VERSION ""

NS_ :

BS_:

BU_: PowertrainControlModule AtmosphericSensor SafetyRestraintSystem2 Aftertreatment_2_GasOutlet Aftertreatment_2_GasIntake DieselParticulateFilterControl Turbocharger SafetyRestraintSystem1 CabDisplay2 Aftertreatment_1_GasOutlet Aftertreatment_1_GasIntake OnBoardDataLogger OffBoardDiagnosticTool2 OffBoardDiagnosticTool1 FileServer ParkingBrakeController SeatController2 FanDriveController SteeringColumnUnit CommunicationUnitRadio CommunicationUnitSatellite CommunicationUnitCellular PropulsionBatteryCharger ChassisController2 ChassisController1 EngineValveControl AuxiliaryHeater2 AuxiliaryHeater1 ClutchUnit RampControl InformationSystem1 SuspensionSystemController2 OilSensor VehicleDynamicStability ExhaustEmissionController TransmissionDisplay2 TransmissionDisplay1 ClimateControl2 WaterPumpController RearAxleSteeringController LightingOperatorControl SeatController1 IgnitionController2 IgnitionController1 TirePressureController CabController2 CabController1 PneumaticSystemController SuspensionSystemController1 HydraulicPumpController EnduranceBrakingSystem RetarderExhaustEngine2 OnBoardDiagnosticUnit HeadwayController RetarderExhaustEngine1 CabDisplay1 ManagementComputer VirtualTerminal OffVehicleGateway PowerTakeOffFront HitchControl AuxiliaryValveControl BodyController TractorTrailerBridge1 StarterSystem ElectricalSystem VehicleSecurity VehicleNavigation AerodynamicControl ElectricalChargingSystem ClimateControl1 TripRecorder InstrumentCluster SuspensionDriveAxle2 SuspensionDriveAxle1 SuspensionSteerAxle SteeringController FuelSystem CruiseControl RetarderDriveline RetarderEngine BrakesDriveAxle2 BrakesDriveAxle1 BrakesSystemController BrakesSteerAxle AxleDrive2 AxleDrive1 AxleSteering PowerTakeOff ShiftConsoleSecondary ShiftConsolePrimary Transmission2 Transmission1 Engine2 Engine1

BO_ 2566630654 DCAC_AI4_LD: 8 Vector__XXX
 SG_ TotalDCInputEnergy : 32|32@1+ (100,0) [0|421108121500] "Wh" Vector__XXX
 SG_ TotalDCInputCharge : 0|32@1+ (100,0) [0|421108121500] "Ah" Vector__XXX

BO_ 2566630398 DCAC_AI4_CFG1: 13 Vector__XXX
 SG_ ACSideDefaultFreqCmdSetting : 96|8@1+ (1,0) [0|250] "Hz" Vector__XXX
 SG_ DCSideCurMinLmtSetting : 80|16@1+ (0.05,-3212.75) [-3212.75|0] "A" Vector__XXX
 SG_ DCSideVMaxLmtSetting : 64|16@1+ (0.05,0) [0|3212.75] "V" Vector__XXX
 SG_ ACSideRMSCurMaxLmtSetting : 48|16@1+ (0.03125,0) [0|2007.96875] "A" Vector__XXX
 SG_ ACSideRMSVMaxLmtSetting : 32|16@1+ (0.03125,0) [0|2007.96875] "V" Vector__XXX
 SG_ DCSideCurMaxLmtSetting : 16|16@1+ (0.05,0) [0|3212.75] "A" Vector__XXX
 SG_ DCSideVMinLmtSetting : 0|16@1+ (0.05,0) [0|3212.75] "V" Vector__XXX

BO_ 2365303550 DCAC_AI4_ACL: 8 Vector__XXX
 SG_ DefaultFreqReq : 32|8@1+ (1,0) [0|250] "Hz" Vector__XXX
 SG_ RMSCurMaxLmtReq : 16|16@1+ (0.03125,0) [0|2007.96875] "A" Vector__XXX
 SG_ RMSVMaxLmtReq : 0|16@1+ (0.03125,0) [0|2007.96875] "V" Vector__XXX

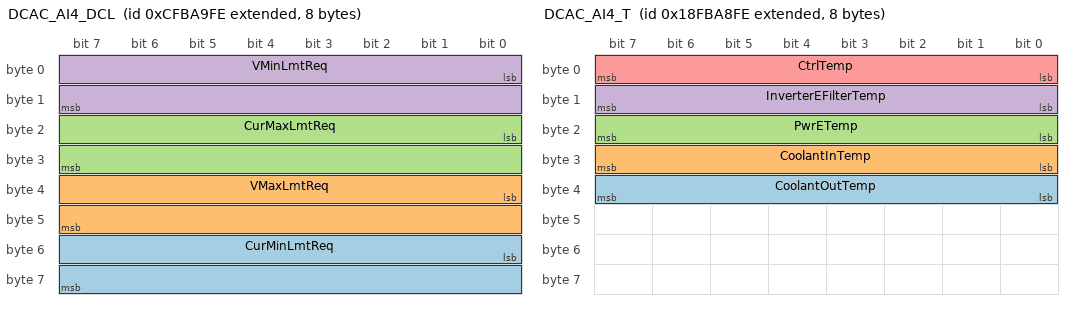
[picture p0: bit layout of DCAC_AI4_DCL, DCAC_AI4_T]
BO_ 2365303294 DCAC_AI4_DCL: 8 Vector__XXX
 SG_ CurMinLmtReq : 48|16@1+ (0.05,-3212.75) [-3212.75|0] "A" Vector__XXX
 SG_ VMaxLmtReq : 32|16@1+ (0.05,0) [0|3212.75] "V" Vector__XXX
 SG_ CurMaxLmtReq : 16|16@1+ (0.05,0) [0|3212.75] "A" Vector__XXX
 SG_ VMinLmtReq : 0|16@1+ (0.05,0) [0|3212.75] "V" Vector__XXX

BO_ 2566629630 DCAC_AI4_T: 8 Vector__XXX
 SG_ CoolantOutTemp : 32|8@1+ (1,-40) [-40|210] "°C" Vector__XXX
 SG_ CoolantInTemp : 24|8@1+ (1,-40) [-40|210] "°C" Vector__XXX
 SG_ PwrETemp : 16|8@1+ (1,-40) [-40|210] "°C" Vector__XXX
 SG_ InverterEFilterTemp : 8|8@1+ (1,-40) [-40|210] "°C" Vector__XXX
 SG_ CtrlTemp : 0|8@1+ (1,-40) [-40|210] "°C" Vector__XXX

BO_ 2566629374 DCAC_AI3_LD: 8 Vector__XXX
 SG_ TotalDCInputEnergy : 32|32@1+ (100,0) [0|421108121500] "Wh" Vector__XXX
 SG_ TotalDCInputCharge : 0|32@1+ (100,0) [0|421108121500] "Ah" Vector__XXX

BO_ 2566629118 DCAC_AI3_CFG1: 13 Vector__XXX
 SG_ ACSideDefaultFreqCmdSetting : 96|8@1+ (1,0) [0|250] "Hz" Vector__XXX
 SG_ DCSideCurMinLmtSetting : 80|16@1+ (0.05,-3212.75) [-3212.75|0] "A" Vector__XXX
 SG_ DCSideVMaxLmtSetting : 64|16@1+ (0.05,0) [0|3212.75] "V" Vector__XXX
 SG_ ACSideRMSCurMaxLmtSetting : 48|16@1+ (0.03125,0) [0|2007.96875] "A" Vector__XXX
 SG_ ACSideRMSVMaxLmtSetting : 32|16@1+ (0.03125,0) [0|2007.96875] "V" Vector__XXX
 SG_ DCSideCurMaxLmtSetting : 16|16@1+ (0.05,0) [0|3212.75] "A" Vector__XXX
 SG_ DCSideVMinLmtSetting : 0|16@1+ (0.05,0) [0|3212.75] "V" Vector__XXX

BO_ 2365302270 DCAC_AI3_ACL: 8 Vector__XXX
 SG_ DefaultFreqReq : 32|8@1+ (1,0) [0|250] "Hz" Vector__XXX
 SG_ RMSCurMaxLmtReq : 16|16@1+ (0.03125,0) [0|2007.96875] "A" Vector__XXX
 SG_ RMSVMaxLmtReq : 0|16@1+ (0.03125,0) [0|2007.96875] "V" Vector__XXX

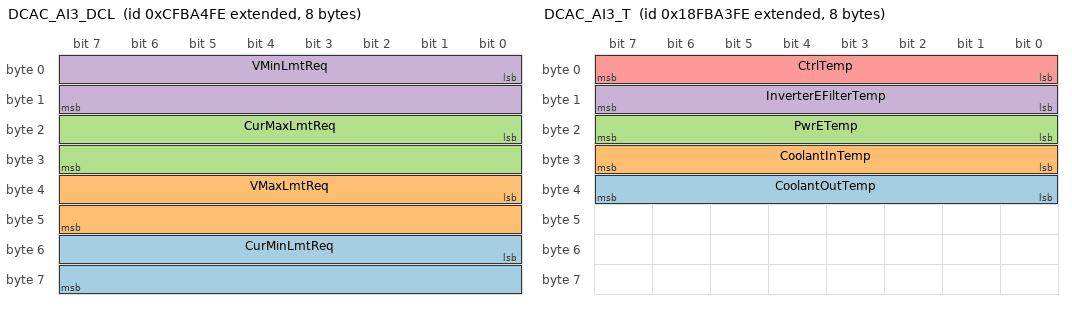
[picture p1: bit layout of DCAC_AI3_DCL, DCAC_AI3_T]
BO_ 2365302014 DCAC_AI3_DCL: 8 Vector__XXX
 SG_ CurMinLmtReq : 48|16@1+ (0.05,-3212.75) [-3212.75|0] "A" Vector__XXX
 SG_ VMaxLmtReq : 32|16@1+ (0.05,0) [0|3212.75] "V" Vector__XXX
 SG_ CurMaxLmtReq : 16|16@1+ (0.05,0) [0|3212.75] "A" Vector__XXX
 SG_ VMinLmtReq : 0|16@1+ (0.05,0) [0|3212.75] "V" Vector__XXX

BO_ 2566628350 DCAC_AI3_T: 8 Vector__XXX
 SG_ CoolantOutTemp : 32|8@1+ (1,-40) [-40|210] "°C" Vector__XXX
 SG_ CoolantInTemp : 24|8@1+ (1,-40) [-40|210] "°C" Vector__XXX
 SG_ PwrETemp : 16|8@1+ (1,-40) [-40|210] "°C" Vector__XXX
 SG_ InverterEFilterTemp : 8|8@1+ (1,-40) [-40|210] "°C" Vector__XXX
 SG_ CtrlTemp : 0|8@1+ (1,-40) [-40|210] "°C" Vector__XXX

BO_ 2566628094 DCAC_AI2_LD: 8 Vector__XXX
 SG_ TotalDCInputEnergy : 32|32@1+ (100,0) [0|421108121500] "Wh" Vector__XXX
 SG_ TotalDCInputCharge : 0|32@1+ (100,0) [0|421108121500] "Ah" Vector__XXX

BO_ 2566627838 DCAC_AI2_CFG1: 13 Vector__XXX
 SG_ ACSideDefaultFreqCmdSetting : 96|8@1+ (1,0) [0|250] "Hz" Vector__XXX
 SG_ DCSideCurMinLmtSetting : 80|16@1+ (0.05,-3212.75) [-3212.75|0] "A" Vector__XXX
 SG_ DCSideVMaxLmtSetting : 64|16@1+ (0.05,0) [0|3212.75] "V" Vector__XXX
 SG_ ACSideRMSCurMaxLmtSetting : 48|16@1+ (0.03125,0) [0|2007.96875] "A" Vector__XXX
 SG_ ACSideRMSVMaxLmtSetting : 32|16@1+ (0.03125,0) [0|2007.96875] "V" Vector__XXX
 SG_ DCSideCurMaxLmtSetting : 16|16@1+ (0.05,0) [0|3212.75] "A" Vector__XXX
 SG_ DCSideVMinLmtSetting : 0|16@1+ (0.05,0) [0|3212.75] "V" Vector__XXX

BO_ 2365300990 DCAC_AI2_ACL: 8 Vector__XXX
 SG_ DefaultFreqReq : 32|8@1+ (1,0) [0|250] "Hz" Vector__XXX
 SG_ RMSCurMaxLmtReq : 16|16@1+ (0.03125,0) [0|2007.96875] "A" Vector__XXX
 SG_ RMSVMaxLmtReq : 0|16@1+ (0.03125,0) [0|2007.96875] "V" Vector__XXX

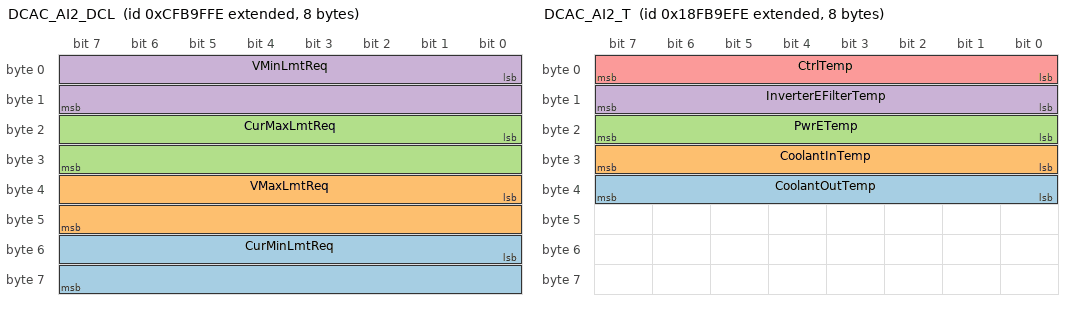
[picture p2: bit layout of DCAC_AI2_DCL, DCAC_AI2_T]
BO_ 2365300734 DCAC_AI2_DCL: 8 Vector__XXX
 SG_ CurMinLmtReq : 48|16@1+ (0.05,-3212.75) [-3212.75|0] "A" Vector__XXX
 SG_ VMaxLmtReq : 32|16@1+ (0.05,0) [0|3212.75] "V" Vector__XXX
 SG_ CurMaxLmtReq : 16|16@1+ (0.05,0) [0|3212.75] "A" Vector__XXX
 SG_ VMinLmtReq : 0|16@1+ (0.05,0) [0|3212.75] "V" Vector__XXX

BO_ 2566627070 DCAC_AI2_T: 8 Vector__XXX
 SG_ CoolantOutTemp : 32|8@1+ (1,-40) [-40|210] "°C" Vector__XXX
 SG_ CoolantInTemp : 24|8@1+ (1,-40) [-40|210] "°C" Vector__XXX
 SG_ PwrETemp : 16|8@1+ (1,-40) [-40|210] "°C" Vector__XXX
 SG_ InverterEFilterTemp : 8|8@1+ (1,-40) [-40|210] "°C" Vector__XXX
 SG_ CtrlTemp : 0|8@1+ (1,-40) [-40|210] "°C" Vector__XXX

BO_ 2566626814 DCAC_AI1_LD: 8 Vector__XXX
 SG_ TotalDCInputEnergy : 32|32@1+ (100,0) [0|421108121500] "Wh" Vector__XXX
 SG_ TotalDCInputCharge : 0|32@1+ (100,0) [0|421108121500] "Ah" Vector__XXX

BO_ 2566626558 DCAC_AI1_CFG1: 13 Vector__XXX
 SG_ ACSideDefaultFreqCmdSetting : 96|8@1+ (1,0) [0|250] "Hz" Vector__XXX
 SG_ DCSideCurMinLmtSetting : 80|16@1+ (0.05,-3212.75) [-3212.75|0] "A" Vector__XXX
 SG_ DCSideVMaxLmtSetting : 64|16@1+ (0.05,0) [0|3212.75] "V" Vector__XXX
 SG_ ACSideRMSCurMaxLmtSetting : 48|16@1+ (0.03125,0) [0|2007.96875] "A" Vector__XXX
 SG_ ACSideRMSVMaxLmtSetting : 32|16@1+ (0.03125,0) [0|2007.96875] "V" Vector__XXX
 SG_ DCSideCurMaxLmtSetting : 16|16@1+ (0.05,0) [0|3212.75] "A" Vector__XXX
 SG_ DCSideVMinLmtSetting : 0|16@1+ (0.05,0) [0|3212.75] "V" Vector__XXX

BO_ 2365299710 DCAC_AI1_ACL: 8 Vector__XXX
 SG_ DefaultFreqReq : 32|8@1+ (1,0) [0|250] "Hz" Vector__XXX
 SG_ RMSCurMaxLmtReq : 16|16@1+ (0.03125,0) [0|2007.96875] "A" Vector__XXX
 SG_ RMSVMaxLmtReq : 0|16@1+ (0.03125,0) [0|2007.96875] "V" Vector__XXX

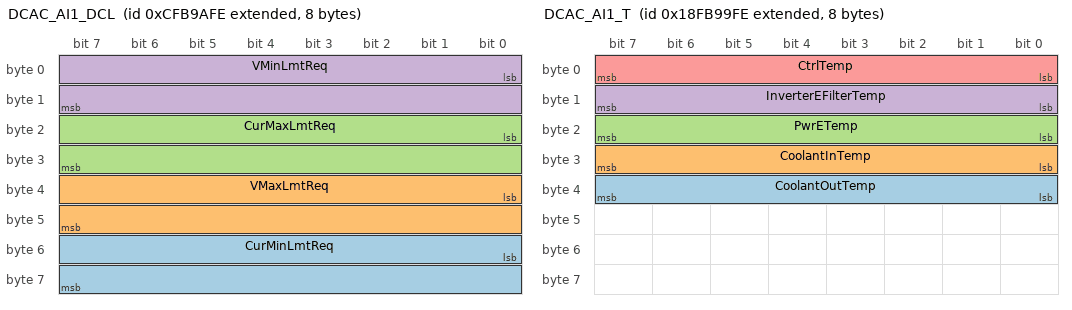
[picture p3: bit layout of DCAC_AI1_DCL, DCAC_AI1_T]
BO_ 2365299454 DCAC_AI1_DCL: 8 Vector__XXX
 SG_ CurMinLmtReq : 48|16@1+ (0.05,-3212.75) [-3212.75|0] "A" Vector__XXX
 SG_ VMaxLmtReq : 32|16@1+ (0.05,0) [0|3212.75] "V" Vector__XXX
 SG_ CurMaxLmtReq : 16|16@1+ (0.05,0) [0|3212.75] "A" Vector__XXX
 SG_ VMinLmtReq : 0|16@1+ (0.05,0) [0|3212.75] "V" Vector__XXX

BO_ 2566625790 DCAC_AI1_T: 8 Vector__XXX
 SG_ CoolantOutTemp : 32|8@1+ (1,-40) [-40|210] "°C" Vector__XXX
 SG_ CoolantInTemp : 24|8@1+ (1,-40) [-40|210] "°C" Vector__XXX
 SG_ PwrETemp : 16|8@1+ (1,-40) [-40|210] "°C" Vector__XXX
 SG_ InverterEFilterTemp : 8|8@1+ (1,-40) [-40|210] "°C" Vector__XXX
 SG_ CtrlTemp : 0|8@1+ (1,-40) [-40|210] "°C" Vector__XXX

BO_ 2633734398 EO2: 8 Vector__XXX
 SG_ EngActualExh2O2 : 0|16@1+ (0.0025,0) [0|160.6375] "%" Vector__XXX

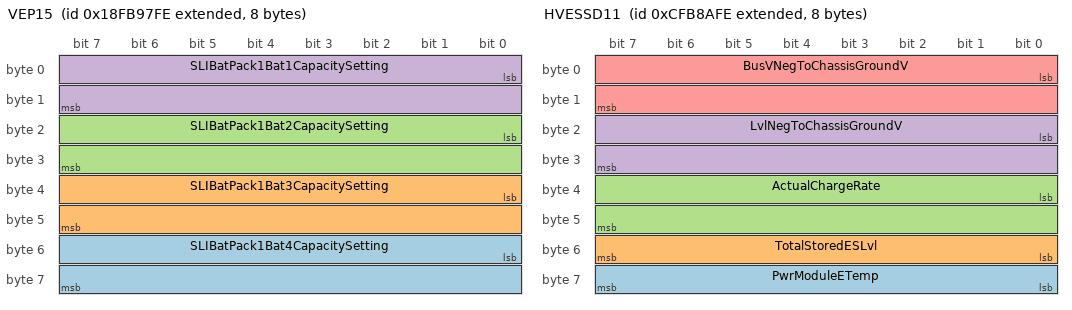
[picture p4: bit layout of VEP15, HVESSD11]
BO_ 2566625278 VEP15: 8 Vector__XXX
 SG_ SLIBatPack1Bat4CapacitySetting : 48|16@1+ (1,0) [0|64255] "Ah" Vector__XXX
 SG_ SLIBatPack1Bat3CapacitySetting : 32|16@1+ (1,0) [0|64255] "Ah" Vector__XXX
 SG_ SLIBatPack1Bat2CapacitySetting : 16|16@1+ (1,0) [0|64255] "Ah" Vector__XXX
 SG_ SLIBatPack1Bat1CapacitySetting : 0|16@1+ (1,0) [0|64255] "Ah" Vector__XXX

BO_ 2566625022 EI3: 8 Vector__XXX
 SG_ ExhManifoldBank1Press2 : 16|16@1+ (0.0078125,-250) [-250|251.9921875] "kPa" Vector__XXX
 SG_ InstantaneousEstEngPwrRateLmt : 0|16@1+ (0.125,0) [0|8031.875] "kW/s" Vector__XXX

BO_ 2566624766 HOURS2: 8 Vector__XXX
 SG_ IdleMnmgtActiveTotalTime : 0|32@1+ (0.05,0) [0|210554060.75] "h" Vector__XXX

BO_ 2566624510 EEC22: 8 Vector__XXX
 SG_ TotalNumOfCrankAttempts : 16|32@1+ (1,0) [0|4211081215] "" Vector__XXX
 SG_ EGR1CoolerInPress : 0|16@1+ (5,0) [0|321275] "kPa" Vector__XXX

BO_ 2365297662 DCDC1V: 8 Vector__XXX
 SG_ OneCtrlInputSLIV : 16|16@1+ (0.05,0) [0|3212.75] "V" Vector__XXX
 SG_ OneCtrlInputIgntV : 0|16@1+ (0.05,0) [0|3212.75] "V" Vector__XXX

BO_ 2365297406 DCDC2V: 8 Vector__XXX
 SG_ TwoCtrlInputSLIV : 16|16@1+ (0.05,0) [0|3212.75] "V" Vector__XXX
 SG_ TwoCtrlInputIgntV : 0|16@1+ (0.05,0) [0|3212.75] "V" Vector__XXX

BO_ 2365297150 DCDC3V: 8 Vector__XXX
 SG_ ThreeCtrlInputSLIV : 16|16@1+ (0.05,0) [0|3212.75] "V" Vector__XXX
 SG_ ThreeCtrlInputIgntV : 0|16@1+ (0.05,0) [0|3212.75] "V" Vector__XXX

BO_ 2365296894 DCDC4V: 8 Vector__XXX
 SG_ FourCtrlInputSLIV : 16|16@1+ (0.05,0) [0|3212.75] "V" Vector__XXX
 SG_ FourCtrlInputIgntV : 0|16@1+ (0.05,0) [0|3212.75] "V" Vector__XXX

BO_ 2566623230 EMEFS: 8 Vector__XXX
 SG_ TripEstFuelSaved : 32|32@1+ (0.5,0) [0|2105540607.5] "l" Vector__XXX
 SG_ TotalEstFuelSaved : 0|32@1+ (0.5,0) [0|2105540607.5] "l" Vector__XXX

BO_ 2566622974 EMFU: 8 Vector__XXX
 SG_ TripFuelUsed : 32|32@1+ (0.5,0) [0|2105540607.5] "l" Vector__XXX
 SG_ TotalFuelUsed : 0|32@1+ (0.5,0) [0|2105540607.5] "l" Vector__XXX

BO_ 2566622718 EMAH: 8 Vector__XXX
 SG_ TripHoursActive : 32|32@1+ (0.05,0) [0|210554060.75] "h" Vector__XXX
 SG_ TotalHoursActive : 0|32@1+ (0.05,0) [0|210554060.75] "h" Vector__XXX

BO_ 2566622462 EMEIFSR: 8 Vector__XXX
 SG_ Percent : 16|16@1+ (0.0025,0) [0|160.6375] "%" Vector__XXX
 SG_ RateAbsolute : 0|16@1+ (0.05,0) [0|3212.75] "l/h" Vector__XXX

BO_ 2566622206 EMIH: 8 Vector__XXX
 SG_ TripHoursInactive : 32|32@1+ (0.05,0) [0|210554060.75] "h" Vector__XXX
 SG_ TotalHoursInactive : 0|32@1+ (0.05,0) [0|210554060.75] "h" Vector__XXX

BO_ 2365295358 HVESSD11: 8 Vector__XXX
 SG_ PwrModuleETemp : 56|8@1+ (1,-40) [-40|210] "°C" Vector__XXX
 SG_ TotalStoredESLvl : 48|8@1+ (0.4,0) [0|100] "%" Vector__XXX
 SG_ ActualChargeRate : 32|16@1+ (0.05,0) [0|3212.75] "kW" Vector__XXX
 SG_ LvlNegToChassisGroundV : 16|16@1+ (0.05,0) [0|3212.75] "V" Vector__XXX
 SG_ BusVNegToChassisGroundV : 0|16@1+ (0.05,0) [0|3212.75] "V" Vector__XXX

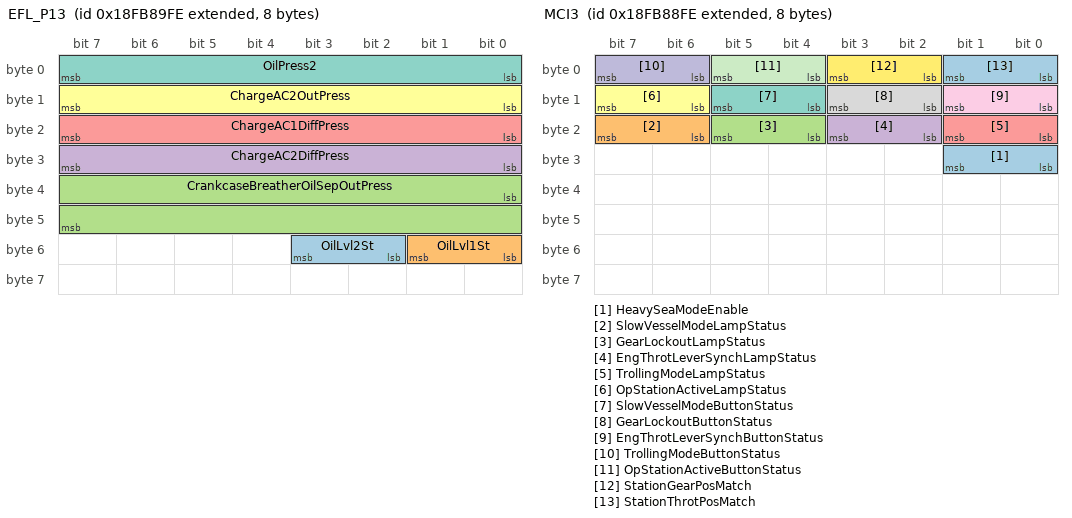
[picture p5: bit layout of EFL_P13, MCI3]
BO_ 2566621694 EFL_P13: 8 Vector__XXX
 SG_ OilLvl2St : 50|2@1+ (1,0) [0|3] "" Vector__XXX
 SG_ OilLvl1St : 48|2@1+ (1,0) [0|3] "" Vector__XXX
 SG_ CrankcaseBreatherOilSepOutPress : 32|16@1+ (0.0078125,-250) [-250|251.9921875] "kPa" Vector__XXX
 SG_ ChargeAC2DiffPress : 24|8@1+ (0.5,0) [0|125] "kPa" Vector__XXX
 SG_ ChargeAC1DiffPress : 16|8@1+ (0.5,0) [0|125] "kPa" Vector__XXX
 SG_ ChargeAC2OutPress : 8|8@1+ (2,0) [0|500] "kPa" Vector__XXX
 SG_ OilPress2 : 0|8@1+ (4,0) [0|1000] "kPa" Vector__XXX

BO_ 2566621438 MCI3: 8 Vector__XXX
 SG_ HeavySeaModeEnable : 24|2@1+ (1,0) [0|3] "" Vector__XXX
 SG_ SlowVesselModeLampStatus : 22|2@1+ (1,0) [0|3] "" Vector__XXX
 SG_ GearLockoutLampStatus : 20|2@1+ (1,0) [0|3] "" Vector__XXX
 SG_ EngThrotLeverSynchLampStatus : 18|2@1+ (1,0) [0|3] "" Vector__XXX
 SG_ TrollingModeLampStatus : 16|2@1+ (1,0) [0|3] "" Vector__XXX
 SG_ OpStationActiveLampStatus : 14|2@1+ (1,0) [0|3] "" Vector__XXX
 SG_ SlowVesselModeButtonStatus : 12|2@1+ (1,0) [0|3] "" Vector__XXX
 SG_ GearLockoutButtonStatus : 10|2@1+ (1,0) [0|3] "" Vector__XXX
 SG_ EngThrotLeverSynchButtonStatus : 8|2@1+ (1,0) [0|3] "" Vector__XXX
 SG_ TrollingModeButtonStatus : 6|2@1+ (1,0) [0|3] "" Vector__XXX
 SG_ OpStationActiveButtonStatus : 4|2@1+ (1,0) [0|3] "" Vector__XXX
 SG_ StationGearPosMatch : 2|2@1+ (1,0) [0|3] "" Vector__XXX
 SG_ StationThrotPosMatch : 0|2@1+ (1,0) [0|3] "" Vector__XXX

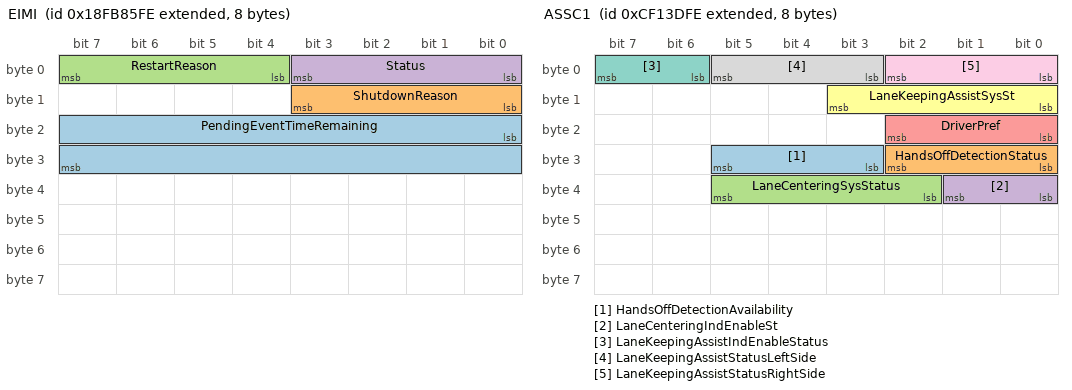
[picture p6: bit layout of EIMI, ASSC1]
BO_ 2566620670 EIMI: 8 Vector__XXX
 SG_ PendingEventTimeRemaining : 16|16@1+ (1,0) [0|64255] "s" Vector__XXX
 SG_ ShutdownReason : 8|4@1+ (1,0) [0|15] "" Vector__XXX
 SG_ RestartReason : 4|4@1+ (1,0) [0|15] "" Vector__XXX
 SG_ Status : 0|4@1+ (1,0) [0|15] "" Vector__XXX

BO_ 2364620286 ASSC1: 8 Vector__XXX
 SG_ HandsOffDetectionAvailability : 27|3@1+ (1,0) [0|7] "" Vector__XXX
 SG_ HandsOffDetectionStatus : 24|3@1+ (1,0) [0|7] "" Vector__XXX
 SG_ LaneCenteringSysStatus : 34|4@1+ (1,0) [0|15] "" Vector__XXX
 SG_ LaneCenteringIndEnableSt : 32|2@1+ (1,0) [0|3] "" Vector__XXX
 SG_ DriverPref : 16|3@1+ (1,0) [0|7] "" Vector__XXX
 SG_ LaneKeepingAssistSysSt : 8|4@1+ (1,0) [0|15] "" Vector__XXX
 SG_ LaneKeepingAssistIndEnableStatus : 6|2@1+ (1,0) [0|3] "" Vector__XXX
 SG_ LaneKeepingAssistStatusLeftSide : 3|3@1+ (1,0) [0|7] "" Vector__XXX
 SG_ LaneKeepingAssistStatusRightSide : 0|3@1+ (1,0) [0|7] "" Vector__XXX

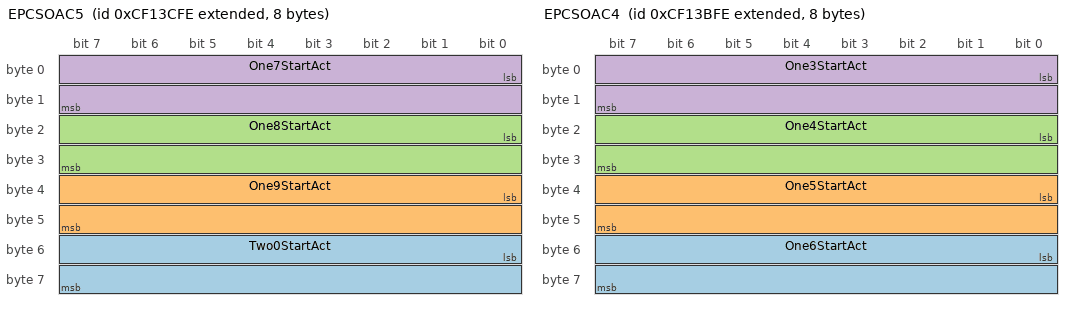
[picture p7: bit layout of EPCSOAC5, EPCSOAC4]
BO_ 2364620030 EPCSOAC5: 8 Vector__XXX
 SG_ Two0StartAct : 48|16@1+ (0.0078125,-400) [-400|101.9921875] "deg" Vector__XXX
 SG_ One9StartAct : 32|16@1+ (0.0078125,-400) [-400|101.9921875] "deg" Vector__XXX
 SG_ One8StartAct : 16|16@1+ (0.0078125,-400) [-400|101.9921875] "deg" Vector__XXX
 SG_ One7StartAct : 0|16@1+ (0.0078125,-400) [-400|101.9921875] "deg" Vector__XXX

BO_ 2364619774 EPCSOAC4: 8 Vector__XXX
 SG_ One6StartAct : 48|16@1+ (0.0078125,-400) [-400|101.9921875] "deg" Vector__XXX
 SG_ One5StartAct : 32|16@1+ (0.0078125,-400) [-400|101.9921875] "deg" Vector__XXX
 SG_ One4StartAct : 16|16@1+ (0.0078125,-400) [-400|101.9921875] "deg" Vector__XXX
 SG_ One3StartAct : 0|16@1+ (0.0078125,-400) [-400|101.9921875] "deg" Vector__XXX

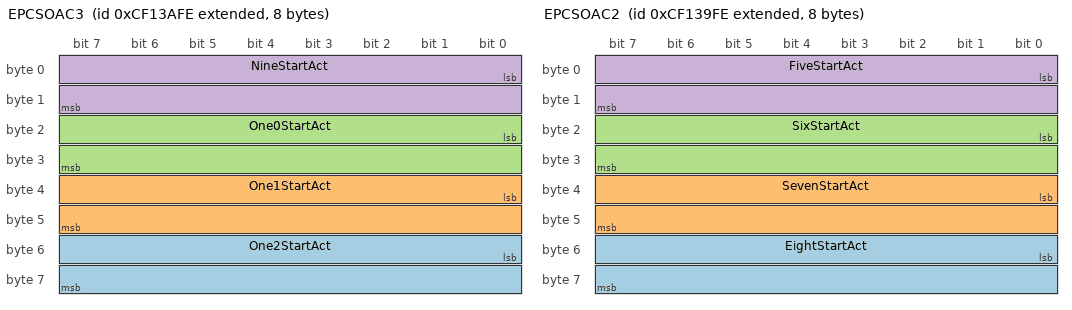
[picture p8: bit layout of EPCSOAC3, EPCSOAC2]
BO_ 2364619518 EPCSOAC3: 8 Vector__XXX
 SG_ One2StartAct : 48|16@1+ (0.0078125,-400) [-400|101.9921875] "deg" Vector__XXX
 SG_ One1StartAct : 32|16@1+ (0.0078125,-400) [-400|101.9921875] "deg" Vector__XXX
 SG_ One0StartAct : 16|16@1+ (0.0078125,-400) [-400|101.9921875] "deg" Vector__XXX
 SG_ NineStartAct : 0|16@1+ (0.0078125,-400) [-400|101.9921875] "deg" Vector__XXX

BO_ 2364619262 EPCSOAC2: 8 Vector__XXX
 SG_ EightStartAct : 48|16@1+ (0.0078125,-400) [-400|101.9921875] "deg" Vector__XXX
 SG_ SevenStartAct : 32|16@1+ (0.0078125,-400) [-400|101.9921875] "deg" Vector__XXX
 SG_ SixStartAct : 16|16@1+ (0.0078125,-400) [-400|101.9921875] "deg" Vector__XXX
 SG_ FiveStartAct : 0|16@1+ (0.0078125,-400) [-400|101.9921875] "deg" Vector__XXX

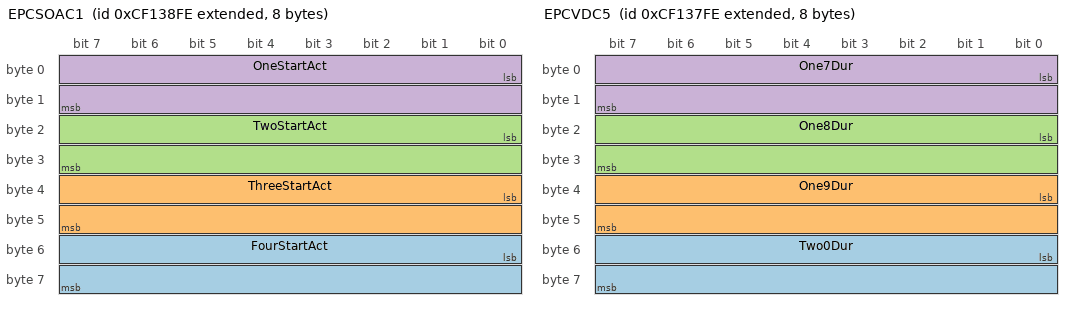
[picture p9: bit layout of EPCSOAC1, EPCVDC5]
BO_ 2364619006 EPCSOAC1: 8 Vector__XXX
 SG_ FourStartAct : 48|16@1+ (0.0078125,-400) [-400|101.9921875] "deg" Vector__XXX
 SG_ ThreeStartAct : 32|16@1+ (0.0078125,-400) [-400|101.9921875] "deg" Vector__XXX
 SG_ TwoStartAct : 16|16@1+ (0.0078125,-400) [-400|101.9921875] "deg" Vector__XXX
 SG_ OneStartAct : 0|16@1+ (0.0078125,-400) [-400|101.9921875] "deg" Vector__XXX

BO_ 2364618750 EPCVDC5: 8 Vector__XXX
 SG_ Two0Dur : 48|16@1+ (2,0) [0|128510] "µs" Vector__XXX
 SG_ One9Dur : 32|16@1+ (2,0) [0|128510] "µs" Vector__XXX
 SG_ One8Dur : 16|16@1+ (2,0) [0|128510] "µs" Vector__XXX
 SG_ One7Dur : 0|16@1+ (2,0) [0|128510] "µs" Vector__XXX

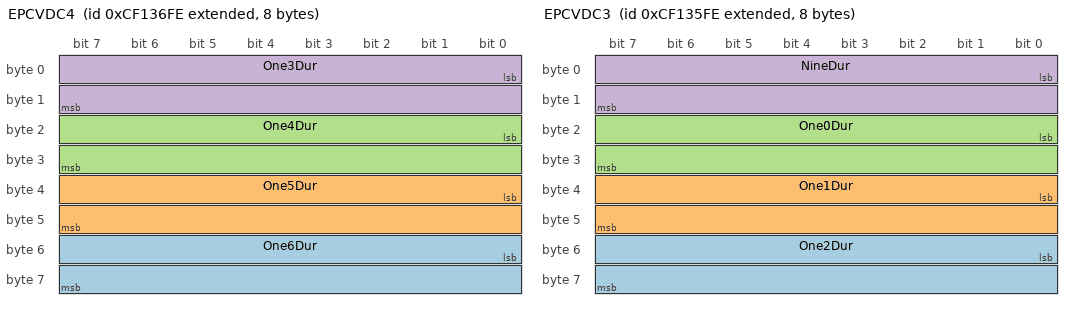
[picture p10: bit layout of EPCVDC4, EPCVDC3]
BO_ 2364618494 EPCVDC4: 8 Vector__XXX
 SG_ One6Dur : 48|16@1+ (2,0) [0|128510] "µs" Vector__XXX
 SG_ One5Dur : 32|16@1+ (2,0) [0|128510] "µs" Vector__XXX
 SG_ One4Dur : 16|16@1+ (2,0) [0|128510] "µs" Vector__XXX
 SG_ One3Dur : 0|16@1+ (2,0) [0|128510] "µs" Vector__XXX

BO_ 2364618238 EPCVDC3: 8 Vector__XXX
 SG_ One2Dur : 48|16@1+ (2,0) [0|128510] "µs" Vector__XXX
 SG_ One1Dur : 32|16@1+ (2,0) [0|128510] "µs" Vector__XXX
 SG_ One0Dur : 16|16@1+ (2,0) [0|128510] "µs" Vector__XXX
 SG_ NineDur : 0|16@1+ (2,0) [0|128510] "µs" Vector__XXX

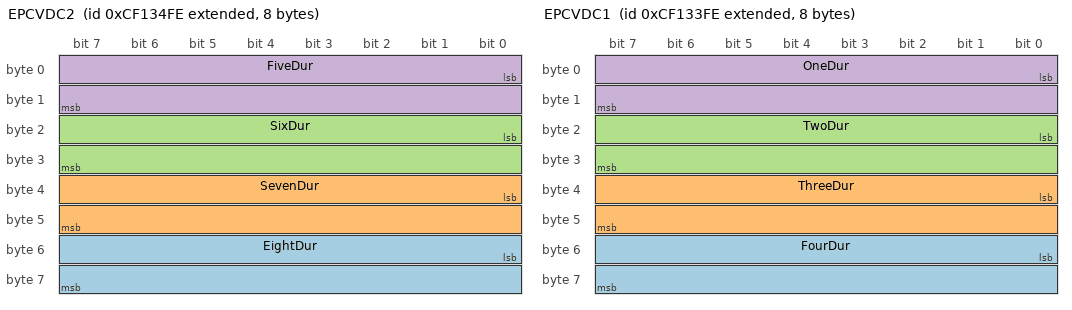
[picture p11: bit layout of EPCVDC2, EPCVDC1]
BO_ 2364617982 EPCVDC2: 8 Vector__XXX
 SG_ EightDur : 48|16@1+ (2,0) [0|128510] "µs" Vector__XXX
 SG_ SevenDur : 32|16@1+ (2,0) [0|128510] "µs" Vector__XXX
 SG_ SixDur : 16|16@1+ (2,0) [0|128510] "µs" Vector__XXX
 SG_ FiveDur : 0|16@1+ (2,0) [0|128510] "µs" Vector__XXX

BO_ 2364617726 EPCVDC1: 8 Vector__XXX
 SG_ FourDur : 48|16@1+ (2,0) [0|128510] "µs" Vector__XXX
 SG_ ThreeDur : 32|16@1+ (2,0) [0|128510] "µs" Vector__XXX
 SG_ TwoDur : 16|16@1+ (2,0) [0|128510] "µs" Vector__XXX
 SG_ OneDur : 0|16@1+ (2,0) [0|128510] "µs" Vector__XXX

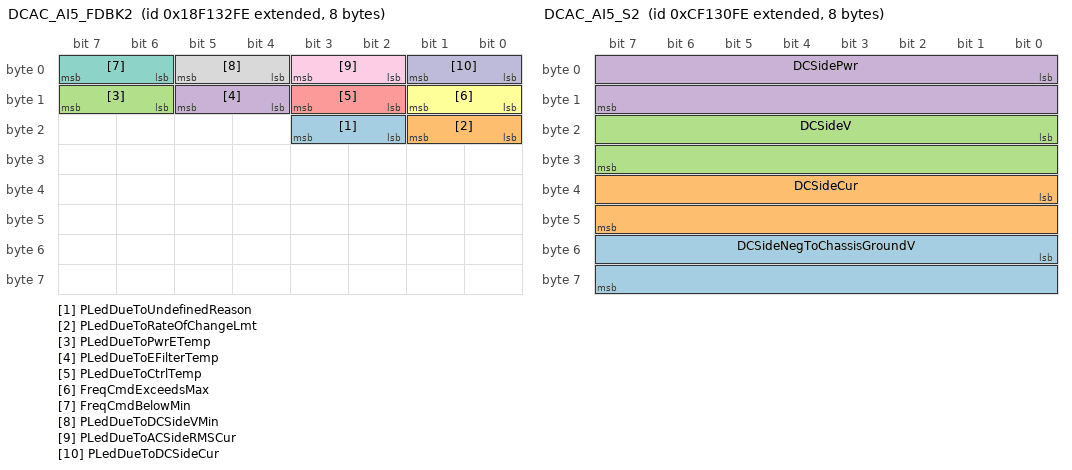
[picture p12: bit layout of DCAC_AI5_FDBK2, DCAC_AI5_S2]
BO_ 2565944062 DCAC_AI5_FDBK2: 8 Vector__XXX
 SG_ PLedDueToUndefinedReason : 18|2@1+ (1,0) [0|3] "" Vector__XXX
 SG_ PLedDueToRateOfChangeLmt : 16|2@1+ (1,0) [0|3] "" Vector__XXX
 SG_ PLedDueToPwrETemp : 14|2@1+ (1,0) [0|3] "" Vector__XXX
 SG_ PLedDueToEFilterTemp : 12|2@1+ (1,0) [0|3] "" Vector__XXX
 SG_ PLedDueToCtrlTemp : 10|2@1+ (1,0) [0|3] "" Vector__XXX
 SG_ FreqCmdExceedsMax : 8|2@1+ (1,0) [0|3] "" Vector__XXX
 SG_ FreqCmdBelowMin : 6|2@1+ (1,0) [0|3] "" Vector__XXX
 SG_ PLedDueToDCSideVMin : 4|2@1+ (1,0) [0|3] "" Vector__XXX
 SG_ PLedDueToACSideRMSCur : 2|2@1+ (1,0) [0|3] "" Vector__XXX
 SG_ PLedDueToDCSideCur : 0|2@1+ (1,0) [0|3] "" Vector__XXX

BO_ 2364617214 DCAC_AI5_V: 8 Vector__XXX
 SG_ SLIV : 16|16@1+ (0.05,0) [0|3212.75] "V" Vector__XXX
 SG_ IgntV : 0|16@1+ (0.05,0) [0|3212.75] "V" Vector__XXX

BO_ 2364616958 DCAC_AI5_S2: 8 Vector__XXX
 SG_ DCSideNegToChassisGroundV : 48|16@1+ (0.05,0) [0|3212.75] "V" Vector__XXX
 SG_ DCSideCur : 32|16@1+ (0.0625,0) [0|4015.9375] "A" Vector__XXX
 SG_ DCSideV : 16|16@1+ (0.05,0) [0|3212.75] "V" Vector__XXX
 SG_ DCSidePwr : 0|16@1+ (0.0625,0) [0|4015.9375] "kW" Vector__XXX

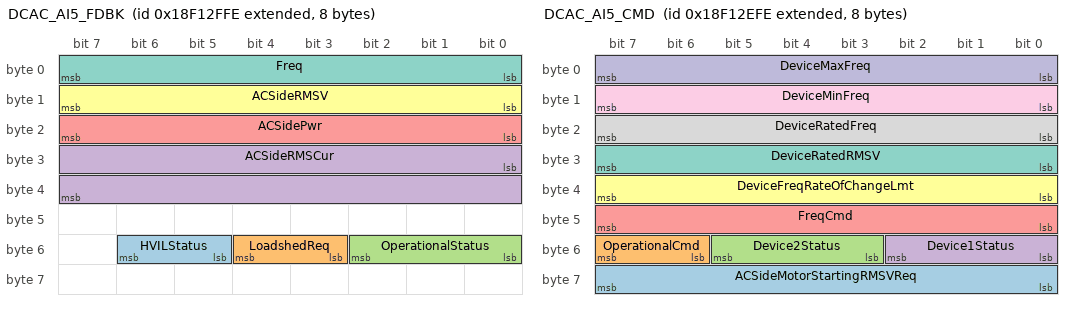
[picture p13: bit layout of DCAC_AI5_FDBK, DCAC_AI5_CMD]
BO_ 2565943294 DCAC_AI5_FDBK: 8 Vector__XXX
 SG_ HVILStatus : 53|2@1+ (1,0) [0|3] "" Vector__XXX
 SG_ LoadshedReq : 51|2@1+ (1,0) [0|3] "" Vector__XXX
 SG_ OperationalStatus : 48|3@1+ (1,0) [0|7] "" Vector__XXX
 SG_ ACSideRMSCur : 24|16@1+ (0.03125,0) [0|2007.96875] "A" Vector__XXX
 SG_ ACSidePwr : 16|8@1+ (0.1,0) [0|25] "kW" Vector__XXX
 SG_ ACSideRMSV : 8|8@1+ (2,0) [0|500] "V" Vector__XXX
 SG_ Freq : 0|8@1+ (1,0) [0|250] "Hz" Vector__XXX

BO_ 2565943038 DCAC_AI5_CMD: 8 Vector__XXX
 SG_ ACSideMotorStartingRMSVReq : 56|8@1+ (2,0) [0|500] "V" Vector__XXX
 SG_ OperationalCmd : 54|2@1+ (1,0) [0|3] "" Vector__XXX
 SG_ Device2Status : 51|3@1+ (1,0) [0|7] "" Vector__XXX
 SG_ Device1Status : 48|3@1+ (1,0) [0|7] "" Vector__XXX
 SG_ FreqCmd : 40|8@1+ (1,0) [0|250] "Hz" Vector__XXX
 SG_ DeviceFreqRateOfChangeLmt : 32|8@1+ (2,0) [0|500] "Hz/s" Vector__XXX
 SG_ DeviceRatedRMSV : 24|8@1+ (2,0) [0|500] "V" Vector__XXX
 SG_ DeviceRatedFreq : 16|8@1+ (1,0) [0|250] "Hz" Vector__XXX
 SG_ DeviceMinFreq : 8|8@1+ (1,0) [0|250] "Hz" Vector__XXX
 SG_ DeviceMaxFreq : 0|8@1+ (1,0) [0|250] "Hz" Vector__XXX

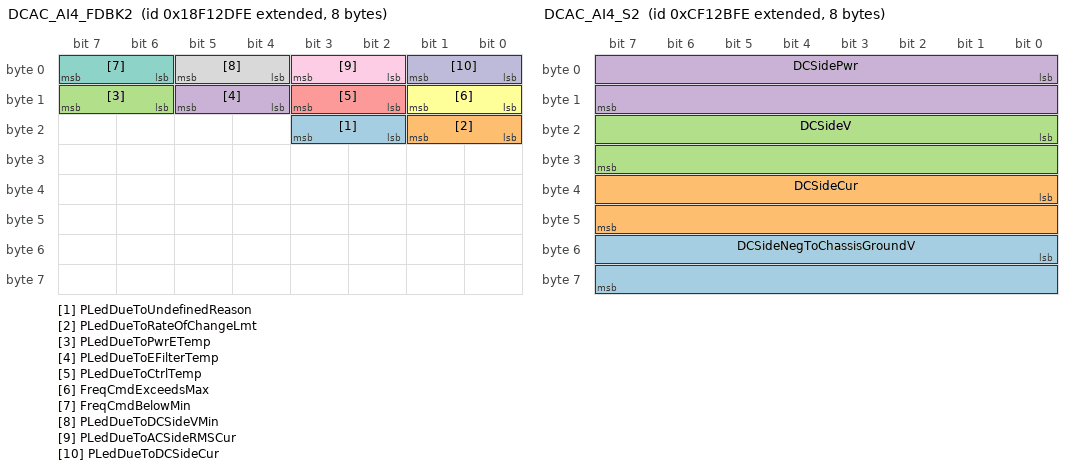
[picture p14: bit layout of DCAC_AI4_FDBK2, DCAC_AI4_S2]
BO_ 2565942782 DCAC_AI4_FDBK2: 8 Vector__XXX
 SG_ PLedDueToUndefinedReason : 18|2@1+ (1,0) [0|3] "" Vector__XXX
 SG_ PLedDueToRateOfChangeLmt : 16|2@1+ (1,0) [0|3] "" Vector__XXX
 SG_ PLedDueToPwrETemp : 14|2@1+ (1,0) [0|3] "" Vector__XXX
 SG_ PLedDueToEFilterTemp : 12|2@1+ (1,0) [0|3] "" Vector__XXX
 SG_ PLedDueToCtrlTemp : 10|2@1+ (1,0) [0|3] "" Vector__XXX
 SG_ FreqCmdExceedsMax : 8|2@1+ (1,0) [0|3] "" Vector__XXX
 SG_ FreqCmdBelowMin : 6|2@1+ (1,0) [0|3] "" Vector__XXX
 SG_ PLedDueToDCSideVMin : 4|2@1+ (1,0) [0|3] "" Vector__XXX
 SG_ PLedDueToACSideRMSCur : 2|2@1+ (1,0) [0|3] "" Vector__XXX
 SG_ PLedDueToDCSideCur : 0|2@1+ (1,0) [0|3] "" Vector__XXX

BO_ 2364615934 DCAC_AI4_V: 8 Vector__XXX
 SG_ SLIV : 16|16@1+ (0.05,0) [0|3212.75] "V" Vector__XXX
 SG_ IgntV : 0|16@1+ (0.05,0) [0|3212.75] "V" Vector__XXX

BO_ 2364615678 DCAC_AI4_S2: 8 Vector__XXX
 SG_ DCSideNegToChassisGroundV : 48|16@1+ (0.05,0) [0|3212.75] "V" Vector__XXX
 SG_ DCSideCur : 32|16@1+ (0.0625,0) [0|4015.9375] "A" Vector__XXX
 SG_ DCSideV : 16|16@1+ (0.05,0) [0|3212.75] "V" Vector__XXX
 SG_ DCSidePwr : 0|16@1+ (0.0625,0) [0|4015.9375] "kW" Vector__XXX

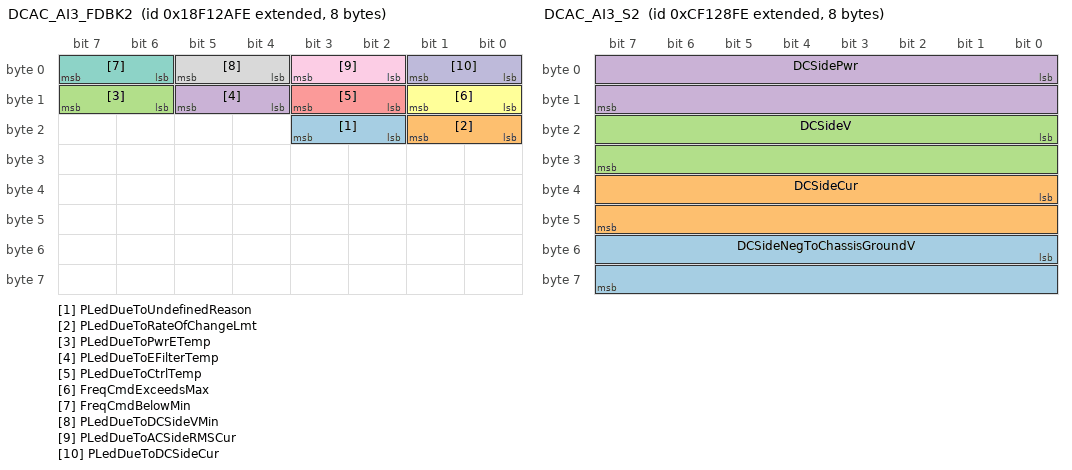
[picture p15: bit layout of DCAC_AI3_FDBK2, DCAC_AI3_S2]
BO_ 2565942014 DCAC_AI3_FDBK2: 8 Vector__XXX
 SG_ PLedDueToUndefinedReason : 18|2@1+ (1,0) [0|3] "" Vector__XXX
 SG_ PLedDueToRateOfChangeLmt : 16|2@1+ (1,0) [0|3] "" Vector__XXX
 SG_ PLedDueToPwrETemp : 14|2@1+ (1,0) [0|3] "" Vector__XXX
 SG_ PLedDueToEFilterTemp : 12|2@1+ (1,0) [0|3] "" Vector__XXX
 SG_ PLedDueToCtrlTemp : 10|2@1+ (1,0) [0|3] "" Vector__XXX
 SG_ FreqCmdExceedsMax : 8|2@1+ (1,0) [0|3] "" Vector__XXX
 SG_ FreqCmdBelowMin : 6|2@1+ (1,0) [0|3] "" Vector__XXX
 SG_ PLedDueToDCSideVMin : 4|2@1+ (1,0) [0|3] "" Vector__XXX
 SG_ PLedDueToACSideRMSCur : 2|2@1+ (1,0) [0|3] "" Vector__XXX
 SG_ PLedDueToDCSideCur : 0|2@1+ (1,0) [0|3] "" Vector__XXX

BO_ 2364615166 DCAC_AI3_V: 8 Vector__XXX
 SG_ SLIV : 16|16@1+ (0.05,0) [0|3212.75] "V" Vector__XXX
 SG_ IgntV : 0|16@1+ (0.05,0) [0|3212.75] "V" Vector__XXX

BO_ 2364614910 DCAC_AI3_S2: 8 Vector__XXX
 SG_ DCSideNegToChassisGroundV : 48|16@1+ (0.05,0) [0|3212.75] "V" Vector__XXX
 SG_ DCSideCur : 32|16@1+ (0.0625,0) [0|4015.9375] "A" Vector__XXX
 SG_ DCSideV : 16|16@1+ (0.05,0) [0|3212.75] "V" Vector__XXX
 SG_ DCSidePwr : 0|16@1+ (0.0625,0) [0|4015.9375] "kW" Vector__XXX

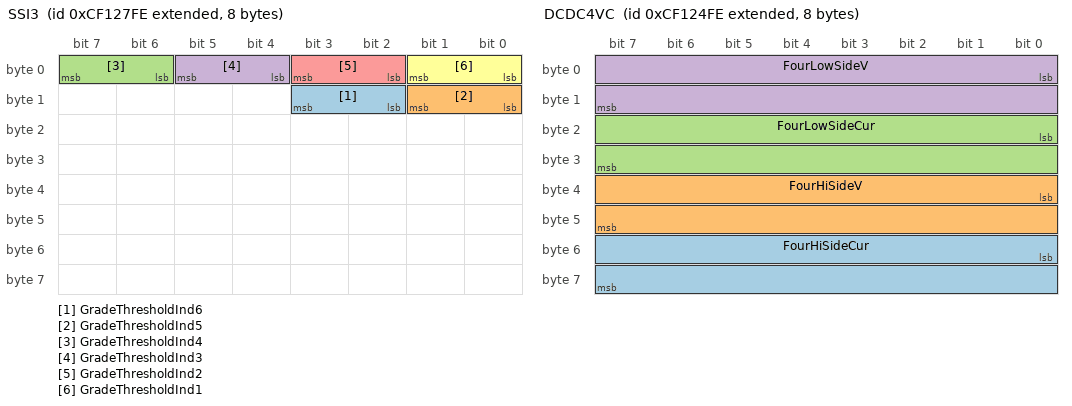
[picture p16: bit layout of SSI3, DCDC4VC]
BO_ 2364614654 SSI3: 8 Vector__XXX
 SG_ GradeThresholdInd6 : 10|2@1+ (1,0) [0|3] "" Vector__XXX
 SG_ GradeThresholdInd5 : 8|2@1+ (1,0) [0|3] "" Vector__XXX
 SG_ GradeThresholdInd4 : 6|2@1+ (1,0) [0|3] "" Vector__XXX
 SG_ GradeThresholdInd3 : 4|2@1+ (1,0) [0|3] "" Vector__XXX
 SG_ GradeThresholdInd2 : 2|2@1+ (1,0) [0|3] "" Vector__XXX
 SG_ GradeThresholdInd1 : 0|2@1+ (1,0) [0|3] "" Vector__XXX

BO_ 2364614398 DCDC4S2: 8 Vector__XXX
 SG_ FourHiSideNegToChassisGroundV : 32|16@1+ (0.05,0) [0|3212.75] "V" Vector__XXX
 SG_ FourHiSidePwr : 16|16@1+ (0.05,-1600) [-1600|1612.75] "kW" Vector__XXX
 SG_ FourLowSidePwr : 0|16@1+ (0.05,-1600) [-1600|1612.75] "kW" Vector__XXX

BO_ 2364614142 DCDC4SBS: 8 Vector__XXX
 SG_ SLIBatTermTemp : 32|8@1+ (1,-40) [-40|210] "°C" Vector__XXX
 SG_ SLIBatTermCur : 16|16@1+ (0.1,-3212.7) [-3212.7|3212.8] "A" Vector__XXX
 SG_ SLIBatTermV : 0|16@1+ (0.01,0) [0|642.55] "V" Vector__XXX

BO_ 2364613886 DCDC4VC: 8 Vector__XXX
 SG_ FourHiSideCur : 48|16@1+ (0.1,-3212.7) [-3212.7|3212.8] "A" Vector__XXX
 SG_ FourHiSideV : 32|16@1+ (0.05,0) [0|3212.75] "V" Vector__XXX
 SG_ FourLowSideCur : 16|16@1+ (0.1,-3212.7) [-3212.7|3212.8] "A" Vector__XXX
 SG_ FourLowSideV : 0|16@1+ (0.01,0) [0|642.55] "V" Vector__XXX

BO_ 2364613630 DCDC4OS: 8 Vector__XXX
 SG_ DCDC4OperatingStatusCRC : 56|8@1+ (1,0) [0|255] "" Vector__XXX
 SG_ DCDC4OperatingStatusCounter : 52|4@1+ (1,0) [0|15] "" Vector__XXX
 SG_ FourPLDueToUndefinedReason : 32|2@1+ (1,0) [0|3] "" Vector__XXX
 SG_ FourPLDueToSLIBatTermTemp : 30|2@1+ (1,0) [0|3] "" Vector__XXX
 SG_ FourPLDueToSLIBatTermCur : 28|2@1+ (1,0) [0|3] "" Vector__XXX
 SG_ FourPLDueToSLIBatTermV : 26|2@1+ (1,0) [0|3] "" Vector__XXX
 SG_ FourPLDueToPwrETemp : 24|2@1+ (1,0) [0|3] "" Vector__XXX
 SG_ FourPLDueToEFilterTemp : 22|2@1+ (1,0) [0|3] "" Vector__XXX
 SG_ FourPLDueToConvTemp : 20|2@1+ (1,0) [0|3] "" Vector__XXX
 SG_ FourPLDueToLowSideVMax : 18|2@1+ (1,0) [0|3] "" Vector__XXX
 SG_ FourPLDueToLowSideVMin : 16|2@1+ (1,0) [0|3] "" Vector__XXX
 SG_ FourPLDueToHiSideVMax : 14|2@1+ (1,0) [0|3] "" Vector__XXX
 SG_ FourPLDueToHiSideVMin : 12|2@1+ (1,0) [0|3] "" Vector__XXX
 SG_ FourPLDueToLowSideCur : 10|2@1+ (1,0) [0|3] "" Vector__XXX
 SG_ FourPLDueToHiSideCur : 8|2@1+ (1,0) [0|3] "" Vector__XXX
 SG_ FourLoadshedReq : 6|2@1+ (1,0) [0|3] "" Vector__XXX
 SG_ FourHVILStatus : 4|2@1+ (1,0) [0|3] "" Vector__XXX
 SG_ FourOperationalStatus : 0|4@1+ (1,0) [0|15] "" Vector__XXX

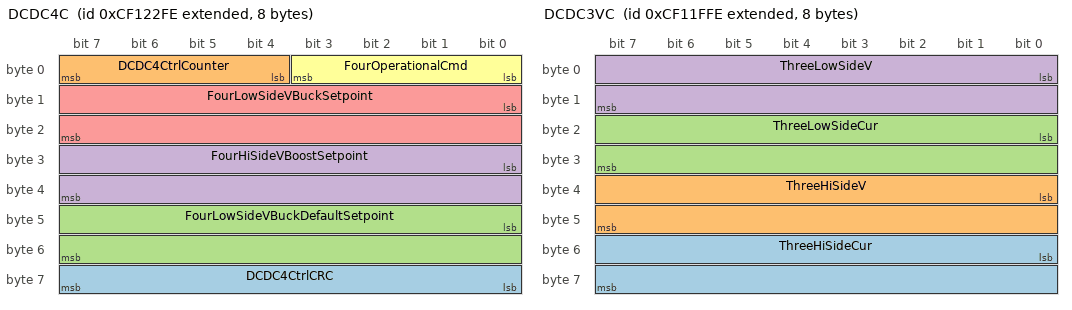
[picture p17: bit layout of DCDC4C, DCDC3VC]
BO_ 2364613374 DCDC4C: 8 Vector__XXX
 SG_ DCDC4CtrlCRC : 56|8@1+ (1,0) [0|255] "" Vector__XXX
 SG_ DCDC4CtrlCounter : 4|4@1+ (1,0) [0|15] "" Vector__XXX
 SG_ FourLowSideVBuckDefaultSetpoint : 40|16@1+ (0.01,0) [0|642.55] "V" Vector__XXX
 SG_ FourHiSideVBoostSetpoint : 24|16@1+ (0.05,0) [0|3212.75] "V" Vector__XXX
 SG_ FourLowSideVBuckSetpoint : 8|16@1+ (0.01,0) [0|642.55] "V" Vector__XXX
 SG_ FourOperationalCmd : 0|4@1+ (1,0) [0|15] "" Vector__XXX

BO_ 2364613118 DCDC3S2: 8 Vector__XXX
 SG_ ThreeHiSideNegToChassisGroundV : 32|16@1+ (0.05,0) [0|3212.75] "V" Vector__XXX
 SG_ ThreeHiSidePwr : 16|16@1+ (0.05,-1600) [-1600|1612.75] "kW" Vector__XXX
 SG_ ThreeLowSidePwr : 0|16@1+ (0.05,-1600) [-1600|1612.75] "kW" Vector__XXX

BO_ 2364612862 DCDC3SBS: 8 Vector__XXX
 SG_ SLIBatTermTemp : 32|8@1+ (1,-40) [-40|210] "°C" Vector__XXX
 SG_ SLIBatTermCur : 16|16@1+ (0.1,-3212.7) [-3212.7|3212.8] "A" Vector__XXX
 SG_ SLIBatTermV : 0|16@1+ (0.01,0) [0|642.55] "V" Vector__XXX

BO_ 2364612606 DCDC3VC: 8 Vector__XXX
 SG_ ThreeHiSideCur : 48|16@1+ (0.1,-3212.7) [-3212.7|3212.8] "A" Vector__XXX
 SG_ ThreeHiSideV : 32|16@1+ (0.05,0) [0|3212.75] "V" Vector__XXX
 SG_ ThreeLowSideCur : 16|16@1+ (0.1,-3212.7) [-3212.7|3212.8] "A" Vector__XXX
 SG_ ThreeLowSideV : 0|16@1+ (0.01,0) [0|642.55] "V" Vector__XXX

BO_ 2364612350 DCDC3OS: 8 Vector__XXX
 SG_ DCDC3OperatingStatusCRC : 56|8@1+ (1,0) [0|255] "" Vector__XXX
 SG_ DCDC3OperatingStatusCounter : 52|4@1+ (1,0) [0|15] "" Vector__XXX
 SG_ ThreePLDueToUndefinedReason : 32|2@1+ (1,0) [0|3] "" Vector__XXX
 SG_ ThreePLDueToSLIBatTermTemp : 30|2@1+ (1,0) [0|3] "" Vector__XXX
 SG_ ThreePLDueToSLIBatTermCur : 28|2@1+ (1,0) [0|3] "" Vector__XXX
 SG_ ThreePLDueToSLIBatTermV : 26|2@1+ (1,0) [0|3] "" Vector__XXX
 SG_ ThreePLDueToPwrETemp : 24|2@1+ (1,0) [0|3] "" Vector__XXX
 SG_ ThreePLDueToEFilterTemp : 22|2@1+ (1,0) [0|3] "" Vector__XXX
 SG_ ThreePLDueToConvTemp : 20|2@1+ (1,0) [0|3] "" Vector__XXX
 SG_ ThreePLDueToLowSideVMax : 18|2@1+ (1,0) [0|3] "" Vector__XXX
 SG_ ThreePLDueToLowSideVMin : 16|2@1+ (1,0) [0|3] "" Vector__XXX
 SG_ ThreePLDueToHiSideVMax : 14|2@1+ (1,0) [0|3] "" Vector__XXX
 SG_ ThreePLDueToHiSideVMin : 12|2@1+ (1,0) [0|3] "" Vector__XXX
 SG_ ThreePLDueToLowSideCur : 10|2@1+ (1,0) [0|3] "" Vector__XXX
 SG_ ThreePLDueToHiSideCur : 8|2@1+ (1,0) [0|3] "" Vector__XXX
 SG_ ThreeLoadshedReq : 6|2@1+ (1,0) [0|3] "" Vector__XXX
 SG_ ThreeHVILStatus : 4|2@1+ (1,0) [0|3] "" Vector__XXX
 SG_ ThreeOperationalStatus : 0|4@1+ (1,0) [0|15] "" Vector__XXX

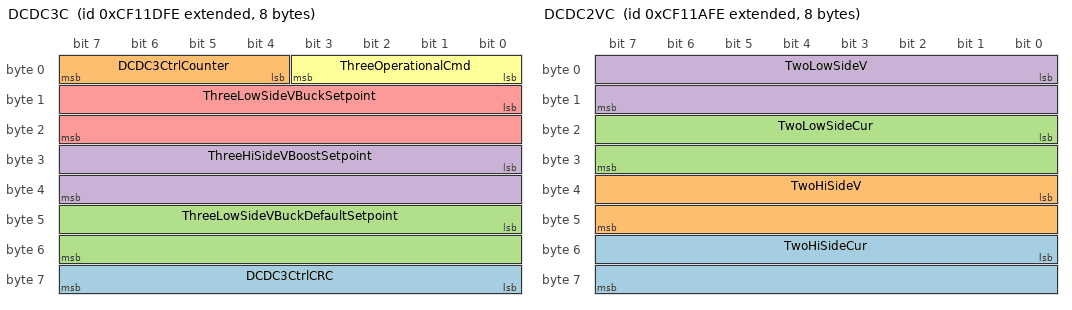
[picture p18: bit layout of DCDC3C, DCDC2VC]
BO_ 2364612094 DCDC3C: 8 Vector__XXX
 SG_ DCDC3CtrlCRC : 56|8@1+ (1,0) [0|255] "" Vector__XXX
 SG_ DCDC3CtrlCounter : 4|4@1+ (1,0) [0|15] "" Vector__XXX
 SG_ ThreeLowSideVBuckDefaultSetpoint : 40|16@1+ (0.01,0) [0|642.55] "V" Vector__XXX
 SG_ ThreeHiSideVBoostSetpoint : 24|16@1+ (0.05,0) [0|3212.75] "V" Vector__XXX
 SG_ ThreeLowSideVBuckSetpoint : 8|16@1+ (0.01,0) [0|642.55] "V" Vector__XXX
 SG_ ThreeOperationalCmd : 0|4@1+ (1,0) [0|15] "" Vector__XXX

BO_ 2364611838 DCDC2S2: 8 Vector__XXX
 SG_ TwoHiSideNegToChassisGroundV : 32|16@1+ (0.05,0) [0|3212.75] "V" Vector__XXX
 SG_ TwoHiSidePwr : 16|16@1+ (0.05,-1600) [-1600|1612.75] "kW" Vector__XXX
 SG_ TwoLowSidePwr : 0|16@1+ (0.05,-1600) [-1600|1612.75] "kW" Vector__XXX

BO_ 2364611582 DCDC2SBS: 8 Vector__XXX
 SG_ SLIBatTermTemp : 32|8@1+ (1,-40) [-40|210] "°C" Vector__XXX
 SG_ SLIBatTermCur : 16|16@1+ (0.1,-3212.7) [-3212.7|3212.8] "A" Vector__XXX
 SG_ SLIBatTermV : 0|16@1+ (0.01,0) [0|642.55] "V" Vector__XXX

BO_ 2364611326 DCDC2VC: 8 Vector__XXX
 SG_ TwoHiSideCur : 48|16@1+ (0.1,-3212.7) [-3212.7|3212.8] "A" Vector__XXX
 SG_ TwoHiSideV : 32|16@1+ (0.05,0) [0|3212.75] "V" Vector__XXX
 SG_ TwoLowSideCur : 16|16@1+ (0.1,-3212.7) [-3212.7|3212.8] "A" Vector__XXX
 SG_ TwoLowSideV : 0|16@1+ (0.01,0) [0|642.55] "V" Vector__XXX

BO_ 2364611070 DCDC2OS: 8 Vector__XXX
 SG_ DCDC2OperatingStatusCRC : 56|8@1+ (1,0) [0|255] "" Vector__XXX
 SG_ DCDC2OperatingStatusCounter : 52|4@1+ (1,0) [0|15] "" Vector__XXX
 SG_ TwoPLDueToUndefinedReason : 32|2@1+ (1,0) [0|3] "" Vector__XXX
 SG_ TwoPLDueToSLIBatTermTemp : 30|2@1+ (1,0) [0|3] "" Vector__XXX
 SG_ TwoPLDueToSLIBatTermCur : 28|2@1+ (1,0) [0|3] "" Vector__XXX
 SG_ TwoPLDueToSLIBatTermV : 26|2@1+ (1,0) [0|3] "" Vector__XXX
 SG_ TwoPLDueToPwrETemp : 24|2@1+ (1,0) [0|3] "" Vector__XXX
 SG_ TwoPLDueToEFilterTemp : 22|2@1+ (1,0) [0|3] "" Vector__XXX
 SG_ TwoPLDueToConvTemp : 20|2@1+ (1,0) [0|3] "" Vector__XXX
 SG_ TwoPLDueToLowSideVMax : 18|2@1+ (1,0) [0|3] "" Vector__XXX
 SG_ TwoPLDueToLowSideVMin : 16|2@1+ (1,0) [0|3] "" Vector__XXX
 SG_ TwoPLDueToHiSideVMax : 14|2@1+ (1,0) [0|3] "" Vector__XXX
 SG_ TwoPLDueToHiSideVMin : 12|2@1+ (1,0) [0|3] "" Vector__XXX
 SG_ TwoPLDueToLowSideCur : 10|2@1+ (1,0) [0|3] "" Vector__XXX
 SG_ TwoPLDueToHiSideCur : 8|2@1+ (1,0) [0|3] "" Vector__XXX
 SG_ TwoLoadshedReq : 6|2@1+ (1,0) [0|3] "" Vector__XXX
 SG_ TwoHVILStatus : 4|2@1+ (1,0) [0|3] "" Vector__XXX
 SG_ TwoOperationalStatus : 0|4@1+ (1,0) [0|15] "" Vector__XXX

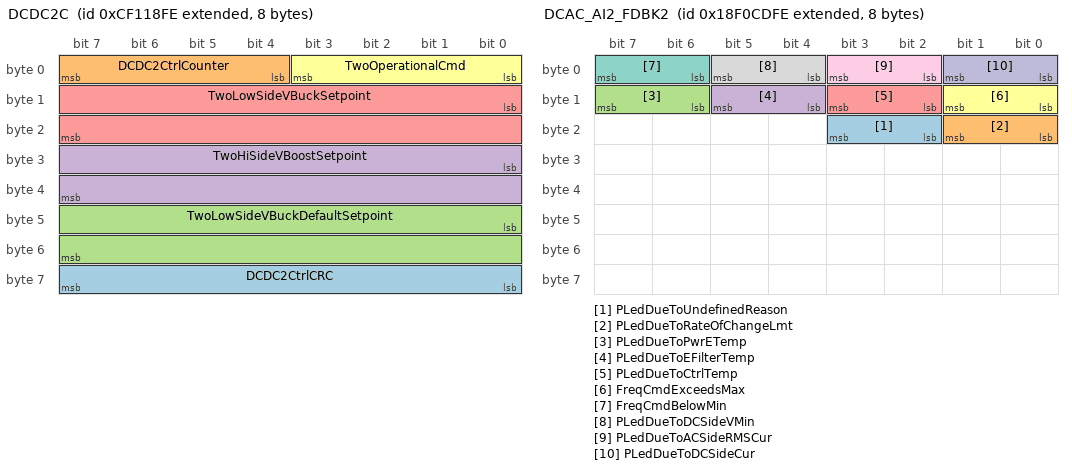
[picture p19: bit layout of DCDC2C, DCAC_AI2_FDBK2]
BO_ 2364610814 DCDC2C: 8 Vector__XXX
 SG_ DCDC2CtrlCRC : 56|8@1+ (1,0) [0|255] "" Vector__XXX
 SG_ DCDC2CtrlCounter : 4|4@1+ (1,0) [0|15] "" Vector__XXX
 SG_ TwoLowSideVBuckDefaultSetpoint : 40|16@1+ (0.01,0) [0|642.55] "V" Vector__XXX
 SG_ TwoHiSideVBoostSetpoint : 24|16@1+ (0.05,0) [0|3212.75] "V" Vector__XXX
 SG_ TwoLowSideVBuckSetpoint : 8|16@1+ (0.01,0) [0|642.55] "V" Vector__XXX
 SG_ TwoOperationalCmd : 0|4@1+ (1,0) [0|15] "" Vector__XXX

BO_ 2364610558 DCDC1S2: 8 Vector__XXX
 SG_ OneHiSideNegToChassisGroundV : 32|16@1+ (0.05,0) [0|3212.75] "V" Vector__XXX
 SG_ OneHiSidePwr : 16|16@1+ (0.05,-1600) [-1600|1612.75] "kW" Vector__XXX
 SG_ OneLowSidePwr : 0|16@1+ (0.05,-1600) [-1600|1612.75] "kW" Vector__XXX

BO_ 2565918206 DCAC_AI2_FDBK2: 8 Vector__XXX
 SG_ PLedDueToUndefinedReason : 18|2@1+ (1,0) [0|3] "" Vector__XXX
 SG_ PLedDueToRateOfChangeLmt : 16|2@1+ (1,0) [0|3] "" Vector__XXX
 SG_ PLedDueToPwrETemp : 14|2@1+ (1,0) [0|3] "" Vector__XXX
 SG_ PLedDueToEFilterTemp : 12|2@1+ (1,0) [0|3] "" Vector__XXX
 SG_ PLedDueToCtrlTemp : 10|2@1+ (1,0) [0|3] "" Vector__XXX
 SG_ FreqCmdExceedsMax : 8|2@1+ (1,0) [0|3] "" Vector__XXX
 SG_ FreqCmdBelowMin : 6|2@1+ (1,0) [0|3] "" Vector__XXX
 SG_ PLedDueToDCSideVMin : 4|2@1+ (1,0) [0|3] "" Vector__XXX
 SG_ PLedDueToACSideRMSCur : 2|2@1+ (1,0) [0|3] "" Vector__XXX
 SG_ PLedDueToDCSideCur : 0|2@1+ (1,0) [0|3] "" Vector__XXX

BO_ 2364591358 DCAC_AI2_V: 8 Vector__XXX
 SG_ SLIV : 16|16@1+ (0.05,0) [0|3212.75] "V" Vector__XXX
 SG_ IgntV : 0|16@1+ (0.05,0) [0|3212.75] "V" Vector__XXX

BO_ 2364591102 DCAC_AI2_S2: 8 Vector__XXX
 SG_ DCSideNegToChassisGroundV : 48|16@1+ (0.05,0) [0|3212.75] "V" Vector__XXX
 SG_ DCSideCur : 32|16@1+ (0.0625,0) [0|4015.9375] "A" Vector__XXX
 SG_ DCSideV : 16|16@1+ (0.05,0) [0|3212.75] "V" Vector__XXX
 SG_ DCSidePwr : 0|16@1+ (0.0625,0) [0|4015.9375] "kW" Vector__XXX

CM_ BO_ 2566630654 "DC/AC Accessory Inverter 4 Lifetime Data
Contains data accumulated over the lifetime of this DC/AC Accessory Inverter.";
CM_ SG_ 2566630654 TotalDCInputEnergy "Total lifetime energy converted by the DC/AC from the DC Side.";
CM_ SG_ 2566630654 TotalDCInputCharge "Total lifetime charge converted by the DC/AC from the DC Side.";
CM_ BO_ 2566630398 "DC/AC Accessory Inverter 4 Configuration 1
Reports the active configuration settings for this DC/AC Accessory Inverter.  Settings may be defined by the manufacturer, or set through use of limit PGs (DCAC_AI4_DCL and DCAC_AI4_ACL).";
CM_ SG_ 2566630398 ACSideDefaultFreqCmdSetting "Reports the active AC Side Default Frequency Command Setting of the DC/AC Accessory Inverter.  The setting may be requested by a separate device (via SPN 9526).

Note: Report Not Available (FFh) when no default has been set.";
CM_ SG_ 2566630398 DCSideCurMinLmtSetting "Reports the active minimum limit on the DC Side input current of the DC/AC Accessory Inverter.  The setting may be requested by a separate device (via SPN 9548) or determined by the DC/AC Controller based on operating conditions.";
CM_ SG_ 2566630398 DCSideVMaxLmtSetting "Reports the active maximum limit on the DC Side input voltage of the DC/AC Accessory Inverter.  The setting may be requested by a separate device (via SPN 9547) or determined by the DC/AC Controller based on operating conditions.";
CM_ SG_ 2566630398 ACSideRMSCurMaxLmtSetting "Reports the active maximum limit on the AC side output RMS line current of the DC/AC Accessory Inverter.  The setting may be requested by a separate device (via SPN 9314) or determined by the DC/AC Controller based on operating conditions.";
CM_ SG_ 2566630398 ACSideRMSVMaxLmtSetting "Reports the active maximum limit on the AC Side output line to line RMS voltage of the DC/AC Accessory Inverter.  The setting may be requested by a separate device (via SPN 9313) or determined by the DC/AC Controller based on operating conditions.";
CM_ SG_ 2566630398 DCSideCurMaxLmtSetting "Reports the active maximum limit on the DC Side input current of the DC/AC Accessory Inverter.  The setting may be requested by a separate device (via SPN 9312) or determined by the DC/AC Controller based on operating conditions.";
CM_ SG_ 2566630398 DCSideVMinLmtSetting "Reports the active minimum limit on the DC Side input voltage of the DC/AC Accessory Inverter.  The setting may be requested by a separate device (via SPN 9311) or determined by the DC/AC Controller based on operating conditions.";
CM_ BO_ 2365303550 "DC/AC Accessory Inverter 4 AC Side Limits 
Sets the AC Side system limits for the transfer of energy between the HVES or high voltage system (i.e. DC Side) and the accessory loads (i.e. AC Side) in a hybrid or electric vehicle.";
CM_ SG_ 2365303550 DefaultFreqReq "This setting may be used to set a default frequency command for when communication has been lost with the controlling device.  When set to Not Available (FFh), no default setting is provided and the system should disable its output.";
CM_ SG_ 2365303550 RMSCurMaxLmtReq "The maximum allowed AC Side output RMS line current requested by a separate device.   Under normal conditions this requested limit would be reflected in SPN 9318.";
CM_ SG_ 2365303550 RMSVMaxLmtReq "The maximum allowed AC Side line to line RMS voltage requested by a separate device.   Under normal conditions this requested limit would be reflected in SPN 9317.";
CM_ BO_ 2365303294 "DC/AC Accessory Inverter 4 DC Side Limits 
Sets the HVES or High Voltage system limits for the transfer of energy between the high voltage system (i.e. DC side) and the accessory loads (i.e. AC side) in a hybrid or electric vehicle.";
CM_ SG_ 2365303294 CurMinLmtReq "The minimum allowed DC Side input current requested by a separate device.   Under normal conditions this requested limit would be reflected in SPN 9550.";
CM_ SG_ 2365303294 VMaxLmtReq "The maximum allowed DC Side input voltage requested by a separate device.   Under normal conditions this requested limit would be reflected in SPN 9549.";
CM_ SG_ 2365303294 CurMaxLmtReq "The maximum allowed DC Side input current requested by a separate device.   Under normal conditions this requested limit would be reflected in SPN 9316.";
CM_ SG_ 2365303294 VMinLmtReq "The minimum allowed DC Side input voltage requested by a separate device.   Under normal conditions this requested limit would be reflected in SPN 9315.";
CM_ BO_ 2566629630 "DC/AC Accessory Inverter 4 Temperatures
DC/AC Accessory Inverter measured temperature data.";
CM_ SG_ 2566629630 CoolantOutTemp "Temperature of the DC/AC Accessory Inverter Coolant measured at the output of the accessory inverter.";
CM_ SG_ 2566629630 CoolantInTemp "Temperature of the DC/AC Accessory Inverter Coolant measured at the input of the accessory inverter.";
CM_ SG_ 2566629630 PwrETemp "Temperature of the DC/AC Accessory Inverter power electronics components (e.g, switch or heatsink).";
CM_ SG_ 2566629630 InverterEFilterTemp "Temperature of the electronic components that make up the DC/AC Accessory Inverter filter.";
CM_ SG_ 2566629630 CtrlTemp "Temperature of the DC/AC Accessory Inverter (e.g, controller, circuit board, enclosure).";
CM_ BO_ 2566629374 "DC/AC Accessory Inverter 3 Lifetime Data
Contains data accumulated over the lifetime of this DC/AC Accessory Inverter.";
CM_ SG_ 2566629374 TotalDCInputEnergy "Total lifetime energy converted by the DC/AC from the DC Side.";
CM_ SG_ 2566629374 TotalDCInputCharge "Total lifetime charge converted by the DC/AC from the DC Side.";
CM_ BO_ 2566629118 "DC/AC Accessory Inverter 3 Configuration 1
Reports the active configuration settings for this DC/AC Accessory Inverter.  Settings may be defined by the manufacturer, or set through use of limit PGs (DCAC_AI3_DCL and DCAC_AI3_ACL).";
CM_ SG_ 2566629118 ACSideDefaultFreqCmdSetting "Reports the active AC Side Default Frequency Command Setting of the DC/AC Accessory Inverter.  The setting may be requested by a separate device (via SPN 9525).

Note: Report Not Available (FFh) when no default has been set.";
CM_ SG_ 2566629118 DCSideCurMinLmtSetting "Reports the active minimum limit on the DC Side input current of the DC/AC Accessory Inverter.  The setting may be requested by a separate device (via SPN 9542) or determined by the DC/AC Controller based on operating conditions.";
CM_ SG_ 2566629118 DCSideVMaxLmtSetting "Reports the active maximum limit on the DC Side input voltage of the DC/AC Accessory Inverter.  The setting may be requested by a separate device (via SPN 9541 or determined by the DC/AC Controller based on operating conditions.";
CM_ SG_ 2566629118 ACSideRMSCurMaxLmtSetting "Reports the active maximum limit on the AC side output RMS line current of the DC/AC Accessory Inverter.  The setting may be requested by a separate device (via SPN 9284) or determined by the DC/AC Controller based on operating conditions.";
CM_ SG_ 2566629118 ACSideRMSVMaxLmtSetting "Reports the active maximum limit on the AC Side output line to line RMS voltage of the DC/AC Accessory Inverter.  The setting may be requested by a separate device (via SPN 9283) or determined by the DC/AC Controller based on operating conditions.";
CM_ SG_ 2566629118 DCSideCurMaxLmtSetting "Reports the active maximum limit on the DC Side input current of the DC/AC Accessory Inverter.  The setting may be requested by a separate device (via SPN 9282) or determined by the DC/AC Controller based on operating conditions.";
CM_ SG_ 2566629118 DCSideVMinLmtSetting "Reports the active minimum limit on the DC Side input voltage of the DC/AC Accessory Inverter.  The setting may be requested by a separate device (via SPN 9281) or determined by the DC/AC Controller based on operating conditions.";
CM_ BO_ 2365302270 "DC/AC Accessory Inverter 3 AC Side Limits 
Sets the AC Side system limits for the transfer of energy between the HVES or high voltage system (i.e. DC Side) and the accessory loads (i.e. AC Side) in a hybrid or electric vehicle.";
CM_ SG_ 2365302270 DefaultFreqReq "This setting may be used to set a default frequency command for when communication has been lost with the controlling device.  When set to Not Available (FFh), no default setting is provided and the system should disable its output.";
CM_ SG_ 2365302270 RMSCurMaxLmtReq "The maximum allowed AC Side output RMS line current requested by a separate device.   Under normal conditions this requested limit would be reflected in SPN 9288.";
CM_ SG_ 2365302270 RMSVMaxLmtReq "The maximum allowed AC Side line to line RMS voltage requested by a separate device.   Under normal conditions this requested limit would be reflected in SPN 9287.";
CM_ BO_ 2365302014 "DC/AC Accessory Inverter 3 DC Side Limits 
Sets the HVES or High Voltage system limits for the transfer of energy between the high voltage system (i.e. DC side) and the accessory loads (i.e. AC side) in a hybrid or electric vehicle.";
CM_ SG_ 2365302014 CurMinLmtReq "The minimum allowed DC Side input current requested by a separate device.   Under normal conditions this requested limit would be reflected in SPN 9544.";
CM_ SG_ 2365302014 VMaxLmtReq "The maximum allowed DC Side input voltage requested by a separate device.   Under normal conditions this requested limit would be reflected in SPN 9543.";
CM_ SG_ 2365302014 CurMaxLmtReq "The maximum allowed DC Side input current requested by a separate device.   Under normal conditions this requested limit would be reflected in SPN 9286.";
CM_ SG_ 2365302014 VMinLmtReq "The minimum allowed DC Side input voltage requested by a separate device.   Under normal conditions this requested limit would be reflected in SPN 9285.";
CM_ BO_ 2566628350 "DC/AC Accessory Inverter 3 Temperatures
DC/AC Accessory Inverter measured temperature data.";
CM_ SG_ 2566628350 CoolantOutTemp "Temperature of the DC/AC Accessory Inverter Coolant measured at the output of the accessory inverter.";
CM_ SG_ 2566628350 CoolantInTemp "Temperature of the DC/AC Accessory Inverter Coolant measured at the input of the accessory inverter.";
CM_ SG_ 2566628350 PwrETemp "Temperature of the DC/AC Accessory Inverter power electronics components (e.g, switch or heatsink).";
CM_ SG_ 2566628350 InverterEFilterTemp "Temperature of the electronic components that make up the DC/AC Accessory Inverter filter.";
CM_ SG_ 2566628350 CtrlTemp "Temperature of the DC/AC Accessory Inverter (e.g, controller, circuit board, enclosure).";
CM_ BO_ 2566628094 "DC/AC Accessory Inverter 2 Lifetime Data
Contains data accumulated over the lifetime of this DC/AC Accessory Inverter.";
CM_ SG_ 2566628094 TotalDCInputEnergy "Total lifetime energy converted by the DC/AC from the DC Side.";
CM_ SG_ 2566628094 TotalDCInputCharge "Total lifetime charge converted by the DC/AC from the DC Side.";
CM_ BO_ 2566627838 "DC/AC Accessory Inverter 2 Configuration 1
Reports the active configuration settings for this DC/AC Accessory Inverter.  Settings may be defined by the manufacturer, or set through use of limit PGs (DCAC_AI2_DCL and DCAC_AI2_ACL).";
CM_ SG_ 2566627838 ACSideDefaultFreqCmdSetting "Reports the active AC Side Default Frequency Command Setting of the DC/AC Accessory Inverter.  The setting may be requested by a separate device (via SPN 9524).

Note: Report Not Available (FFh) when no default has been set.";
CM_ SG_ 2566627838 DCSideCurMinLmtSetting "Reports the active minimum limit on the DC Side input current of the DC/AC Accessory Inverter.  The setting may be requested by a separate device (via SPN 9536) or determined by the DC/AC Controller based on operating conditions.";
CM_ SG_ 2566627838 DCSideVMaxLmtSetting "Reports the active maximum limit on the DC Side input voltage of the DC/AC Accessory Inverter.  The setting may be requested by a separate device (via SPN 9535) or determined by the DC/AC Controller based on operating conditions.";
CM_ SG_ 2566627838 ACSideRMSCurMaxLmtSetting "Reports the active maximum limit on the AC side output RMS line current of the DC/AC Accessory Inverter.  The setting may be requested by a separate device (via SPN 9254) or determined by the DC/AC Controller based on operating conditions.";
CM_ SG_ 2566627838 ACSideRMSVMaxLmtSetting "Reports the active maximum limit on the AC Side output line to line RMS voltage of the DC/AC Accessory Inverter.  The setting may be requested by a separate device (via SPN 9253) or determined by the DC/AC Controller based on operating conditions.";
CM_ SG_ 2566627838 DCSideCurMaxLmtSetting "Reports the active maximum limit on the DC Side input current of the DC/AC Accessory Inverter.  The setting may be requested by a separate device (via SPN 9252) or determined by the DC/AC Controller based on operating conditions.";
CM_ SG_ 2566627838 DCSideVMinLmtSetting "Reports the active minimum limit on the DC Side input voltage of the DC/AC Accessory Inverter.  The setting may be requested by a separate device (via SPN 9251) or determined by the DC/AC Controller based on operating conditions.";
CM_ BO_ 2365300990 "DC/AC Accessory Inverter 2 AC Side Limits 
Sets the AC Side system limits for the transfer of energy between the HVES or high voltage system (i.e. DC Side) and the accessory loads (i.e. AC Side) in a hybrid or electric vehicle.";
CM_ SG_ 2365300990 DefaultFreqReq "This setting may be used to set a default frequency command for when communication has been lost with the controlling device.  When set to Not Available (FFh), no default setting is provided and the system should disable its output.";
CM_ SG_ 2365300990 RMSCurMaxLmtReq "The maximum allowed AC Side output RMS line current requested by a separate device.   Under normal conditions this requested limit would be reflected in SPN 9258.";
CM_ SG_ 2365300990 RMSVMaxLmtReq "The maximum allowed AC Side line to line RMS voltage requested by a separate device.   Under normal conditions this requested limit would be reflected in SPN 9257.";
CM_ BO_ 2365300734 "DC/AC Accessory Inverter 2 DC Side Limits 
Sets the HVES or High Voltage system limits for the transfer of energy between the high voltage system (i.e. DC side) and the accessory loads (i.e. AC side) in a hybrid or electric vehicle.";
CM_ SG_ 2365300734 CurMinLmtReq "The minimum allowed DC Side input current requested by a separate device.   Under normal conditions this requested limit would be reflected in SPN 9538.";
CM_ SG_ 2365300734 VMaxLmtReq "The maximum allowed DC Side input voltage requested by a separate device.   Under normal conditions this requested limit would be reflected in SPN 9537.";
CM_ SG_ 2365300734 CurMaxLmtReq "The maximum allowed DC Side input current requested by a separate device.   Under normal conditions this requested limit would be reflected in SPN 9256.";
CM_ SG_ 2365300734 VMinLmtReq "The minimum allowed DC Side input voltage requested by a separate device.   Under normal conditions this requested limit would be reflected in SPN 9255.";
CM_ BO_ 2566627070 "DC/AC Accessory Inverter 2 Temperatures
DC/AC Accessory Inverter measured temperature data.";
CM_ SG_ 2566627070 CoolantOutTemp "Temperature of the DC/AC Accessory Inverter Coolant measured at the output of the accessory inverter.";
CM_ SG_ 2566627070 CoolantInTemp "Temperature of the DC/AC Accessory Inverter Coolant measured at the input of the accessory inverter.";
CM_ SG_ 2566627070 PwrETemp "Temperature of the DC/AC Accessory Inverter power electronics components (e.g, switch or heatsink).";
CM_ SG_ 2566627070 InverterEFilterTemp "Temperature of the electronic components that make up the DC/AC Accessory Inverter filter.";
CM_ SG_ 2566627070 CtrlTemp "Temperature of the DC/AC Accessory Inverter (e.g, controller, circuit board, enclosure).";
CM_ BO_ 2566626814 "DC/AC Accessory Inverter 1 Lifetime Data
Contains data accumulated over the lifetime of this DC/AC Accessory Inverter.";
CM_ SG_ 2566626814 TotalDCInputEnergy "Total lifetime energy converted by the DC/AC from the DC Side.";
CM_ SG_ 2566626814 TotalDCInputCharge "Total lifetime charge converted by the DC/AC from the DC Side.";
CM_ BO_ 2566626558 "DC/AC Accessory Inverter 1 Configuration 1
Reports the active configuration settings for this DC/AC Accessory Inverter.  Settings may be defined by the manufacturer, or set through use of limit PGs (DCAC_AI1_DCL and DCAC_AI1_ACL).";
CM_ SG_ 2566626558 ACSideDefaultFreqCmdSetting "Reports the active AC Side Default Frequency Command Setting of the DC/AC Accessory Inverter.  The setting may be requested by a separate device (via SPN 9523).

Note: Report Not Available (FFh) when no default has been set.";
CM_ SG_ 2566626558 DCSideCurMinLmtSetting "Reports the active minimum limit on the DC Side input current of the DC/AC Accessory Inverter.  The setting may be requested by a separate device (via SPN 9530) or determined by the DC/AC Controller based on operating conditions.";
CM_ SG_ 2566626558 DCSideVMaxLmtSetting "Reports the active maximum limit on the DC Side input voltage of the DC/AC Accessory Inverter.  The setting may be requested by a separate device (via SPN 9529) or determined by the DC/AC Controller based on operating conditions.";
CM_ SG_ 2566626558 ACSideRMSCurMaxLmtSetting "Reports the active maximum limit on the AC side output RMS line current of the DC/AC Accessory Inverter.  The setting may be requested by a separate device (via SPN 9224) or determined by the DC/AC Controller based on operating conditions.";
CM_ SG_ 2566626558 ACSideRMSVMaxLmtSetting "Reports the active maximum limit on the AC Side output line to line RMS voltage of the DC/AC Accessory Inverter.  The setting may be requested by a separate device (via SPN 9223) or determined by the DC/AC Controller based on operating conditions.";
CM_ SG_ 2566626558 DCSideCurMaxLmtSetting "Reports the active maximum limit on the DC Side input current of the DC/AC Accessory Inverter.  The setting may be requested by a separate device (via SPN 9222) or determined by the DC/AC Controller based on operating conditions.";
CM_ SG_ 2566626558 DCSideVMinLmtSetting "Reports the active minimum limit on the DC Side input voltage of the DC/AC Accessory Inverter.  The setting may be requested by a separate device (via SPN 9221) or determined by the DC/AC Controller based on operating conditions.";
CM_ BO_ 2365299710 "DC/AC Accessory Inverter 1 AC Side Limits 
Sets the AC Side system limits for the transfer of energy between the HVES or high voltage system (i.e. DC Side) and the accessory loads (i.e. AC Side) in a hybrid or electric vehicle.";
CM_ SG_ 2365299710 DefaultFreqReq "This setting may be used to set a default frequency command for when communication has been lost with the controlling device.  When set to Not Available (FFh), no default setting is provided and the system should disable its output.";
CM_ SG_ 2365299710 RMSCurMaxLmtReq "The maximum allowed AC Side output RMS line current requested by a separate device.   Under normal conditions this requested limit would be reflected in SPN 9228.";
CM_ SG_ 2365299710 RMSVMaxLmtReq "The maximum allowed AC Side line to line RMS voltage requested by a separate device.   Under normal conditions this requested limit would be reflected in SPN 9227.";
CM_ BO_ 2365299454 "DC/AC Accessory Inverter 1 DC Side Limits 
Sets the HVES or High Voltage system limits for the transfer of energy between the high voltage system (i.e. DC side) and the accessory loads (i.e. AC side) in a hybrid or electric vehicle.";
CM_ SG_ 2365299454 CurMinLmtReq "The minimum allowed DC Side input current requested by a separate device.   Under normal conditions this requested limit would be reflected in SPN 9532.";
CM_ SG_ 2365299454 VMaxLmtReq "The maximum allowed DC Side input voltage requested by a separate device.   Under normal conditions this requested limit would be reflected in SPN 9531.";
CM_ SG_ 2365299454 CurMaxLmtReq "The maximum allowed DC Side input current requested by a separate device.   Under normal conditions this requested limit would be reflected in SPN 9226.";
CM_ SG_ 2365299454 VMinLmtReq "The minimum allowed DC Side input voltage requested by a separate device.   Under normal conditions this requested limit would be reflected in SPN 9225.";
CM_ BO_ 2566625790 "DC/AC Accessory Inverter 1 Temperatures
DC/AC Accessory Inverter measured temperature data.";
CM_ SG_ 2566625790 CoolantOutTemp "Temperature of the DC/AC Accessory Inverter Coolant measured at the output of the accessory inverter.";
CM_ SG_ 2566625790 CoolantInTemp "Temperature of the DC/AC Accessory Inverter Coolant measured at the input of the accessory inverter.";
CM_ SG_ 2566625790 PwrETemp "Temperature of the DC/AC Accessory Inverter power electronics components (e.g, switch or heatsink).";
CM_ SG_ 2566625790 InverterEFilterTemp "Temperature of the electronic components that make up the DC/AC Accessory Inverter filter.";
CM_ SG_ 2566625790 CtrlTemp "Temperature of the DC/AC Accessory Inverter (e.g, controller, circuit board, enclosure).";
CM_ BO_ 2633734398 "Exhaust Oxygen 2
Contains information which relates to the exhaust particulate control system on the engine.";
CM_ SG_ 2633734398 EngActualExh2O2 "The actual amount of oxygen in the second exhaust represented as a percentage by volume with respect to the total volume of exhaust gases leaving the engine.
Note:  A value of FB00h shall be provided when ambient or engine operating conditions do ...";
CM_ BO_ 2566625278 "Vehicle Electrical Power 15
Battery capacity setting parameters for SLI Battery Pack 1.";
CM_ SG_ 2566625278 SLIBatPack1Bat4CapacitySetting "Informs the battery controller of the capacity of its associated battery.  This parameter applies to the fourth battery in the first set of batteries (battery pack) used for starting the engine, for lighting, and for ignition (SLI).";
CM_ SG_ 2566625278 SLIBatPack1Bat3CapacitySetting "Informs the battery controller of the capacity of its associated battery.  This parameter applies to the third battery in the first set of batteries (battery pack) used for starting the engine, for lighting, and for ignition (SLI) .";
CM_ SG_ 2566625278 SLIBatPack1Bat2CapacitySetting "Informs the battery controller of the capacity of its associated battery.  This parameter applies to the second battery in the first set of batteries (battery pack) used for starting the engine, for lighting, and for ignition (SLI) .";
CM_ SG_ 2566625278 SLIBatPack1Bat1CapacitySetting "Informs the battery controller of the capacity of its associated battery.  This parameter applies to the first battery in the first set of batteries (battery pack) used for starting the engine, for lighting, and for ignition (SLI) .";
CM_ BO_ 2566625022 "Engine Information 3
Third PG conveying engine information";
CM_ SG_ 2566625022 ExhManifoldBank1Press2 "Second gage pressure of the exhaust gases as measured at the turbine intake of the turbocharger. This SP is to be used for inline engines or exhaust bank 1 of multiple bank engines.  See SPN 11799 for exhaust bank 2.";
CM_ SG_ 2566625022 InstantaneousEstEngPwrRateLmt "Estimate of the maximum power load rate the engine can sustain at that moment in time.";
CM_ BO_ 2566624766 "Engine Hours 2
Second PG for engine hours information";
CM_ SG_ 2566624766 IdleMnmgtActiveTotalTime "Total accumulated time the engine is off due to the engine idle management system.";
CM_ BO_ 2566624510 "Electronic Engine Controller 22
Engine related parameters";
CM_ SG_ 2566624510 TotalNumOfCrankAttempts "Reports the number of cranking cycles undergone during the life of the engine.

Note: This is intended to count the number of crank attempts as described in SPN 3671.";
CM_ SG_ 2566624510 EGR1CoolerInPress "Exhaust gas recirculation gage pressure is measured at the EGR cooler intake.";
CM_ BO_ 2365297662 "DC/DC Converter 1 Voltage
Low Voltage data from DC/DC Converter.";
CM_ SG_ 2365297662 OneCtrlInputSLIV "Continuously supplied SLI power to this instance of the DC/DC Converter controller.";
CM_ SG_ 2365297662 OneCtrlInputIgntV "Ignition voltage (i.e. switched) supplied to the  DC/DC Converter controller.";
CM_ BO_ 2365297406 "DC/DC Converter 2 Voltage
Low Voltage data from DC/DC Converter.";
CM_ SG_ 2365297406 TwoCtrlInputSLIV "Continuously supplied SLI power to this instance of the DC/DC Converter controller.";
CM_ SG_ 2365297406 TwoCtrlInputIgntV "Ignition voltage (i.e. switched) supplied to the  DC/DC Converter controller.";
CM_ BO_ 2365297150 "DC/DC Converter 3 Voltage
Low Voltage data from DC/DC Converter.";
CM_ SG_ 2365297150 ThreeCtrlInputSLIV "Continuously supplied SLI power to this instance of the DC/DC Converter controller.";
CM_ SG_ 2365297150 ThreeCtrlInputIgntV "Ignition voltage (i.e. switched) supplied to the  DC/DC Converter controller.";
CM_ BO_ 2365296894 "DC/DC Converter 4 Voltage
Low Voltage data from DC/DC Converter.";
CM_ SG_ 2365296894 FourCtrlInputSLIV "Continuously supplied SLI power to this instance of the DC/DC Converter controller.";
CM_ SG_ 2365296894 FourCtrlInputIgntV "Ignition voltage (i.e. switched) supplied to the  DC/DC Converter controller.";
CM_ BO_ 2566623230 "Economy Mode Estimated Fuel Savings
Economy mode estimated fuel related parameters";
CM_ SG_ 2566623230 TripEstFuelSaved "Total volume of estimated fuel saved during all or part of a journey while operating in economy mode, since the last trip reset. This is in comparison to operating in a non-economy mode.";
CM_ SG_ 2566623230 TotalEstFuelSaved "Total volume of estimated fuel saved during economy mode of operation over the lifetime of the application. This is in comparison to operating in a non-economy mode.";
CM_ BO_ 2566622974 "Economy Mode Fuel Used
Amount of fuel consumed while economy mode is active.";
CM_ SG_ 2566622974 TripFuelUsed "Total volume of fuel used during all or part of a journey while operating in economy mode, since the last trip reset.";
CM_ SG_ 2566622974 TotalFuelUsed "Total volume of fuel used during economy mode operation over the lifetime of the application.";
CM_ BO_ 2566622718 "Economy Mode Active Hours
Accumulated time of operation while economy mode is active.";
CM_ SG_ 2566622718 TripHoursActive "Total accumulated operating time in economy mode since the last trip reset.";
CM_ SG_ 2566622718 TotalHoursActive "Total accumulated operating time in economy mode over the lifetime of the application.";
CM_ BO_ 2566622462 "Economy Mode Estimated Instantaneous Fuel Savings Rate
Fuel savings rate estimations while economy mode is active.";
CM_ SG_ 2566622462 Percent "Estimated instantaneous fuel savings rate percentage while operating in economy mode. This value is calculated by dividing Economy Mode Estimated Instantaneous Fuel Savings Percent (SPN 9576) by the current non-economy mode estimated instantaneous ...";
CM_ SG_ 2566622462 RateAbsolute "Estimated instantaneous fuel savings rate while operating in economy mode.  This is in comparison to operating in a non-economy mode.";
CM_ BO_ 2566622206 "Economy Mode Inactive Hours
Accumulated time of operation while economy mode is installed but not in use.";
CM_ SG_ 2566622206 TripHoursInactive "Trip operating time accumulated while economy mode is installed but not in use, since last trip reset.";
CM_ SG_ 2566622206 TotalHoursInactive "Total accumulated operating time while economy mode is installed but not in use.";
CM_ BO_ 2365295358 "High Voltage Energy Storage System Data 11
Data set 11 (electrical data) for High Voltage Energy Storage System (or Pack 1 in systems with only one pack).";
CM_ SG_ 2365295358 PwrModuleETemp "Parameter indicating the temperature of the power module electronics (e.g., DC/DC converter, switch, heatsink) in the HVESS.";
CM_ SG_ 2365295358 TotalStoredESLvl "This is the total percentage of the HVES useable capacity, including both online and offline packs. For the capacity of connected packs only, see SPN 7895.";
CM_ SG_ 2365295358 ActualChargeRate "This signal represents the actual present charge rate of the High Voltage Energy Storage System (or Pack 1 in systems with only one pack).
This parameter provides HVES system level information. If there are multiple packs in the system, then both ...";
CM_ SG_ 2365295358 LvlNegToChassisGroundV "Voltage difference between the most negative terminal of the HVES battery and chassis measured at the battery side of any HVES contained output contactor.  This voltage may be used for system level monitoring of battery shorts to chassis within the ...";
CM_ SG_ 2365295358 BusVNegToChassisGroundV "Voltage difference between the most negative terminal of the HVES battery and chassis measured on the hybrid system bus side (not the battery side) of any HVES contained output contactor.  This voltage may be used for system level monitoring of ...";
CM_ BO_ 2566621694 "Engine Fluid Level/Pressure 13
13th PG which identifies parameters that are either measuring various pressures within the engine or identifying engine fluid levels";
CM_ SG_ 2566621694 OilLvl2St "Second instance of engine oil level switch which indicates if engine oil level is low or normal.

See SPN 22722 for the first instance of engine oil level state.

00b = Low
01b = Normal
10b = Error
11b = Not available";
CM_ SG_ 2566621694 OilLvl1St "First instance of engine oil level switch which indicates if engine oil level is low or normal.

See SPN 22723 for the second instance of engine oil level state.

00b = Low
01b = Normal
10b = Error
11b = Not available";
CM_ SG_ 2566621694 CrankcaseBreatherOilSepOutPress "Indicates the gage pressure of the crankcase breather gases measured at the outlet of crankcase breather oil separator.";
CM_ SG_ 2566621694 ChargeAC2DiffPress "Differential Pressure across the second engine charge air cooler.";
CM_ SG_ 2566621694 ChargeAC1DiffPress "Differential Pressure across the first or only engine charge air cooler.";
CM_ SG_ 2566621694 ChargeAC2OutPress "Measures pressure of air at outlet of second charge air cooler.";
CM_ SG_ 2566621694 OilPress2 "Gage pressure of oil in engine lubrication system as provided by oil pump - second instance.";
CM_ BO_ 2566621438 "Marine Control Information 3
Marine vessel control information for the vessel control system.";
CM_ SG_ 2566621438 HeavySeaModeEnable "Command signal used to indicate that the Marine heavy sea mode is disabled or enabled. Heavy sea mode puts the engine in a control mode to manage heavy sea/ rough water load fluctuations.
00b = Marine heavy sea mode is disabled
01b = Marine heavy ...";
CM_ SG_ 2566621438 SlowVesselModeLampStatus "Reports when the slow vessel mode lamp is illuminated.

00b = Off
01b = On
10b = Error
11b = Not Available";
CM_ SG_ 2566621438 GearLockoutLampStatus "Reports when the gear lockout lamp is illuminated.

00b = Off
01b = On
10b = Error
11b = Not Available";
CM_ SG_ 2566621438 EngThrotLeverSynchLampStatus "Reports when the throttle lever synchronization lamp is illuminated. When synchronization mode is activated, an operator uses one throttle lever to control the speed of multiple engines.

00b = Off
01b = On
10b = Error
11b = Not Available";
CM_ SG_ 2566621438 TrollingModeLampStatus "Reports when the trolling mode lamp is illuminated.

00b = Off
01b = On
10b = Error
11b = Not Available";
CM_ SG_ 2566621438 OpStationActiveLampStatus "Reports when the operator station active lamp is illuminated.

00b = Off
01b = On
10b = Error
11b = Not Available";
CM_ SG_ 2566621438 SlowVesselModeButtonStatus "Reports when the slow vessel mode button has been pressed.

00b = Button not pressed
01b = Button pressed
10b = Error
11b = Not Available";
CM_ SG_ 2566621438 GearLockoutButtonStatus "This button is used to prevent the transmissions from being shifted into gear. When the button is pressed, the transmissions will be locked in neutral.

00b = Button not pressed
01b = Button pressed
10b = Error
11b = Not Available";
CM_ SG_ 2566621438 EngThrotLeverSynchButtonStatus "The button that is used to enable or disable syncronization of the engine throttles. When synchronization mode is activated, an operator uses one throttle lever to control the speed of multiple engines.
00b = Button not pressed
01b = Button ...";
CM_ SG_ 2566621438 TrollingModeButtonStatus "The button used to change the current type of trolling mode that is selected.

00b = Button not pressed
01b = Button pressed
10b = Error
11b = Not Available";
CM_ SG_ 2566621438 OpStationActiveButtonStatus "The button used to request a station to become the active station when another station is currently in control.

00b = Button not pressed
01b = Button pressed
10b = Error
11b = Not Available";
CM_ SG_ 2566621438 StationGearPosMatch "Indicates whether the gear position at the currently selected station is in neutral and the gear lever position at the station where the transfer is occuring is in neutral in order to allow the transfer to occur.
00b = Neutral
01b = Not in neutral
 ...";
CM_ SG_ 2566621438 StationThrotPosMatch "Indicates whether the throttle position at the currently selected station and the throttle lever position at the station where the transfer is occuring is within the correct range to allow the transfer to occur.
00b = Throttle positions do not ...";
CM_ BO_ 2566620670 "Engine Idle Management Information
Engine Idle Management Information";
CM_ SG_ 2566620670 PendingEventTimeRemaining "Used to indicate the time remaining before the engine will start-up or shutdown as determined by the idle management controller. The time remaining can be used to trigger additional alarms, lamps & display messages.";
CM_ SG_ 2566620670 ShutdownReason "Used to indicate the condition requesting the engine to shutdown when the idle management system is active.
When multiple reasons are applicable, it is suggested that precedence be given to states which are less easily resolved, i.e. such as those ...";
CM_ SG_ 2566620670 RestartReason "Used to indicate the condition requesting the engine to restart when the idle management system is active.
0000b = Operator input request
0001b = Low engine coolant temperature
0010b = Low SLI battery voltage
0011b = Low transmission oil ...";
CM_ SG_ 2566620670 Status "Indicates the current state or mode of operation by the engine idle manangement system.
0000b = Off
0001b = Locked
0010b = Disabled
0011b = Activation conditions not met (Not able to begin or continue due to current engine operating conditions)
 ...";
CM_ BO_ 2364620286 "Active Steering System Controls 1
Active Steering System Controls 1";
CM_ SG_ 2364620286 HandsOffDetectionAvailability "Defines whether the Hands Off Detection feature has passed the set preconditions or not.  Allows the feature to be disabled if preconditions are not and be enabled when the preconditions are met.
000b = Hands Off Detection Not Ready
001b = Hands ...";
CM_ SG_ 2364620286 HandsOffDetectionStatus "Defines whether the Hands Off Detection feature has detected the operator is driving with their hands off the steering wheel for an extended amount of time
000b = Hands Off Not Detected
001b = Hands Off Detected
010b = Hands Off Detection ...";
CM_ SG_ 2364620286 LaneCenteringSysStatus "Indicates the current state of the Lane Centering feature.
0000b = System is not ready (initialization not finished)
0001b = System is temporarily not available (not all activation conditions fulfulled)
0010b = System is deactivated by driver
 ...";
CM_ SG_ 2364620286 LaneCenteringIndEnableSt "Indicates whether lane centering indication is enabled.

00b = Lane Centering Indication disabled
01b = Lane Centering Indication enabled
10b = Error
11b = Not available";
CM_ SG_ 2364620286 DriverPref "Indicates the current preference for active steering mode selected by the driver.
000b = Active Steering Mode #1
001b = Active Steering Mode #2
010b = Active Steering Mode #3
011b = Active Steering Mode #4
100b = Active Steering Mode #5
101b = ...";
CM_ SG_ 2364620286 LaneKeepingAssistSysSt "Indicates the current state of the Lane Keep Assist feature.
0000b = System is not ready (initialization not finished)
0001b = System is temporarily not available (not all activation conditions fulfulled)
0010b = System is deactivated by driver
 ...";
CM_ SG_ 2364620286 LaneKeepingAssistIndEnableStatus "Indicates whether lane keeping assist is enabled.

00b = Lane Keeping Assist disabled
01b = Lane Keeping Assist enabled
10b = Error
11b = Not available";
CM_ SG_ 2364620286 LaneKeepingAssistStatusLeftSide "Indicates the current status of lane keeping assist feature for left side lane marker.
000b = Lane Keeping Assist Not Available for Left Side
001b = Lane Keeping Assist Available for Left Side
010b = Lane Keeping Assist Suppressed for Left Side
 ...";
CM_ SG_ 2364620286 LaneKeepingAssistStatusRightSide "Indicates the current status of lane keeping assist feature for right side lane marker.
000b = Lane Keeping Assist Not Available for Right Side
001b = Lane Keeping Assist Available for Right Side
010b = Lane Keeping Assist Suppressed for Right ...";
CM_ BO_ 2364620030 "Engine Pre-Chamber Fuel Valve Start of Actuation Command 5
Used to transmit the pre-chamber fuel valve start of activation command information for valve 17 to valve 20 associated with cylinders 17 through 20.";
CM_ SG_ 2364620030 Two0StartAct "The angle, relative to the TDC of cylinder 20 with 0 being the TDC before the power stroke commences, at the which pre-chamber fuel valve 20 is activated to open.";
CM_ SG_ 2364620030 One9StartAct "The angle, relative to the TDC of cylinder 19 with 0 being the TDC before the power stroke commences, at the which pre-chamber fuel valve 19 is activated to open.";
CM_ SG_ 2364620030 One8StartAct "The angle, relative to the TDC of cylinder 18 with 0 being the TDC before the power stroke commences, at the which pre-chamber fuel valve 18 is activated to open.";
CM_ SG_ 2364620030 One7StartAct "The angle, relative to the TDC of cylinder 17 with 0 being the TDC before the power stroke commences, at the which pre-chamber fuel valve 17 is activated to open.";
CM_ BO_ 2364619774 "Engine Pre-Chamber Fuel Valve Start of Actuation Command 4
Used to transmit the pre-chamber fuel valve start of activation command information for valve 13 to valve 16 associated with cylinders 13 through 16.";
CM_ SG_ 2364619774 One6StartAct "The angle, relative to the TDC of cylinder 16 with 0 being the TDC before the power stroke commences, at the which pre-chamber fuel valve 16 is activated to open.";
CM_ SG_ 2364619774 One5StartAct "The angle, relative to the TDC of cylinder 15 with 0 being the TDC before the power stroke commences, at the which pre-chamber fuel valve 15 is activated to open.";
CM_ SG_ 2364619774 One4StartAct "The angle, relative to the TDC of cylinder 14 with 0 being the TDC before the power stroke commences, at the which pre-chamber fuel valve 14 is activated to open.";
CM_ SG_ 2364619774 One3StartAct "The angle, relative to the TDC of cylinder 13 with 0 being the TDC before the power stroke commences, at the which pre-chamber fuel valve 13 is activated to open.";
CM_ BO_ 2364619518 "Engine Pre-Chamber Fuel Valve Start of Actuation Command 3
Used to transmit the pre-chamber fuel valve start of activation command information for valve 9 to valve 12 associated with cylinders 9 through 12.";
CM_ SG_ 2364619518 One2StartAct "The angle, relative to the TDC of cylinder 12 with 0 being the TDC before the power stroke commences, at the which pre-chamber fuel valve 12 is activated to open.";
CM_ SG_ 2364619518 One1StartAct "The angle, relative to the TDC of cylinder 11 with 0 being the TDC before the power stroke commences, at the which pre-chamber fuel valve 11 is activated to open.";
CM_ SG_ 2364619518 One0StartAct "The angle, relative to the TDC of cylinder 10 with 0 being the TDC before the power stroke commences, at the which pre-chamber fuel valve 10 is activated to open.";
CM_ SG_ 2364619518 NineStartAct "The angle, relative to the TDC of cylinder 9 with 0 being the TDC before the power stroke commences, at the which pre-chamber fuel valve 9 is activated to open.";
CM_ BO_ 2364619262 "Engine Pre-Chamber Fuel Valve Start of Actuation Command 2
Used to transmit the pre-chamber fuel valve start of activation command information for valve 5 to valve 8 associated with cylinders 5 through 8.";
CM_ SG_ 2364619262 EightStartAct "The angle, relative to the TDC of cylinder 8 with 0 being the TDC before the power stroke commences, at the which pre-chamber fuel valve 8 is activated to open.";
CM_ SG_ 2364619262 SevenStartAct "The angle, relative to the TDC of cylinder 7 with 0 being the TDC before the power stroke commences, at the which pre-chamber fuel valve 7 is activated to open.";
CM_ SG_ 2364619262 SixStartAct "The angle, relative to the TDC of cylinder 6 with 0 being the TDC before the power stroke commences, at the which pre-chamber fuel valve 6 is activated to open.";
CM_ SG_ 2364619262 FiveStartAct "The angle, relative to the TDC of cylinder 5 with 0 being the TDC before the power stroke commences, at the which pre-chamber fuel valve 5 is activated to open.";
CM_ BO_ 2364619006 "Engine Pre-Chamber Fuel Valve Start of Actuation Command 1
Used to transmit the pre-chamber fuel valve start of activation command information for valve 1 to valve 4 associated with cylinders 1 through 4.";
CM_ SG_ 2364619006 FourStartAct "The angle, relative to the TDC of cylinder 4 with 0 being the TDC before the power stroke commences, at the which pre-chamber fuel valve 4 is activated to open.";
CM_ SG_ 2364619006 ThreeStartAct "The angle, relative to the TDC of cylinder 3 with 0 being the TDC before the power stroke commences, at the which pre-chamber fuel valve 3 is activated to open.";
CM_ SG_ 2364619006 TwoStartAct "The angle, relative to the TDC of cylinder 2 with 0 being the TDC before the power stroke commences, at the which pre-chamber fuel valve 2 is activated to open.";
CM_ SG_ 2364619006 OneStartAct "The angle, relative to the TDC of cylinder 1 with 0 being the TDC before the power stroke commences, at the which pre-chamber fuel valve 1 is activated to open.";
CM_ BO_ 2364618750 "Engine Pre-Chamber Fuel Valve Duration Command 5
Used to transmit the pre-chamber fuel valve duration command information for valve 17 to valve 20";
CM_ SG_ 2364618750 Two0Dur "Amount of time the pre-chamber fuel valve 20 is activated.";
CM_ SG_ 2364618750 One9Dur "Amount of time the pre-chamber fuel valve 19 is activated.";
CM_ SG_ 2364618750 One8Dur "Amount of time the pre-chamber fuel valve 18 is activated.";
CM_ SG_ 2364618750 One7Dur "Amount of time the pre-chamber fuel valve 17 is activated.";
CM_ BO_ 2364618494 "Engine Pre-Chamber Fuel Valve Duration Command 4
Used to transmit the pre-chamber fuel valve duration command information for valve 13 to valve 16";
CM_ SG_ 2364618494 One6Dur "Amount of time the pre-chamber fuel valve 16 is activated.";
CM_ SG_ 2364618494 One5Dur "Amount of time the pre-chamber fuel valve 15 is activated.";
CM_ SG_ 2364618494 One4Dur "Amount of time the pre-chamber fuel valve 14 is activated.";
CM_ SG_ 2364618494 One3Dur "Amount of time the pre-chamber fuel valve 13 is activated.";
CM_ BO_ 2364618238 "Engine Pre-Chamber Fuel Valve Duration Command 3
Used to transmit the pre-chamber fuel valve duration command information for valve 9 to valve 12";
CM_ SG_ 2364618238 One2Dur "Amount of time the pre-chamber fuel valve 12 is activated.";
CM_ SG_ 2364618238 One1Dur "Amount of time the pre-chamber fuel valve 11 is activated.";
CM_ SG_ 2364618238 One0Dur "Amount of time the pre-chamber fuel valve 10 is activated.";
CM_ SG_ 2364618238 NineDur "Amount of time the pre-chamber fuel valve 9 is activated.";
CM_ BO_ 2364617982 "Engine Pre-Chamber Fuel Valve Duration Command 2
Used to transmit the pre-chamber fuel valve duration command information for valve 5 to valve 8";
CM_ SG_ 2364617982 EightDur "Amount of time the pre-chamber fuel valve 8 is activated.";
CM_ SG_ 2364617982 SevenDur "Amount of time the pre-chamber fuel valve 7 is activated.";
CM_ SG_ 2364617982 SixDur "Amount of time the pre-chamber fuel valve 6 is activated.";
CM_ SG_ 2364617982 FiveDur "Amount of time the pre-chamber fuel valve 5 is activated.";
CM_ BO_ 2364617726 "Engine Pre-Chamber Fuel Valve Duration Command 1
Used to transmit the pre-chamber fuel valve duration command information for valve 1 to valve 4";
CM_ SG_ 2364617726 FourDur "Amount of time the pre-chamber fuel valve 4 is activated.";
CM_ SG_ 2364617726 ThreeDur "Amount of time the pre-chamber fuel valve 3 is activated.";
CM_ SG_ 2364617726 TwoDur "Amount of time the pre-chamber fuel valve 2 is activated.";
CM_ SG_ 2364617726 OneDur "Amount of time the pre-chamber fuel valve 1 is activated.";
CM_ BO_ 2565944062 "DC/AC Accessory Inverter 5 Feedback 2
Sent by this Accessory Inverter instance and contains the current operating conditions of this output of the inverter.  This message would be received by a controller application (e.g. Power System Manager) ...";
CM_ SG_ 2565944062 PLedDueToUndefinedReason "Output power is being limited due to an undefined reason.

00b = No power limit for this reason
01b = Power limited for this reason
10b = Error
11b = Not Available";
CM_ SG_ 2565944062 PLedDueToRateOfChangeLmt "Output power is being limited due to the frequency approaching or exceeding the rate of change limit (see SPN 9325).

00b = No power limit for this reason
01b = Power limited for this reason
10b = Error
11b = Not Available";
CM_ SG_ 2565944062 PLedDueToPwrETemp "Output power is being limited due to power electronics temperature (see SPN 9339) approaching or exceeding the maximum limit.

00b = No power limit for this reason
01b = Power limited for this reason
10b = Error
11b = Not Available";
CM_ SG_ 2565944062 PLedDueToEFilterTemp "Output power is being limited due to electronic filter temperature (see SPN 9338) approaching or exceeding the maximum limit.

00b = No power limit for this reason
01b = Power limited for this reason
10b = Error
11b = Not Available";
CM_ SG_ 2565944062 PLedDueToCtrlTemp "Output power is being limited due to the controller temperature (see SPN 9337) approaching or exceeding the maximum limit.

00b = No power limit for this reason
01b = Power limited for this reason
10b = Error
11b = Not Available";
CM_ SG_ 2565944062 FreqCmdExceedsMax "Output frequency is being limited due to frequency command (see SPN 9326) approaching or exceeding the maximum limit (SPN 9321).

00b = No frequency limit for this reason
01b = Frequency limited for this reason
10b = Error
11b = Not Available";
CM_ SG_ 2565944062 FreqCmdBelowMin "Output frequency is being limited due to frequency command (see SPN 9326) approaching or falling below the minimum limit (SPN 9322).
00b = No frequency limit for this reason
01b = Frequency limited for this reason
10b = Error
11b = Not Available
 ...";
CM_ SG_ 2565944062 PLedDueToDCSideVMin "Output power is being limited due to DC Side input voltage (see SPN 9343) approaching or falling below the minimum limit (SPN 9361).

00b = No power limit for this reason
01b = Power limited for this reason
10b = Error
11b = Not Available";
CM_ SG_ 2565944062 PLedDueToACSideRMSCur "AC Side Output power is being limited due to AC Side output RMS current (see SPN 9333) approaching or exceeding the maximum limit (See SPN 9364).
00b = No power limit for this reason
01b = Power limited for this reason
10b = Error
11b = Not ...";
CM_ SG_ 2565944062 PLedDueToDCSideCur "Output power is being limited due to DC Side input current (see SPN 9344) approaching or exceeding the maximum limit (See SPN 9362).

00b = No power limit for this reason
01b = Power limited for this reason
10b = Error
11b = Not Available";
CM_ BO_ 2364617214 "DC/AC Accessory Inverter 5 Voltage
Low Voltage data from DC/AC Accessory Inverter.";
CM_ SG_ 2364617214 SLIV "Continuously supplied SLI power to this instance of the DC/AC Accessory Inverter controller.";
CM_ SG_ 2364617214 IgntV "Ignition voltage supplied to the  DC/AC Accessory Inverter controller.";
CM_ BO_ 2364616958 "DC/AC Accessory Inverter 5 Status 2
Additional data reported from DC/AC Accessory Inverter";
CM_ SG_ 2364616958 DCSideNegToChassisGroundV "The voltage level of the high voltage DC side, as measured by the DC/AC between the negative side of the High Voltage DC Side input and the chassis of the DC/AC enclosure.  This voltage can be used for system level monitoring of DC Side High Voltage ...";
CM_ SG_ 2364616958 DCSideCur "DC Side input current measured at the point of control inside the DC/AC Accessory Inverter.";
CM_ SG_ 2364616958 DCSideV "DC Side input voltage measured at the point of control inside the DC/AC Accessory Inverter.";
CM_ SG_ 2364616958 DCSidePwr "Power measured at the DC Side input to the DC/AC Accessory Inverter.";
CM_ BO_ 2565943294 "DC/AC Accessory Inverter 5 Feedback
Sent by this DC/AC Accessory Inverter instance and contains the current operating conditions of this output of the inverter.  This message would be received by a controller application (e.g. Power System Manager) ...";
CM_ SG_ 2565943294 HVILStatus "High Voltage Interlock Loop (HVIL) state of the DC/AC Accessory Inverter 5.

00b = HVIL Closed
01b = HVIL Open
10b = Error
11b = Not Available";
CM_ SG_ 2565943294 LoadshedReq "Loadshed Request from this DC/AC Accessory Inverter output.  The Loadshed Requested state is an indication that the inverter output powering this device has a malfunction and is in a limit condition and if the load of the output is not reduced, the ...";
CM_ SG_ 2565943294 OperationalStatus "Operating Status of this DC/AC Accessory Inverter output. The Inverter Output Faulted state will be communicated when the inverter output has shutdown due to an overload condition or other fault.
000b = Output Disabled
001b = Output Enabled
010b ...";
CM_ SG_ 2565943294 ACSideRMSCur "Present operating AC Side output RMS line Current of this DC/AC Accessory Inverter.  When connected to a balanced three phase motor, this would be the current in each individual phase of the motor.";
CM_ SG_ 2565943294 ACSidePwr "Present operating AC Side power of this DC/AC Accessory Inverter output.";
CM_ SG_ 2565943294 ACSideRMSV "Present operating AC Side line to line RMS voltage of this DC/AC Accessory Inverter output.  In a three phase balanced motor, this is the RMS voltage across one phase of the motor.";
CM_ SG_ 2565943294 Freq "Present operating frequency of this DC/AC Accessory Inverter output.";
CM_ BO_ 2565943038 "DC/AC Accessory Inverter 5 Command
Used to command this instance of an DC/AC Accessory Inverter that uses a V/Hz algorithm.  The Inverter may have multiple outputs to power accessories on a vehicle (e.g. HVAC compressor, air compressor, power ...";
CM_ SG_ 2565943038 ACSideMotorStartingRMSVReq "Signal to the DC/AC Accessory Inverter indicating the requested AC side RMS voltage for starting the attached accessory motor.   In a V/Hz variable speed motor control application, this voltage typically may be set to a non-zero value when an ...";
CM_ SG_ 2565943038 OperationalCmd "Command to the DC/AC Accessory Inverter to enable this output.  Each output may control multiple devices (e.g. electric motors) if they all operate at the same frequency.
00b = Disable DC/AC Accessory Inverter Output
01b = Enable DC/AC Accessory ...";
CM_ SG_ 2565943038 Device2Status "Signal to the DC/AC Accessory Inverter indicating the state of the device attached to the inverter output.  Each output may control multiple devices (e.g. electric motors) if they all operate at the same frequency.
The Faulted Off state will be ...";
CM_ SG_ 2565943038 Device1Status "Signal to the DC/AC Accessory Inverter indicating the state of the device attached to the inverter output.  Each output may control multiple devices (e.g. electric motors) if they all operate at the same frequency.
The Faulted Off state will be ...";
CM_ SG_ 2565943038 FreqCmd "Command to the DC/AC Accessory Inverter indicating the Inverter frequency desired for the device(s) attached to the inverter output.  Each output may control multiple devices (e.g. electric motors) if they all operate at the same frequency.";
CM_ SG_ 2565943038 DeviceFreqRateOfChangeLmt "Signal to the DC/AC Accessory Inverter indicating the frequency rate of change limit of the device(s) attached to the inverter output (Note: Increasing and decreasing rates can be controlled by the same signal).  Each output may control multiple ...";
CM_ SG_ 2565943038 DeviceRatedRMSV "Signal to the DC/AC Accessory Inverter indicating the rated RMS voltage of the device(s) attached to the inverter output.   Each output may control multiple devices (e.g. electric motors) if they all operate at the same frequency.";
CM_ SG_ 2565943038 DeviceRatedFreq "Signal to the DC/AC Accessory Inverter indicating the rated frequency of the device(s) attached to the inverter output.  Each output may control multiple devices (e.g. electric motors) if they all operate at the same frequency.";
CM_ SG_ 2565943038 DeviceMinFreq "Signal to the DC/AC Accessory Inverter indicating the minimum frequency of the device(s) attached to the inverter output.  Each output may control multiple devices (e.g. electric motors) if they all operate at the same frequency.";
CM_ SG_ 2565943038 DeviceMaxFreq "Signal to the DC/AC Accessory Inverter indicating the maximum frequency of the devices(s) attached to the inverter output.  Each output may control multiple devices (e.g. electric motors) if they all operate at the same frequency.";
CM_ BO_ 2565942782 "DC/AC Accessory Inverter 4 Feedback 2
Sent by this Accessory Inverter instance and contains the current operating conditions of this output of the inverter.  This message would be received by a controller application (e.g. Power System Manager) ...";
CM_ SG_ 2565942782 PLedDueToUndefinedReason "Output power is being limited due to an undefined reason.

00b = No power limit for this reason
01b = Power limited for this reason
10b = Error
11b = Not Available";
CM_ SG_ 2565942782 PLedDueToRateOfChangeLmt "Output power is being limited due to the frequency approaching or exceeding the rate of change limit (see SPN 8374).

00b = No power limit for this reason
01b = Power limited for this reason
10b = Error
11b = Not Available";
CM_ SG_ 2565942782 PLedDueToPwrETemp "Output power is being limited due to power electronics temperature (see SPN 9293) approaching or exceeding the maximum limit.

00b = No power limit for this reason
01b = Power limited for this reason
10b = Error
11b = Not Available";
CM_ SG_ 2565942782 PLedDueToEFilterTemp "Output power is being limited due to electronic filter temperature (see SPN 9292) approaching or exceeding the maximum limit.

00b = No power limit for this reason
01b = Power limited for this reason
10b = Error
11b = Not Available";
CM_ SG_ 2565942782 PLedDueToCtrlTemp "Output power is being limited due to the controller temperature (see SPN 9291) approaching or exceeding the maximum limit.

00b = No power limit for this reason
01b = Power limited for this reason
10b = Error
11b = Not Available";
CM_ SG_ 2565942782 FreqCmdExceedsMax "Output frequency is being limited due to frequency command (see SPN 8375) approaching or exceeding the maximum limit (SPN 8370).

00b = No frequency limit for this reason
01b = Frequency limited for this reason
10b = Error
11b = Not Available";
CM_ SG_ 2565942782 FreqCmdBelowMin "Output frequency is being limited due to frequency command (see SPN 8375) approaching or falling below the minimum limit (SPN 8371).
00b = No frequency limit for this reason
01b = Frequency limited for this reason
10b = Error
11b = Not Available
 ...";
CM_ SG_ 2565942782 PLedDueToDCSideVMin "Output power is being limited due to DC Side input voltage (see SPN 9297) approaching or falling below the minimum limit (SPN 9315).

00b = No power limit for this reason
01b = Power limited for this reason
10b = Error
11b = Not Available";
CM_ SG_ 2565942782 PLedDueToACSideRMSCur "AC Side Output power is being limited due to AC Side output RMS current (see SPN 9203) approaching or exceeding the maximum limit (See SPN 9318).
00b = No power limit for this reason
01b = Power limited for this reason
10b = Error
11b = Not ...";
CM_ SG_ 2565942782 PLedDueToDCSideCur "Output power is being limited due to DC Side input current (see SPN 9298) approaching or exceeding the maximum limit (See SPN 9316).

00b = No power limit for this reason
01b = Power limited for this reason
10b = Error
11b = Not Available";
CM_ BO_ 2364615934 "DC/AC Accessory Inverter 4 Voltage
Low Voltage data from DC/AC Accessory Inverter.";
CM_ SG_ 2364615934 SLIV "Continuously supplied SLI power to this instance of the DC/AC Accessory Inverter controller.";
CM_ SG_ 2364615934 IgntV "Ignition voltage supplied to the  DC/AC Accessory Inverter controller.";
CM_ BO_ 2364615678 "DC/AC Accessory Inverter 4 Status 2
Additional data reported from DC/AC Accessory Inverter";
CM_ SG_ 2364615678 DCSideNegToChassisGroundV "The voltage level of the high voltage DC side, as measured by the DC/AC between the negative side of the High Voltage DC Side input and the chassis of the DC/AC enclosure.  This voltage can be used for system level monitoring of DC Side High Voltage ...";
CM_ SG_ 2364615678 DCSideCur "DC Side input current measured at the point of control inside the DC/AC Accessory Inverter.";
CM_ SG_ 2364615678 DCSideV "DC Side input voltage measured at the point of control inside the DC/AC Accessory Inverter.";
CM_ SG_ 2364615678 DCSidePwr "Power measured at the DC Side input to the DC/AC Accessory Inverter.";
CM_ BO_ 2565942014 "DC/AC Accessory Inverter 3 Feedback 2
Sent by this Accessory Inverter instance and contains the current operating conditions of this output of the inverter.  This message would be received by a controller application (e.g. Power System Manager) ...";
CM_ SG_ 2565942014 PLedDueToUndefinedReason "Output power is being limited due to an undefined reason.

00b = No power limit for this reason
01b = Power limited for this reason
10b = Error
11b = Not Available";
CM_ SG_ 2565942014 PLedDueToRateOfChangeLmt "Output power is being limited due to the frequency approaching or exceeding the rate of change limit (see SPN 8360).

00b = No power limit for this reason
01b = Power limited for this reason
10b = Error
11b = Not Available";
CM_ SG_ 2565942014 PLedDueToPwrETemp "Output power is being limited due to power electronics temperature (see SPN 9263) approaching or exceeding the maximum limit.

00b = No power limit for this reason
01b = Power limited for this reason
10b = Error
11b = Not Available";
CM_ SG_ 2565942014 PLedDueToEFilterTemp "Output power is being limited due to electronic filter temperature (see SPN 9262) approaching or exceeding the maximum limit.

00b = No power limit for this reason
01b = Power limited for this reason
10b = Error
11b = Not Available";
CM_ SG_ 2565942014 PLedDueToCtrlTemp "Output power is being limited due to the controller temperature (see SPN 9261) approaching or exceeding the maximum limit.

00b = No power limit for this reason
01b = Power limited for this reason
10b = Error
11b = Not Available";
CM_ SG_ 2565942014 FreqCmdExceedsMax "Output frequency is being limited due to frequency command (see SPN 8361) approaching or exceeding the maximum limit (SPN 8356).

00b = No frequency limit for this reason
01b = Frequency limited for this reason
10b = Error
11b = Not Available";
CM_ SG_ 2565942014 FreqCmdBelowMin "Output frequency is being limited due to frequency command (see SPN 8361) approaching or falling below the minimum limit (SPN 8357).
00b = No frequency limit for this reason
01b = Frequency limited for this reason
10b = Error
11b = Not Available
 ...";
CM_ SG_ 2565942014 PLedDueToDCSideVMin "Output power is being limited due to DC Side input voltage (see SPN 9267) approaching or falling below the minimum limit  (SPN 9285).

00b = No power limit for this reason
01b = Power limited for this reason
10b = Error
11b = Not Available";
CM_ SG_ 2565942014 PLedDueToACSideRMSCur "AC Side Output power is being limited due to AC Side output RMS current (see SPN 9202) approaching or exceeding the maximum limit (See SPN 9288).
00b = No power limit for this reason
01b = Power limited for this reason
10b = Error
11b = Not ...";
CM_ SG_ 2565942014 PLedDueToDCSideCur "Output power is being limited due to DC Side input current (see SPN 9268) approaching or exceeding the maximum limit (See SPN 9286).

00b = No power limit for this reason
01b = Power limited for this reason
10b = Error
11b = Not Available";
CM_ BO_ 2364615166 "DC/AC Accessory Inverter 3 Voltage
Low Voltage data from DC/AC Accessory Inverter.";
CM_ SG_ 2364615166 SLIV "Continuously supplied SLI power to this instance of the DC/AC Accessory Inverter controller.";
CM_ SG_ 2364615166 IgntV "Ignition voltage supplied to the  DC/AC Accessory Inverter controller.";
CM_ BO_ 2364614910 "DC/AC Accessory Inverter 3 Status 2
Additional data reported from DC/AC Accessory Inverter";
CM_ SG_ 2364614910 DCSideNegToChassisGroundV "The voltage level of the high voltage DC side, as measured by the DC/AC between the negative side of the High Voltage DC Side input and the chassis of the DC/AC enclosure.  This voltage can be used for system level monitoring of DC Side High Voltage ...";
CM_ SG_ 2364614910 DCSideCur "DC Side input current measured at the point of control inside the DC/AC Accessory Inverter.";
CM_ SG_ 2364614910 DCSideV "DC Side input voltage measured at the point of control inside the DC/AC Accessory Inverter.";
CM_ SG_ 2364614910 DCSidePwr "Power measured at the DC Side input to the DC/AC Accessory Inverter.";
CM_ BO_ 2364614654 "Slope Sensor Information 3
Provides additional grade or slope data.";
CM_ SG_ 2364614654 GradeThresholdInd6 "This parameter indicates whether or not the transmitting device has sensed a vehicle grade equal to or exceeding a manufacturer-defined threshold. The manufacturer-defined threshold could be a simple fixed value or a dynamic value that changes based ...";
CM_ SG_ 2364614654 GradeThresholdInd5 "This parameter indicates whether or not the transmitting device has sensed a vehicle grade equal to or exceeding a manufacturer-defined threshold. The manufacturer-defined threshold could be a simple fixed value or a dynamic value that changes based ...";
CM_ SG_ 2364614654 GradeThresholdInd4 "This parameter indicates whether or not the transmitting device has sensed a vehicle grade equal to or exceeding a manufacturer-defined threshold. The manufacturer-defined threshold could be a simple fixed value or a dynamic value that changes based ...";
CM_ SG_ 2364614654 GradeThresholdInd3 "This parameter indicates whether or not the transmitting device has sensed a vehicle grade equal to or exceeding a manufacturer-defined threshold. The manufacturer-defined threshold could be a simple fixed value or a dynamic value that changes based ...";
CM_ SG_ 2364614654 GradeThresholdInd2 "This parameter indicates whether or not the transmitting device has sensed a vehicle grade equal to or exceeding a manufacturer-defined threshold. The manufacturer-defined threshold could be a simple fixed value or a dynamic value that changes based ...";
CM_ SG_ 2364614654 GradeThresholdInd1 "This parameter indicates whether or not the transmitting device has sensed a vehicle grade equal to or exceeding a manufacturer-defined threshold. The manufacturer-defined threshold could be a simple fixed value or a dynamic value that changes based ...";
CM_ BO_ 2364614398 "DC/DC Converter 4 Status 2
Additional data reported from a DC/DC Converter";
CM_ SG_ 2364614398 FourHiSideNegToChassisGroundV "The voltage level of the high voltage DC side, as measured by the DC/DC between the negative side of the High Voltage DC Side input and the chassis of the DC/DC enclosure.  This voltage can be used for system level monitoring of DC Side High Voltage ...";
CM_ SG_ 2364614398 FourHiSidePwr "Indicates the measured HVES or high side power measured at the DC/DC Converter.  The high side power is positive if the converter is charging the hybrid battery from the SLI battery (i.e. Boost Mode).  The high side power is negative if the ...";
CM_ SG_ 2364614398 FourLowSidePwr "Indicates the measured SLI battery or low side power measured at the DC/DC Converter.  The low side power is positive if the converter is charging the SLI battery from the hybrid battery (i.e. Buck Mode).  The low side power is negative if the ...";
CM_ BO_ 2364614142 "DC/DC Converter 4 SLI Battery Status
Status of the SLI battery measured at the SLI battery terminals.

One intended use of this message is for a conventional engine mounted alternator replacement.";
CM_ SG_ 2364614142 SLIBatTermTemp "Parameter indicating the SLI battery terminal temperature for control use by the DC/DC converter.";
CM_ SG_ 2364614142 SLIBatTermCur "Parameter indicating the SLI battery terminal current for control use by the DC/DC converter.  The current is positive if the SLI battery or low side voltage source is being charged from the HVES.";
CM_ SG_ 2364614142 SLIBatTermV "Parameter indicating the SLI battery terminal voltage for control use by the DC/DC converter.";
CM_ BO_ 2364613886 "DC/DC Converter 4 Voltage and Current
Voltage and current data from a DC/DC Converter.

One intended use of this message is for a conventional engine mounted alternator replacement.";
CM_ SG_ 2364613886 FourHiSideCur "Indicates the measured HVES or high side current measured at the point of control inside the DC/DC Converter.  The current is negative if the converter is charging the SLI battery from the hybrid battery.";
CM_ SG_ 2364613886 FourHiSideV "Indicates the measured HVES or high side voltage measured at the point of control inside the DC/DC Converter.";
CM_ SG_ 2364613886 FourLowSideCur "Indicates the measured SLI battery or low side current measured at the point of control inside the DC/DC Converter.  The current is positive if the converter is charging the SLI battery from the hybrid battery.";
CM_ SG_ 2364613886 FourLowSideV "Indicates the measured SLI battery or low side voltage measured at the point of control inside the DC/DC Converter.";
CM_ BO_ 2364613630 "DC/DC Converter 4 Operating Status
Contains information on the operating status of a DC/DC Converter.

One intended use of this message is for a conventional engine mounted alternator replacement.";
CM_ SG_ 2364613630 DCDC4OperatingStatusCRC "The CRC is defined as follows:
• Length: 8 bits
• Polynomial: x^8+x^5+x^3+x^2+x+1
• Initial Value: FFh
• Input Data Reflection: Not reflected
• Result Data Reflection: Not reflected
• XOR value: FFh
SAE makes no claim of the functional safety ...";
CM_ SG_ 2364613630 DCDC4OperatingStatusCounter "The message counter is used to detect situations where the transmitting ECU malfunction repeats the same frame all the time. The receiver of the information may use the counter parameter to detect this situation. The transmitting device will ...";
CM_ SG_ 2364613630 FourPLDueToUndefinedReason "Indicates whether or not output power is being limited due to an undefined reason.

00b = No power limit for this reason
01b = Power limited for this reason
10b = Error
11b = Not Available";
CM_ SG_ 2364613630 FourPLDueToSLIBatTermTemp "Indicates whether or not output power is being limited due to the SLI battery terminal temperature (see SPN 9027) approaching or exceeding limits (see SPN 9045).
00b = No power limit for this reason
01b = Power limited for this reason
10b = Error
 ...";
CM_ SG_ 2364613630 FourPLDueToSLIBatTermCur "Indicates whether or not output power is being limited due to the SLI battery terminal current (see SPN 9026) approaching or exceeding limits (see SPN 9044).
00b = No power limit for this reason
01b = Power limited for this reason
10b = Error
 ...";
CM_ SG_ 2364613630 FourPLDueToSLIBatTermV "Indicates whether or not output power is being limited due to the SLI battery terminal voltage (see SPN 9025) approaching or exceeding limits (see SPN 9043).
00b = No power limit for this reason
01b = Power limited for this reason
10b = Error
 ...";
CM_ SG_ 2364613630 FourPLDueToPwrETemp "Indicates whether or not output power is being limited due to Power Electronics Temperature (see SPN 9048) approaching or exceeding the maximum limit.
00b = No power limit for this reason
01b = Power limited for this reason
10b = Error
11b = Not ...";
CM_ SG_ 2364613630 FourPLDueToEFilterTemp "Indicates whether or not output power is being limited due to Output Electronic Filter Temperature (see SPN 9047) approaching or exceeding the maximum limit.
00b = No power limit for this reason
01b = Power limited for this reason
10b = Error
 ...";
CM_ SG_ 2364613630 FourPLDueToConvTemp "Indicates whether or not output power is being limited due to Converter Temperature (see SPN 9046) approaching or exceeding the maximum limit.
00b = No power limit for this reason
01b = Power limited for this reason
10b = Error
11b = Not ...";
CM_ SG_ 2364613630 FourPLDueToLowSideVMax "Indicates whether or not output power is being limited due to low side voltage (see SPN 9021) approaching or exceeding the maximum limit (see SPN 9052).
00b = No power limit for this reason
01b = Power limited for this reason
10b = Error
11b = ...";
CM_ SG_ 2364613630 FourPLDueToLowSideVMin "Indicates whether or not output power is being limited due to low side voltage (see SPN 9021) approaching or falling below the minimum limit (see SPN 9051).
00b = No power limit for this reason
01b = Power limited for this reason
10b = Error
11b ...";
CM_ SG_ 2364613630 FourPLDueToHiSideVMax "Indicates whether or not output power is being limited due to high side voltage (see SPN 9023) approaching or exceeding the maximum limit (see SPN 9055).
00b = No power limit for this reason
01b = Power limited for this reason
10b = Error
11b = ...";
CM_ SG_ 2364613630 FourPLDueToHiSideVMin "Indicates whether or not output power is being limited due to high side voltage (see SPN 9023) approaching or falling below the minimum limit (see SPN 9054).
00b = No power limit for this reason
01b = Power limited for this reason
10b = Error
 ...";
CM_ SG_ 2364613630 FourPLDueToLowSideCur "Indicates whether or not output power is being limited due to low side current (see SPN 9022) approaching or exceeding the maximum limit (see SPN 9053).
00b = No power limit for this reason
01b = Power limited for this reason
10b = Error
11b = ...";
CM_ SG_ 2364613630 FourPLDueToHiSideCur "Indicates whether or not output power is being limited due to high side current (see SPN 9024) approaching or exceeding the maximum limit (see SPN 9056).
00b = No power limit for this reason
01b = Power limited for this reason
10b = Error
11b = ...";
CM_ SG_ 2364613630 FourLoadshedReq "The loadshed request is a request to the controlling device to reduce the DC/DC Converter loads.  The Loadshed Requested state is an indication that this DC/DC Converter has a malfunction or is in a limit condition and if the load of the output is ...";
CM_ SG_ 2364613630 FourHVILStatus "High Voltage Interlock Loop (HVIL) state of the DC/DC Converter.

00b = HVIL Closed
01b = HVIL Open
10b = Error
11b = Not Available";
CM_ SG_ 2364613630 FourOperationalStatus "Operating state of the DC/DC Converter
0000b = Disabled
0001b = Initialization in process.  The device is powering up.  This process may include both internal checks, as well as system checks being run by the DC/DC Converter.
0010b = Operational ...";
CM_ BO_ 2364613374 "DC/DC Converter 4 Control
Controls the transfer of energy between the HVES or high voltage system (i.e. high side) and the SLI battery or low voltage system (i.e. low side).  Provides a function to either charge the SLI Battery from the HVES (Buck) ...";
CM_ SG_ 2364613374 DCDC4CtrlCRC "The CRC is defined as follows:
• Length: 8 bits
• Polynomial: x^8+x^5+x^3+x^2+x+1
• Initial Value: FFh
• Input Data Reflection: Not reflected
• Result Data Reflection: Not reflected
• XOR value: FFh
SAE makes no claim of the functional safety ...";
CM_ SG_ 2364613374 DCDC4CtrlCounter "The message counter is used to detect situations where the transmitting ECU malfunction repeats the same frame all the time. The receiver of the information may use the counter parameter to detect this situation. The transmitting device will ...";
CM_ SG_ 2364613374 FourLowSideVBuckDefaultSetpoint "The set point for the converter default low side voltage during buck mode.   This setting may be used for when communication has been lost with the controlling device.  When set to Not Available (FFFFh), no default setting is provided and the system ...";
CM_ SG_ 2364613374 FourHiSideVBoostSetpoint "The set point for regulating the high side voltage during boost mode.";
CM_ SG_ 2364613374 FourLowSideVBuckSetpoint "The set point for regulating the low side voltage during buck mode.";
CM_ SG_ 2364613374 FourOperationalCmd "Command to enable or disable operation.
0000b = Disable - in this mode all high voltage switching is disabled
0001b = Operate in standby mode; system is waiting for command to enter buck or boost mode
0010b = Operate in buck mode; energy flows ...";
CM_ BO_ 2364613118 "DC/DC Converter 3 Status 2
Additional data reported from a DC/DC Converter";
CM_ SG_ 2364613118 ThreeHiSideNegToChassisGroundV "The voltage level of the high voltage DC side, as measured by the DC/DC between the negative side of the High Voltage DC Side input and the chassis of the DC/DC enclosure.  This voltage can be used for system level monitoring of DC Side High Voltage ...";
CM_ SG_ 2364613118 ThreeHiSidePwr "Indicates the measured HVES or high side power measured at the DC/DC Converter.  The high side power is positive if the converter is charging the hybrid battery from the SLI battery (i.e. Boost Mode).  The high side power is negative if the ...";
CM_ SG_ 2364613118 ThreeLowSidePwr "Indicates the measured SLI battery or low side power measured at the DC/DC Converter.  The low side power is positive if the converter is charging the SLI battery from the hybrid battery (i.e. Buck Mode).  The low side power is negative if the ...";
CM_ BO_ 2364612862 "DC/DC Converter 3 SLI Battery Status
Status of the SLI battery measured at the SLI battery terminals.

One intended use of this message is for a conventional engine mounted alternator replacement.";
CM_ SG_ 2364612862 SLIBatTermTemp "Parameter indicating the SLI battery terminal temperature for control use by the DC/DC converter.";
CM_ SG_ 2364612862 SLIBatTermCur "Parameter indicating the SLI battery terminal current for control use by the DC/DC converter.  The current is positive if the SLI battery or low side voltage source is being charged from the HVES.";
CM_ SG_ 2364612862 SLIBatTermV "Parameter indicating the SLI battery terminal voltage for control use by the DC/DC converter.";
CM_ BO_ 2364612606 "DC/DC Converter 3 Voltage and Current
Voltage and current data from a DC/DC Converter.

One intended use of this message is for a conventional engine mounted alternator replacement.";
CM_ SG_ 2364612606 ThreeHiSideCur "Indicates the measured HVES or high side current measured at the point of control inside the DC/DC Converter.  The current is negative if the converter is charging the SLI battery from the hybrid battery.";
CM_ SG_ 2364612606 ThreeHiSideV "Indicates the measured HVES or high side voltage measured at the point of control inside the DC/DC Converter.";
CM_ SG_ 2364612606 ThreeLowSideCur "Indicates the measured SLI battery or low side current measured at the point of control inside the DC/DC Converter.  The current is positive if the converter is charging the SLI battery from the hybrid battery.";
CM_ SG_ 2364612606 ThreeLowSideV "Indicates the measured SLI battery or low side voltage measured at the point of control inside the DC/DC Converter.";
CM_ BO_ 2364612350 "DC/DC Converter 3 Operating Status
Contains information on the operating status of a DC/DC Converter.

One intended use of this message is for a conventional engine mounted alternator replacement.";
CM_ SG_ 2364612350 DCDC3OperatingStatusCRC "The CRC is defined as follows:
• Length: 8 bits
• Polynomial: x^8+x^5+x^3+x^2+x+1
• Initial Value: FFh
• Input Data Reflection: Not reflected
• Result Data Reflection: Not reflected
• XOR value: FFh
SAE makes no claim of the functional safety ...";
CM_ SG_ 2364612350 DCDC3OperatingStatusCounter "The message counter is used to detect situations where the transmitting ECU malfunction repeats the same frame all the time. The receiver of the information may use the counter parameter to detect this situation. The transmitting device will ...";
CM_ SG_ 2364612350 ThreePLDueToUndefinedReason "Indicates whether or not output power is being limited due to an undefined reason.

00b = No power limit for this reason
01b = Power limited for this reason
10b = Error
11b = Not Available";
CM_ SG_ 2364612350 ThreePLDueToSLIBatTermTemp "Indicates whether or not output power is being limited due to the SLI battery terminal temperature (see SPN 8972) approaching or exceeding limits (see SPN 8990).
00b = No power limit for this reason
01b = Power limited for this reason
10b = Error
 ...";
CM_ SG_ 2364612350 ThreePLDueToSLIBatTermCur "Indicates whether or not output power is being limited due to the SLI battery terminal current (see SPN 8971) approaching or exceeding limits (see SPN 8989).
00b = No power limit for this reason
01b = Power limited for this reason
10b = Error
 ...";
CM_ SG_ 2364612350 ThreePLDueToSLIBatTermV "Indicates whether or not output power is being limited due to the SLI battery terminal voltage (see SPN 8970) approaching or exceeding limits (see SPN 8988).
00b = No power limit for this reason
01b = Power limited for this reason
10b = Error
 ...";
CM_ SG_ 2364612350 ThreePLDueToPwrETemp "Indicates whether or not output power is being limited due to Power Electronics Temperature (see SPN 8993) approaching or exceeding the maximum limit.
00b = No power limit for this reason
01b = Power limited for this reason
10b = Error
11b = Not ...";
CM_ SG_ 2364612350 ThreePLDueToEFilterTemp "Indicates whether or not output power is being limited due to Output Electronic Filter Temperature (see SPN 8992) approaching or exceeding the maximum limit.
00b = No power limit for this reason
01b = Power limited for this reason
10b = Error
 ...";
CM_ SG_ 2364612350 ThreePLDueToConvTemp "Indicates whether or not output power is being limited due to Converter Temperature (see SPN 8991) approaching or exceeding the maximum limit.
00b = No power limit for this reason
01b = Power limited for this reason
10b = Error
11b = Not ...";
CM_ SG_ 2364612350 ThreePLDueToLowSideVMax "Indicates whether or not output power is being limited due to low side voltage (see SPN 8966) approaching or exceeding the maximum limit (see SPN 8997).
00b = No power limit for this reason
01b = Power limited for this reason
10b = Error
11b = ...";
CM_ SG_ 2364612350 ThreePLDueToLowSideVMin "Indicates whether or not output power is being limited due to low side voltage (see SPN 8966) approaching or falling below the minimum limit (see SPN 8996).
00b = No power limit for this reason
01b = Power limited for this reason
10b = Error
11b ...";
CM_ SG_ 2364612350 ThreePLDueToHiSideVMax "Indicates whether or not output power is being limited due to high side voltage (see SPN 8968) approaching or exceeding the maximum limit (see SPN 9000).
00b = No power limit for this reason
01b = Power limited for this reason
10b = Error
11b = ...";
CM_ SG_ 2364612350 ThreePLDueToHiSideVMin "Indicates whether or not output power is being limited due to high side voltage (see SPN 8968) approaching or falling below the minimum limit (see SPN 8999).
00b = No power limit for this reason
01b = Power limited for this reason
10b = Error
 ...";
CM_ SG_ 2364612350 ThreePLDueToLowSideCur "Indicates whether or not output power is being limited due to low side current (see SPN 8967) approaching or exceeding the maximum limit (see SPN 8998).
00b = No power limit for this reason
01b = Power limited for this reason
10b = Error
11b = ...";
CM_ SG_ 2364612350 ThreePLDueToHiSideCur "Indicates whether or not output power is being limited due to high side current (see SPN 8969) approaching or exceeding the maximum limit (see SPN 9001).
00b = No power limit for this reason
01b = Power limited for this reason
10b = Error
11b = ...";
CM_ SG_ 2364612350 ThreeLoadshedReq "The loadshed request is a request to the controlling device to reduce the DC/DC Converter loads.  The Loadshed Requested state is an indication that this DC/DC Converter has a malfunction or is in a limit condition and if the load of the output is ...";
CM_ SG_ 2364612350 ThreeHVILStatus "High Voltage Interlock Loop (HVIL) state of the DC/DC Converter.

00b = HVIL Closed
01b = HVIL Open
10b = Error
11b = Not Available";
CM_ SG_ 2364612350 ThreeOperationalStatus "Operating state of the DC/DC Converter
0000b = Disabled
0001b = Initialization in process.  The device is powering up.  This process may include both internal checks, as well as system checks being run by the DC/DC Converter.
0010b = Operational ...";
CM_ BO_ 2364612094 "DC/DC Converter 3 Control
Controls the transfer of energy between the HVES or high voltage system (i.e. high side) and the SLI battery or low voltage system (i.e. low side).  Provides a function to either charge the SLI Battery from the HVES (Buck) ...";
CM_ SG_ 2364612094 DCDC3CtrlCRC "The CRC is defined as follows:
• Length: 8 bits
• Polynomial: x^8+x^5+x^3+x^2+x+1
• Initial Value: FFh
• Input Data Reflection: Not reflected
• Result Data Reflection: Not reflected
• XOR value: FFh
SAE makes no claim of the functional safety ...";
CM_ SG_ 2364612094 DCDC3CtrlCounter "The message counter is used to detect situations where the transmitting ECU malfunction repeats the same frame all the time. The receiver of the information may use the counter parameter to detect this situation. The transmitting device will ...";
CM_ SG_ 2364612094 ThreeLowSideVBuckDefaultSetpoint "The set point for the converter default low side voltage during buck mode.   This setting may be used for when communication has been lost with the controlling device.  When set to Not Available (FFFFh), no default setting is provided and the system ...";
CM_ SG_ 2364612094 ThreeHiSideVBoostSetpoint "The set point for regulating the high side voltage during boost mode.";
CM_ SG_ 2364612094 ThreeLowSideVBuckSetpoint "The set point for regulating the low side voltage during buck mode.";
CM_ SG_ 2364612094 ThreeOperationalCmd "Command to enable or disable operation.
0000b = Disable - in this mode all high voltage switching is disabled
0001b = Operate in standby mode; system is waiting for command to enter buck or boost mode
0010b = Operate in buck mode; energy flows ...";
CM_ BO_ 2364611838 "DC/DC Converter 2 Status 2
Additional data reported from a DC/DC Converter";
CM_ SG_ 2364611838 TwoHiSideNegToChassisGroundV "The voltage level of the high voltage DC side, as measured by the DC/DC between the negative side of the High Voltage DC Side input and the chassis of the DC/DC enclosure.  This voltage can be used for system level monitoring of DC Side High Voltage ...";
CM_ SG_ 2364611838 TwoHiSidePwr "Indicates the measured HVES or high side power measured at the DC/DC Converter.  The high side power is positive if the converter is charging the hybrid battery from the SLI battery (i.e. Boost Mode).  The high side power is negative if the ...";
CM_ SG_ 2364611838 TwoLowSidePwr "Indicates the measured SLI battery or low side power measured at the DC/DC Converter.  The low side power is positive if the converter is charging the SLI battery from the hybrid battery (i.e. Buck Mode).  The low side power is negative if the ...";
CM_ BO_ 2364611582 "DC/DC Converter 2 SLI Battery Status
Status of the SLI battery measured at the SLI battery terminals.

One intended use of this message is for a conventional engine mounted alternator replacement.";
CM_ SG_ 2364611582 SLIBatTermTemp "Parameter indicating the SLI battery terminal temperature for control use by the DC/DC converter.";
CM_ SG_ 2364611582 SLIBatTermCur "Parameter indicating the SLI battery terminal current for control use by the DC/DC converter.  The current is positive if the SLI battery or low side voltage source is being charged from the HVES.";
CM_ SG_ 2364611582 SLIBatTermV "Parameter indicating the SLI battery terminal voltage for control use by the DC/DC converter.";
CM_ BO_ 2364611326 "DC/DC Converter 2 Voltage and Current
Voltage and current data from a DC/DC Converter.

One intended use of this message is for a conventional engine mounted alternator replacement.";
CM_ SG_ 2364611326 TwoHiSideCur "Indicates the measured HVES or high side current measured at the point of control inside the DC/DC Converter.  The current is negative if the converter is charging the SLI battery from the hybrid battery.";
CM_ SG_ 2364611326 TwoHiSideV "Indicates the measured HVES or high side voltage measured at the point of control inside the DC/DC Converter.";
CM_ SG_ 2364611326 TwoLowSideCur "Indicates the measured SLI battery or low side current measured at the point of control inside the DC/DC Converter.  The current is positive if the converter is charging the SLI battery from the hybrid battery.";
CM_ SG_ 2364611326 TwoLowSideV "Indicates the measured SLI battery or low side voltage measured at the point of control inside the DC/DC Converter.";
CM_ BO_ 2364611070 "DC/DC Converter 2 Operating Status
Contains information on the operating status of a DC/DC Converter.

One intended use of this message is for a conventional engine mounted alternator replacement.";
CM_ SG_ 2364611070 DCDC2OperatingStatusCRC "The CRC is defined as follows:
• Length: 8 bits
• Polynomial: x^8+x^5+x^3+x^2+x+1
• Initial Value: FFh
• Input Data Reflection: Not reflected
• Result Data Reflection: Not reflected
• XOR value: FFh
SAE makes no claim of the functional safety ...";
CM_ SG_ 2364611070 DCDC2OperatingStatusCounter "The message counter is used to detect situations where the transmitting ECU malfunction repeats the same frame all the time. The receiver of the information may use the counter parameter to detect this situation. The transmitting device will ...";
CM_ SG_ 2364611070 TwoPLDueToUndefinedReason "Indicates whether or not output power is being limited due to an undefined reason.

00b = No power limit for this reason
01b = Power limited for this reason
10b = Error
11b = Not Available";
CM_ SG_ 2364611070 TwoPLDueToSLIBatTermTemp "Indicates whether or not output power is being limited due to the SLI battery terminal temperature (see SPN 8917) approaching or exceeding limits (see SPN 8935).
00b = No power limit for this reason
01b = Power limited for this reason
10b = Error
 ...";
CM_ SG_ 2364611070 TwoPLDueToSLIBatTermCur "Indicates whether or not output power is being limited due to the SLI battery terminal current (see SPN 8916) approaching or exceeding limits (see SPN 8934).
00b = No power limit for this reason
01b = Power limited for this reason
10b = Error
 ...";
CM_ SG_ 2364611070 TwoPLDueToSLIBatTermV "Indicates whether or not output power is being limited due to the SLI battery terminal voltage (see SPN 8915) approaching or exceeding limits (see SPN 8933).
00b = No power limit for this reason
01b = Power limited for this reason
10b = Error
 ...";
CM_ SG_ 2364611070 TwoPLDueToPwrETemp "Indicates whether or not output power is being limited due to Power Electronics Temperature (see SPN 8938) approaching or exceeding the maximum limit.
00b = No power limit for this reason
01b = Power limited for this reason
10b = Error
11b = Not ...";
CM_ SG_ 2364611070 TwoPLDueToEFilterTemp "Indicates whether or not output power is being limited due to Output Electronic Filter Temperature (see SPN 8937) approaching or exceeding the maximum limit.
00b = No power limit for this reason
01b = Power limited for this reason
10b = Error
 ...";
CM_ SG_ 2364611070 TwoPLDueToConvTemp "Indicates whether or not output power is being limited due to Converter Temperature (see SPN 8936) approaching or exceeding the maximum limit.
00b = No power limit for this reason
01b = Power limited for this reason
10b = Error
11b = Not ...";
CM_ SG_ 2364611070 TwoPLDueToLowSideVMax "Indicates whether or not output power is being limited due to low side voltage (see SPN 8911) approaching or exceeding the maximum limit (see SPN 8942).
00b = No power limit for this reason
01b = Power limited for this reason
10b = Error
11b = ...";
CM_ SG_ 2364611070 TwoPLDueToLowSideVMin "Indicates whether or not output power is being limited due to low side voltage (see SPN 8911) approaching or falling below the minimum limit (see SPN 8941).
00b = No power limit for this reason
01b = Power limited for this reason
10b = Error
11b ...";
CM_ SG_ 2364611070 TwoPLDueToHiSideVMax "Indicates whether or not output power is being limited due to high side voltage (see SPN 8913) approaching or exceeding the maximum limit (see SPN 8945).
00b = No power limit for this reason
01b = Power limited for this reason
10b = Error
11b = ...";
CM_ SG_ 2364611070 TwoPLDueToHiSideVMin "Indicates whether or not output power is being limited due to high side voltage (see SPN 8913) approaching or falling below the minimum limit (see SPN 8944).
00b = No power limit for this reason
01b = Power limited for this reason
10b = Error
 ...";
CM_ SG_ 2364611070 TwoPLDueToLowSideCur "Indicates whether or not output power is being limited due to low side current (see SPN 8912) approaching or exceeding the maximum limit (see SPN 8943).
00b = No power limit for this reason
01b = Power limited for this reason
10b = Error
11b = ...";
CM_ SG_ 2364611070 TwoPLDueToHiSideCur "Indicates whether or not output power is being limited due to high side current (see SPN 8914) approaching or exceeding the maximum limit (see SPN 8946).
00b = No power limit for this reason
01b = Power limited for this reason
10b = Error
11b = ...";
CM_ SG_ 2364611070 TwoLoadshedReq "The loadshed request is a request to the controlling device to reduce the DC/DC Converter loads.  The Loadshed Requested state is an indication that this DC/DC Converter has a malfunction or is in a limit condition and if the load of the output is ...";
CM_ SG_ 2364611070 TwoHVILStatus "High Voltage Interlock Loop (HVIL) state of the DC/DC Converter.

00b = HVIL Closed
01b = HVIL Open
10b = Error
11b = Not Available";
CM_ SG_ 2364611070 TwoOperationalStatus "Operating state of the DC/DC Converter
0000b = Disabled
0001b = Initialization in process.  The device is powering up.  This process may include both internal checks, as well as system checks being run by the DC/DC Converter.
0010b = Operational ...";
CM_ BO_ 2364610814 "DC/DC Converter 2 Control
Controls the transfer of energy between the HVES or high voltage system (i.e. high side) and the SLI battery or low voltage system (i.e. low side).  Provides a function to either charge the SLI Battery from the HVES (Buck) ...";
CM_ SG_ 2364610814 DCDC2CtrlCRC "The CRC is defined as follows:
• Length: 8 bits
• Polynomial: x^8+x^5+x^3+x^2+x+1
• Initial Value: FFh
• Input Data Reflection: Not reflected
• Result Data Reflection: Not reflected
• XOR value: FFh
SAE makes no claim of the functional safety ...";
CM_ SG_ 2364610814 DCDC2CtrlCounter "The message counter is used to detect situations where the transmitting ECU malfunction repeats the same frame all the time. The receiver of the information may use the counter parameter to detect this situation. The transmitting device will ...";
CM_ SG_ 2364610814 TwoLowSideVBuckDefaultSetpoint "The set point for the converter default low side voltage during buck mode.   This setting may be used for when communication has been lost with the controlling device.  When set to Not Available (FFFFh), no default setting is provided and the system ...";
CM_ SG_ 2364610814 TwoHiSideVBoostSetpoint "The set point for regulating the high side voltage during boost mode.";
CM_ SG_ 2364610814 TwoLowSideVBuckSetpoint "The set point for regulating the low side voltage during buck mode.";
CM_ SG_ 2364610814 TwoOperationalCmd "Command to enable or disable operation.
0000b = Disable - in this mode all high voltage switching is disabled
0001b = Operate in standby mode; system is waiting for command to enter buck or boost mode
0010b = Operate in buck mode; energy flows ...";
CM_ BO_ 2364610558 "DC/DC Converter 1 Status 2
Additional data reported from a DC/DC Converter";
CM_ SG_ 2364610558 OneHiSideNegToChassisGroundV "The voltage level of the high voltage DC side, as measured by the DC/DC between the negative side of the High Voltage DC Side input and the chassis of the DC/DC enclosure.  This voltage can be used for system level monitoring of DC Side High Voltage ...";
CM_ SG_ 2364610558 OneHiSidePwr "Indicates the measured HVES or high side power measured at the DC/DC Converter.  The high side power is positive if the converter is charging the hybrid battery from the SLI battery (i.e. Boost Mode).  The high side power is negative if the ...";
CM_ SG_ 2364610558 OneLowSidePwr "Indicates the measured SLI battery or low side power measured at the DC/DC Converter.  The low side power is positive if the converter is charging the SLI battery from the hybrid battery (i.e. Buck Mode).  The low side power is negative if the ...";
CM_ BO_ 2565918206 "DC/AC Accessory Inverter 2 Feedback 2
Sent by this Accessory Inverter instance and contains the current operating conditions of this output of the inverter.  This message would be received by a controller application (e.g. Power System Manager) ...";
CM_ SG_ 2565918206 PLedDueToUndefinedReason "Output power is being limited due to an undefined reason.

00b = No power limit for this reason
01b = Power limited for this reason
10b = Error
11b = Not Available";
CM_ SG_ 2565918206 PLedDueToRateOfChangeLmt "Output power is being limited due to the frequency approaching or exceeding the rate of change limit (see SPN 8346).

00b = No power limit for this reason
01b = Power limited for this reason
10b = Error
11b = Not Available";
CM_ SG_ 2565918206 PLedDueToPwrETemp "Output power is being limited due to power electronics temperature (see SPN 9233) approaching or exceeding the maximum limit.

00b = No power limit for this reason
01b = Power limited for this reason
10b = Error
11b = Not Available";
CM_ SG_ 2565918206 PLedDueToEFilterTemp "Output power is being limited due to electronic filter temperature (see SPN 9232) approaching or exceeding the maximum limit.

00b = No power limit for this reason
01b = Power limited for this reason
10b = Error
11b = Not Available";
CM_ SG_ 2565918206 PLedDueToCtrlTemp "Output power is being limited due to the controller temperature (see SPN 9231) approaching or exceeding the maximum limit.

00b = No power limit for this reason
01b = Power limited for this reason
10b = Error
11b = Not Available";
CM_ SG_ 2565918206 FreqCmdExceedsMax "Output frequency is being limited due to frequency command (see SPN 8347) approaching or exceeding the maximum limit (SPN 8342).

00b = No frequency limit for this reason
01b = Frequency limited for this reason
10b = Error
11b = Not Available";
CM_ SG_ 2565918206 FreqCmdBelowMin "Output frequency is being limited due to frequency command (see SPN 8347) approaching or falling below the minimum limit (SPN 8343).
00b = No frequency limit for this reason
01b = Frequency limited for this reason
10b = Error
11b = Not Available
 ...";
CM_ SG_ 2565918206 PLedDueToDCSideVMin "Output power is being limited due to DC Side input voltage (see SPN 9237) approaching or falling below the minimum limit (SPN 9255).

00b = No power limit for this reason
01b = Power limited for this reason
10b = Error
11b = Not Available";
CM_ SG_ 2565918206 PLedDueToACSideRMSCur "AC Side Output power is being limited due to AC Side output RMS current (see SPN 9201) approaching or exceeding the maximum limit (See SPN 9258).
00b = No power limit for this reason
01b = Power limited for this reason
10b = Error
11b = Not ...";
CM_ SG_ 2565918206 PLedDueToDCSideCur "Output power is being limited due to DC Side input current (see SPN 9238) approaching or exceeding the maximum limit (See SPN 9256).

00b = No power limit for this reason
01b = Power limited for this reason
10b = Error
11b = Not Available";
CM_ BO_ 2364591358 "DC/AC Accessory Inverter 2 Voltage
Low Voltage data from DC/AC Accessory Inverter.";
CM_ SG_ 2364591358 SLIV "Continuously supplied SLI power to this instance of the DC/AC Accessory Inverter controller.";
CM_ SG_ 2364591358 IgntV "Ignition voltage supplied to the  DC/AC Accessory Inverter controller.";
CM_ BO_ 2364591102 "DC/AC Accessory Inverter 2 Status 2
Additional data reported from DC/AC Accessory Inverter";
CM_ SG_ 2364591102 DCSideNegToChassisGroundV "The voltage level of the high voltage DC side, as measured by the DC/AC between the negative side of the High Voltage DC Side input and the chassis of the DC/AC enclosure.  This voltage can be used for system level monitoring of DC Side High Voltage ...";
CM_ SG_ 2364591102 DCSideCur "DC Side input current measured at the point of control inside the DC/AC Accessory Inverter.";
CM_ SG_ 2364591102 DCSideV "DC Side input voltage measured at the point of control inside the DC/AC Accessory Inverter.";
CM_ SG_ 2364591102 DCSidePwr "Power measured at the DC Side input to the DC/AC Accessory Inverter.";
BA_DEF_ SG_  "GenSigInactiveValue" INT 0 0;
BA_DEF_ SG_  "SigType" ENUM  "Default","Range","RangeSigned","ASCII","Discrete","Control","ReferencePGN","DTC","StringDelimiter","StringLength","StringLengthControl","MessageCounter","MessageChecksum";
BA_DEF_ SG_  "GenSigStartValue" INT 0 2147483647;
BA_DEF_ SG_  "GenSigSendType" ENUM  "Cyclic","OnWrite","OnWriteWithRepetition","OnChange","OnChangeWithRepetition","IfActive","IfActiveWithRepetition","NoSigSendType";
BA_DEF_ SG_  "GenSigILSupport" ENUM  "No","Yes";
BA_DEF_ SG_  "SPN" INT 0 524287;
BA_DEF_ BO_  "J1939CPgSendTimeout" INT -1 3600000;
BA_DEF_ BO_  "J1939CPgTOS" INT 0 7;
BA_DEF_ BO_  "J1939PgAppearanceOnBus" ENUM  "Default","CAN_Extended","CANFD_Extended";
BA_DEF_ BO_  "FsJ1939UseCrcAndCounter" STRING ;
BA_DEF_ BO_  "TpJ1939VarDlc" ENUM  "No","Yes";
BA_DEF_ BO_  "GenMsgNrOfRepetition" INT 0 1000000;
BA_DEF_ BO_  "GenMsgCycleTimeFast" INT 0 3600000;
BA_DEF_ BO_  "GenMsgFastOnStart" INT 0 100000;
BA_DEF_ BO_  "GenMsgStartDelayTime" INT 0 100000;
BA_DEF_ BO_  "GenMsgILSupport" ENUM  "No","Yes";
BA_DEF_ BO_  "GenMsgDelayTime" INT 0 1000;
BA_DEF_ BO_  "GenMsgRequestable" INT 0 1;
BA_DEF_ BO_  "GenMsgSendType" ENUM  "cyclic","NotUsed","NotUsed","NotUsed","NotUsed","NotUsed","NotUsed","IfActive","noMsgSendType";
BA_DEF_ BO_  "VFrameFormat" ENUM  "StandardCAN","ExtendedCAN","reserved","J1939PG","reserved","reserved","reserved","reserved","reserved","reserved","reserved","reserved","reserved","reserved","StandardCAN_FD","ExtendedCAN_FD";
BA_DEF_ BO_  "SingleFrame" INT 0 1;
BA_DEF_ BO_  "GenMsgCycleTime" INT 0 3600000;
BA_DEF_ SG_  "SystemSignalLongSymbol" STRING ;
BA_DEF_DEF_  "GenSigInactiveValue" 0;
BA_DEF_DEF_  "SigType" "Default";
BA_DEF_DEF_  "GenSigStartValue" 0;
BA_DEF_DEF_  "GenSigSendType" "NoSigSendType";
BA_DEF_DEF_  "GenSigILSupport" "Yes";
BA_DEF_DEF_  "SPN" 0;
BA_DEF_DEF_  "J1939CPgSendTimeout" -1;
BA_DEF_DEF_  "J1939CPgTOS" 2;
BA_DEF_DEF_  "J1939PgAppearanceOnBus" "Default";
BA_DEF_DEF_  "FsJ1939UseCrcAndCounter" "";
BA_DEF_DEF_  "TpJ1939VarDlc" "No";
BA_DEF_DEF_  "GenMsgNrOfRepetition" 0;
BA_DEF_DEF_  "GenMsgCycleTimeFast" 0;
BA_DEF_DEF_  "GenMsgFastOnStart" 0;
BA_DEF_DEF_  "GenMsgStartDelayTime" 0;
BA_DEF_DEF_  "GenMsgILSupport" "Yes";
BA_DEF_DEF_  "GenMsgDelayTime" 0;
BA_DEF_DEF_  "GenMsgRequestable" 1;
BA_DEF_DEF_  "GenMsgSendType" "noMsgSendType";
BA_DEF_DEF_  "VFrameFormat" "J1939PG";
BA_DEF_DEF_  "SingleFrame" 1;
BA_DEF_DEF_  "GenMsgCycleTime" 0;
BA_DEF_DEF_  "SystemSignalLongSymbol" "";
BA_ "GenMsgSendType" BO_ 2566630398 0;
BA_ "GenMsgCycleTime" BO_ 2566630398 5000;
BA_ "GenMsgSendType" BO_ 2365303550 0;
BA_ "GenMsgCycleTime" BO_ 2365303550 1000;
BA_ "GenMsgSendType" BO_ 2365303294 0;
BA_ "GenMsgCycleTime" BO_ 2365303294 1000;
BA_ "GenMsgSendType" BO_ 2566629630 0;
BA_ "GenMsgCycleTime" BO_ 2566629630 1000;
BA_ "GenMsgSendType" BO_ 2566629118 0;
BA_ "GenMsgCycleTime" BO_ 2566629118 5000;
BA_ "GenMsgSendType" BO_ 2365302270 0;
BA_ "GenMsgCycleTime" BO_ 2365302270 1000;
BA_ "GenMsgSendType" BO_ 2365302014 0;
BA_ "GenMsgCycleTime" BO_ 2365302014 1000;
BA_ "GenMsgSendType" BO_ 2566628350 0;
BA_ "GenMsgCycleTime" BO_ 2566628350 1000;
BA_ "GenMsgSendType" BO_ 2566627838 0;
BA_ "GenMsgCycleTime" BO_ 2566627838 5000;
BA_ "GenMsgSendType" BO_ 2365300990 0;
BA_ "GenMsgCycleTime" BO_ 2365300990 1000;
BA_ "GenMsgSendType" BO_ 2365300734 0;
BA_ "GenMsgCycleTime" BO_ 2365300734 1000;
BA_ "GenMsgSendType" BO_ 2566627070 0;
BA_ "GenMsgCycleTime" BO_ 2566627070 1000;
BA_ "GenMsgSendType" BO_ 2566626558 0;
BA_ "GenMsgCycleTime" BO_ 2566626558 5000;
BA_ "GenMsgSendType" BO_ 2365299710 0;
BA_ "GenMsgCycleTime" BO_ 2365299710 1000;
BA_ "GenMsgSendType" BO_ 2365299454 0;
BA_ "GenMsgCycleTime" BO_ 2365299454 1000;
BA_ "GenMsgSendType" BO_ 2566625790 0;
BA_ "GenMsgCycleTime" BO_ 2566625790 1000;
BA_ "GenMsgSendType" BO_ 2566625022 0;
BA_ "GenMsgCycleTime" BO_ 2566625022 100;
BA_ "GenMsgSendType" BO_ 2365297662 0;
BA_ "GenMsgCycleTime" BO_ 2365297662 100;
BA_ "GenMsgSendType" BO_ 2365297406 0;
BA_ "GenMsgCycleTime" BO_ 2365297406 100;
BA_ "GenMsgSendType" BO_ 2365297150 0;
BA_ "GenMsgCycleTime" BO_ 2365297150 100;
BA_ "GenMsgSendType" BO_ 2365296894 0;
BA_ "GenMsgCycleTime" BO_ 2365296894 100;
BA_ "GenMsgSendType" BO_ 2566622462 0;
BA_ "GenMsgCycleTime" BO_ 2566622462 1000;
BA_ "GenMsgSendType" BO_ 2365295358 0;
BA_ "GenMsgCycleTime" BO_ 2365295358 100;
BA_ "GenMsgSendType" BO_ 2566621694 0;
BA_ "GenMsgCycleTime" BO_ 2566621694 500;
BA_ "GenMsgSendType" BO_ 2566621438 0;
BA_ "GenMsgCycleTime" BO_ 2566621438 1000;
BA_ "GenMsgDelayTime" BO_ 2566620670 100;
BA_ "GenMsgSendType" BO_ 2566620670 0;
BA_ "GenMsgCycleTime" BO_ 2566620670 1000;
BA_ "GenMsgDelayTime" BO_ 2364620286 10;
BA_ "GenMsgSendType" BO_ 2364620286 0;
BA_ "GenMsgCycleTime" BO_ 2364620286 50;
BA_ "GenMsgSendType" BO_ 2364620030 0;
BA_ "GenMsgCycleTime" BO_ 2364620030 100;
BA_ "GenMsgSendType" BO_ 2364619774 0;
BA_ "GenMsgCycleTime" BO_ 2364619774 100;
BA_ "GenMsgSendType" BO_ 2364619518 0;
BA_ "GenMsgCycleTime" BO_ 2364619518 100;
BA_ "GenMsgSendType" BO_ 2364619262 0;
BA_ "GenMsgCycleTime" BO_ 2364619262 100;
BA_ "GenMsgSendType" BO_ 2364619006 0;
BA_ "GenMsgCycleTime" BO_ 2364619006 100;
BA_ "GenMsgSendType" BO_ 2364618750 0;
BA_ "GenMsgCycleTime" BO_ 2364618750 100;
BA_ "GenMsgSendType" BO_ 2364618494 0;
BA_ "GenMsgCycleTime" BO_ 2364618494 100;
BA_ "GenMsgSendType" BO_ 2364618238 0;
BA_ "GenMsgCycleTime" BO_ 2364618238 100;
BA_ "GenMsgSendType" BO_ 2364617982 0;
BA_ "GenMsgCycleTime" BO_ 2364617982 100;
BA_ "GenMsgSendType" BO_ 2364617726 0;
BA_ "GenMsgCycleTime" BO_ 2364617726 100;
BA_ "GenMsgSendType" BO_ 2565944062 0;
BA_ "GenMsgCycleTime" BO_ 2565944062 100;
BA_ "GenMsgSendType" BO_ 2364617214 0;
BA_ "GenMsgCycleTime" BO_ 2364617214 100;
BA_ "GenMsgSendType" BO_ 2364616958 0;
BA_ "GenMsgCycleTime" BO_ 2364616958 100;
BA_ "GenMsgSendType" BO_ 2565943294 0;
BA_ "GenMsgCycleTime" BO_ 2565943294 100;
BA_ "GenMsgSendType" BO_ 2565943038 0;
BA_ "GenMsgCycleTime" BO_ 2565943038 100;
BA_ "GenMsgSendType" BO_ 2565942782 0;
BA_ "GenMsgCycleTime" BO_ 2565942782 100;
BA_ "GenMsgSendType" BO_ 2364615934 0;
BA_ "GenMsgCycleTime" BO_ 2364615934 100;
BA_ "GenMsgSendType" BO_ 2364615678 0;
BA_ "GenMsgCycleTime" BO_ 2364615678 100;
BA_ "GenMsgSendType" BO_ 2565942014 0;
BA_ "GenMsgCycleTime" BO_ 2565942014 100;
BA_ "GenMsgSendType" BO_ 2364615166 0;
BA_ "GenMsgCycleTime" BO_ 2364615166 100;
BA_ "GenMsgSendType" BO_ 2364614910 0;
BA_ "GenMsgCycleTime" BO_ 2364614910 100;
BA_ "GenMsgDelayTime" BO_ 2364614654 10;
BA_ "GenMsgSendType" BO_ 2364614654 0;
BA_ "GenMsgCycleTime" BO_ 2364614654 1000;
BA_ "GenMsgSendType" BO_ 2364614398 0;
BA_ "GenMsgCycleTime" BO_ 2364614398 100;
BA_ "GenMsgSendType" BO_ 2364614142 0;
BA_ "GenMsgCycleTime" BO_ 2364614142 100;
BA_ "GenMsgSendType" BO_ 2364613886 0;
BA_ "GenMsgCycleTime" BO_ 2364613886 100;
BA_ "FsJ1939UseCrcAndCounter" BO_ 2364613630 "Aa";
BA_ "GenMsgSendType" BO_ 2364613630 0;
BA_ "GenMsgCycleTime" BO_ 2364613630 100;
BA_ "FsJ1939UseCrcAndCounter" BO_ 2364613374 "Ae";
BA_ "GenMsgSendType" BO_ 2364613374 0;
BA_ "GenMsgCycleTime" BO_ 2364613374 100;
BA_ "GenMsgSendType" BO_ 2364613118 0;
BA_ "GenMsgCycleTime" BO_ 2364613118 100;
BA_ "GenMsgSendType" BO_ 2364612862 0;
BA_ "GenMsgCycleTime" BO_ 2364612862 100;
BA_ "GenMsgSendType" BO_ 2364612606 0;
BA_ "GenMsgCycleTime" BO_ 2364612606 100;
BA_ "FsJ1939UseCrcAndCounter" BO_ 2364612350 "Aa";
BA_ "GenMsgSendType" BO_ 2364612350 0;
BA_ "GenMsgCycleTime" BO_ 2364612350 100;
BA_ "FsJ1939UseCrcAndCounter" BO_ 2364612094 "Ae";
BA_ "GenMsgSendType" BO_ 2364612094 0;
BA_ "GenMsgCycleTime" BO_ 2364612094 100;
BA_ "GenMsgSendType" BO_ 2364611838 0;
BA_ "GenMsgCycleTime" BO_ 2364611838 100;
BA_ "GenMsgSendType" BO_ 2364611582 0;
BA_ "GenMsgCycleTime" BO_ 2364611582 100;
BA_ "GenMsgSendType" BO_ 2364611326 0;
BA_ "GenMsgCycleTime" BO_ 2364611326 100;
BA_ "FsJ1939UseCrcAndCounter" BO_ 2364611070 "Aa";
BA_ "GenMsgSendType" BO_ 2364611070 0;
BA_ "GenMsgCycleTime" BO_ 2364611070 100;
BA_ "FsJ1939UseCrcAndCounter" BO_ 2364610814 "Ae";
BA_ "GenMsgSendType" BO_ 2364610814 0;
BA_ "GenMsgCycleTime" BO_ 2364610814 100;
BA_ "GenMsgSendType" BO_ 2364610558 0;
BA_ "GenMsgCycleTime" BO_ 2364610558 100;
BA_ "GenMsgSendType" BO_ 2565918206 0;
BA_ "GenMsgCycleTime" BO_ 2565918206 100;
BA_ "GenMsgSendType" BO_ 2364591358 0;
BA_ "GenMsgCycleTime" BO_ 2364591358 100;
BA_ "GenMsgSendType" BO_ 2364591102 0;
BA_ "GenMsgCycleTime" BO_ 2364591102 100;
BA_ "SigType" SG_ 2566630654 TotalDCInputEnergy 1;
BA_ "SPN" SG_ 2566630654 TotalDCInputEnergy 9320;
BA_ "SigType" SG_ 2566630654 TotalDCInputCharge 1;
BA_ "SPN" SG_ 2566630654 TotalDCInputCharge 9319;
BA_ "SigType" SG_ 2566630398 ACSideDefaultFreqCmdSetting 1;
BA_ "SPN" SG_ 2566630398 ACSideDefaultFreqCmdSetting 9551;
BA_ "SigType" SG_ 2566630398 DCSideCurMinLmtSetting 1;
BA_ "SPN" SG_ 2566630398 DCSideCurMinLmtSetting 9550;
BA_ "SigType" SG_ 2566630398 DCSideVMaxLmtSetting 1;
BA_ "SPN" SG_ 2566630398 DCSideVMaxLmtSetting 9549;
BA_ "SigType" SG_ 2566630398 ACSideRMSCurMaxLmtSetting 1;
BA_ "SPN" SG_ 2566630398 ACSideRMSCurMaxLmtSetting 9318;
BA_ "SigType" SG_ 2566630398 ACSideRMSVMaxLmtSetting 1;
BA_ "SPN" SG_ 2566630398 ACSideRMSVMaxLmtSetting 9317;
BA_ "SigType" SG_ 2566630398 DCSideCurMaxLmtSetting 1;
BA_ "SPN" SG_ 2566630398 DCSideCurMaxLmtSetting 9316;
BA_ "SigType" SG_ 2566630398 DCSideVMinLmtSetting 1;
BA_ "SPN" SG_ 2566630398 DCSideVMinLmtSetting 9315;
BA_ "SigType" SG_ 2365303550 DefaultFreqReq 1;
BA_ "SPN" SG_ 2365303550 DefaultFreqReq 9526;
BA_ "SigType" SG_ 2365303550 RMSCurMaxLmtReq 1;
BA_ "SPN" SG_ 2365303550 RMSCurMaxLmtReq 9314;
BA_ "SigType" SG_ 2365303550 RMSVMaxLmtReq 1;
BA_ "SPN" SG_ 2365303550 RMSVMaxLmtReq 9313;
BA_ "SigType" SG_ 2365303294 CurMinLmtReq 1;
BA_ "SPN" SG_ 2365303294 CurMinLmtReq 9548;
BA_ "SigType" SG_ 2365303294 VMaxLmtReq 1;
BA_ "SPN" SG_ 2365303294 VMaxLmtReq 9547;
BA_ "SigType" SG_ 2365303294 CurMaxLmtReq 1;
BA_ "SPN" SG_ 2365303294 CurMaxLmtReq 9312;
BA_ "SigType" SG_ 2365303294 VMinLmtReq 1;
BA_ "SPN" SG_ 2365303294 VMinLmtReq 9311;
BA_ "SigType" SG_ 2566629630 CoolantOutTemp 1;
BA_ "SPN" SG_ 2566629630 CoolantOutTemp 9295;
BA_ "SigType" SG_ 2566629630 CoolantInTemp 1;
BA_ "SPN" SG_ 2566629630 CoolantInTemp 9294;
BA_ "SigType" SG_ 2566629630 PwrETemp 1;
BA_ "SPN" SG_ 2566629630 PwrETemp 9293;
BA_ "SigType" SG_ 2566629630 InverterEFilterTemp 1;
BA_ "SPN" SG_ 2566629630 InverterEFilterTemp 9292;
BA_ "SigType" SG_ 2566629630 CtrlTemp 1;
BA_ "SPN" SG_ 2566629630 CtrlTemp 9291;
BA_ "SigType" SG_ 2566629374 TotalDCInputEnergy 1;
BA_ "SPN" SG_ 2566629374 TotalDCInputEnergy 9290;
BA_ "SigType" SG_ 2566629374 TotalDCInputCharge 1;
BA_ "SPN" SG_ 2566629374 TotalDCInputCharge 9289;
BA_ "SigType" SG_ 2566629118 ACSideDefaultFreqCmdSetting 1;
BA_ "SPN" SG_ 2566629118 ACSideDefaultFreqCmdSetting 9545;
BA_ "SigType" SG_ 2566629118 DCSideCurMinLmtSetting 1;
BA_ "SPN" SG_ 2566629118 DCSideCurMinLmtSetting 9544;
BA_ "SigType" SG_ 2566629118 DCSideVMaxLmtSetting 1;
BA_ "SPN" SG_ 2566629118 DCSideVMaxLmtSetting 9543;
BA_ "SigType" SG_ 2566629118 ACSideRMSCurMaxLmtSetting 1;
BA_ "SPN" SG_ 2566629118 ACSideRMSCurMaxLmtSetting 9288;
BA_ "SigType" SG_ 2566629118 ACSideRMSVMaxLmtSetting 1;
BA_ "SPN" SG_ 2566629118 ACSideRMSVMaxLmtSetting 9287;
BA_ "SigType" SG_ 2566629118 DCSideCurMaxLmtSetting 1;
BA_ "SPN" SG_ 2566629118 DCSideCurMaxLmtSetting 9286;
BA_ "SigType" SG_ 2566629118 DCSideVMinLmtSetting 1;
BA_ "SPN" SG_ 2566629118 DCSideVMinLmtSetting 9285;
BA_ "SigType" SG_ 2365302270 DefaultFreqReq 1;
BA_ "SPN" SG_ 2365302270 DefaultFreqReq 9525;
BA_ "SigType" SG_ 2365302270 RMSCurMaxLmtReq 1;
BA_ "SPN" SG_ 2365302270 RMSCurMaxLmtReq 9284;
BA_ "SigType" SG_ 2365302270 RMSVMaxLmtReq 1;
BA_ "SPN" SG_ 2365302270 RMSVMaxLmtReq 9283;
BA_ "SigType" SG_ 2365302014 CurMinLmtReq 1;
BA_ "SPN" SG_ 2365302014 CurMinLmtReq 9542;
BA_ "SigType" SG_ 2365302014 VMaxLmtReq 1;
BA_ "SPN" SG_ 2365302014 VMaxLmtReq 9541;
BA_ "SigType" SG_ 2365302014 CurMaxLmtReq 1;
BA_ "SPN" SG_ 2365302014 CurMaxLmtReq 9282;
BA_ "SigType" SG_ 2365302014 VMinLmtReq 1;
BA_ "SPN" SG_ 2365302014 VMinLmtReq 9281;
BA_ "SigType" SG_ 2566628350 CoolantOutTemp 1;
BA_ "SPN" SG_ 2566628350 CoolantOutTemp 9265;
BA_ "SigType" SG_ 2566628350 CoolantInTemp 1;
BA_ "SPN" SG_ 2566628350 CoolantInTemp 9264;
BA_ "SigType" SG_ 2566628350 PwrETemp 1;
BA_ "SPN" SG_ 2566628350 PwrETemp 9263;
BA_ "SigType" SG_ 2566628350 InverterEFilterTemp 1;
BA_ "SPN" SG_ 2566628350 InverterEFilterTemp 9262;
BA_ "SigType" SG_ 2566628350 CtrlTemp 1;
BA_ "SPN" SG_ 2566628350 CtrlTemp 9261;
BA_ "SigType" SG_ 2566628094 TotalDCInputEnergy 1;
BA_ "SPN" SG_ 2566628094 TotalDCInputEnergy 9260;
BA_ "SigType" SG_ 2566628094 TotalDCInputCharge 1;
BA_ "SPN" SG_ 2566628094 TotalDCInputCharge 9259;
BA_ "SigType" SG_ 2566627838 ACSideDefaultFreqCmdSetting 1;
BA_ "SPN" SG_ 2566627838 ACSideDefaultFreqCmdSetting 9539;
BA_ "SigType" SG_ 2566627838 DCSideCurMinLmtSetting 1;
BA_ "SPN" SG_ 2566627838 DCSideCurMinLmtSetting 9538;
BA_ "SigType" SG_ 2566627838 DCSideVMaxLmtSetting 1;
BA_ "SPN" SG_ 2566627838 DCSideVMaxLmtSetting 9537;
BA_ "SigType" SG_ 2566627838 ACSideRMSCurMaxLmtSetting 1;
BA_ "SPN" SG_ 2566627838 ACSideRMSCurMaxLmtSetting 9258;
BA_ "SigType" SG_ 2566627838 ACSideRMSVMaxLmtSetting 1;
BA_ "SPN" SG_ 2566627838 ACSideRMSVMaxLmtSetting 9257;
BA_ "SigType" SG_ 2566627838 DCSideCurMaxLmtSetting 1;
BA_ "SPN" SG_ 2566627838 DCSideCurMaxLmtSetting 9256;
BA_ "SigType" SG_ 2566627838 DCSideVMinLmtSetting 1;
BA_ "SPN" SG_ 2566627838 DCSideVMinLmtSetting 9255;
BA_ "SigType" SG_ 2365300990 DefaultFreqReq 1;
BA_ "SPN" SG_ 2365300990 DefaultFreqReq 9524;
BA_ "SigType" SG_ 2365300990 RMSCurMaxLmtReq 1;
BA_ "SPN" SG_ 2365300990 RMSCurMaxLmtReq 9254;
BA_ "SigType" SG_ 2365300990 RMSVMaxLmtReq 1;
BA_ "SPN" SG_ 2365300990 RMSVMaxLmtReq 9253;
BA_ "SigType" SG_ 2365300734 CurMinLmtReq 1;
BA_ "SPN" SG_ 2365300734 CurMinLmtReq 9536;
BA_ "SigType" SG_ 2365300734 VMaxLmtReq 1;
BA_ "SPN" SG_ 2365300734 VMaxLmtReq 9535;
BA_ "SigType" SG_ 2365300734 CurMaxLmtReq 1;
BA_ "SPN" SG_ 2365300734 CurMaxLmtReq 9252;
BA_ "SigType" SG_ 2365300734 VMinLmtReq 1;
BA_ "SPN" SG_ 2365300734 VMinLmtReq 9251;
BA_ "SigType" SG_ 2566627070 CoolantOutTemp 1;
BA_ "SPN" SG_ 2566627070 CoolantOutTemp 9235;
BA_ "SigType" SG_ 2566627070 CoolantInTemp 1;
BA_ "SPN" SG_ 2566627070 CoolantInTemp 9234;
BA_ "SigType" SG_ 2566627070 PwrETemp 1;
BA_ "SPN" SG_ 2566627070 PwrETemp 9233;
BA_ "SigType" SG_ 2566627070 InverterEFilterTemp 1;
BA_ "SPN" SG_ 2566627070 InverterEFilterTemp 9232;
BA_ "SigType" SG_ 2566627070 CtrlTemp 1;
BA_ "SPN" SG_ 2566627070 CtrlTemp 9231;
BA_ "SigType" SG_ 2566626814 TotalDCInputEnergy 1;
BA_ "SPN" SG_ 2566626814 TotalDCInputEnergy 9230;
BA_ "SigType" SG_ 2566626814 TotalDCInputCharge 1;
BA_ "SPN" SG_ 2566626814 TotalDCInputCharge 9229;
BA_ "SigType" SG_ 2566626558 ACSideDefaultFreqCmdSetting 1;
BA_ "SPN" SG_ 2566626558 ACSideDefaultFreqCmdSetting 9533;
BA_ "SigType" SG_ 2566626558 DCSideCurMinLmtSetting 1;
BA_ "SPN" SG_ 2566626558 DCSideCurMinLmtSetting 9532;
BA_ "SigType" SG_ 2566626558 DCSideVMaxLmtSetting 1;
BA_ "SPN" SG_ 2566626558 DCSideVMaxLmtSetting 9531;
BA_ "SigType" SG_ 2566626558 ACSideRMSCurMaxLmtSetting 1;
BA_ "SPN" SG_ 2566626558 ACSideRMSCurMaxLmtSetting 9228;
BA_ "SigType" SG_ 2566626558 ACSideRMSVMaxLmtSetting 1;
BA_ "SPN" SG_ 2566626558 ACSideRMSVMaxLmtSetting 9227;
BA_ "SigType" SG_ 2566626558 DCSideCurMaxLmtSetting 1;
BA_ "SPN" SG_ 2566626558 DCSideCurMaxLmtSetting 9226;
BA_ "SigType" SG_ 2566626558 DCSideVMinLmtSetting 1;
BA_ "SPN" SG_ 2566626558 DCSideVMinLmtSetting 9225;
BA_ "SigType" SG_ 2365299710 DefaultFreqReq 1;
BA_ "SPN" SG_ 2365299710 DefaultFreqReq 9523;
BA_ "SigType" SG_ 2365299710 RMSCurMaxLmtReq 1;
BA_ "SPN" SG_ 2365299710 RMSCurMaxLmtReq 9224;
BA_ "SigType" SG_ 2365299710 RMSVMaxLmtReq 1;
BA_ "SPN" SG_ 2365299710 RMSVMaxLmtReq 9223;
BA_ "SigType" SG_ 2365299454 CurMinLmtReq 1;
BA_ "SPN" SG_ 2365299454 CurMinLmtReq 9530;
BA_ "SigType" SG_ 2365299454 VMaxLmtReq 1;
BA_ "SPN" SG_ 2365299454 VMaxLmtReq 9529;
BA_ "SigType" SG_ 2365299454 CurMaxLmtReq 1;
BA_ "SPN" SG_ 2365299454 CurMaxLmtReq 9222;
BA_ "SigType" SG_ 2365299454 VMinLmtReq 1;
BA_ "SPN" SG_ 2365299454 VMinLmtReq 9221;
BA_ "SigType" SG_ 2566625790 CoolantOutTemp 1;
BA_ "SPN" SG_ 2566625790 CoolantOutTemp 9208;
BA_ "SigType" SG_ 2566625790 CoolantInTemp 1;
BA_ "SPN" SG_ 2566625790 CoolantInTemp 9207;
BA_ "SigType" SG_ 2566625790 PwrETemp 1;
BA_ "SPN" SG_ 2566625790 PwrETemp 9206;
BA_ "SigType" SG_ 2566625790 InverterEFilterTemp 1;
BA_ "SPN" SG_ 2566625790 InverterEFilterTemp 9205;
BA_ "SigType" SG_ 2566625790 CtrlTemp 1;
BA_ "SPN" SG_ 2566625790 CtrlTemp 9204;
BA_ "SigType" SG_ 2633734398 EngActualExh2O2 1;
BA_ "SPN" SG_ 2633734398 EngActualExh2O2 9367;
BA_ "SigType" SG_ 2566625278 SLIBatPack1Bat4CapacitySetting 1;
BA_ "SPN" SG_ 2566625278 SLIBatPack1Bat4CapacitySetting 9371;
BA_ "SigType" SG_ 2566625278 SLIBatPack1Bat3CapacitySetting 1;
BA_ "SPN" SG_ 2566625278 SLIBatPack1Bat3CapacitySetting 9370;
BA_ "SigType" SG_ 2566625278 SLIBatPack1Bat2CapacitySetting 1;
BA_ "SPN" SG_ 2566625278 SLIBatPack1Bat2CapacitySetting 9369;
BA_ "SigType" SG_ 2566625278 SLIBatPack1Bat1CapacitySetting 1;
BA_ "SPN" SG_ 2566625278 SLIBatPack1Bat1CapacitySetting 9368;
BA_ "SigType" SG_ 2566625022 ExhManifoldBank1Press2 1;
BA_ "SPN" SG_ 2566625022 ExhManifoldBank1Press2 11798;
BA_ "SigType" SG_ 2566625022 InstantaneousEstEngPwrRateLmt 1;
BA_ "SPN" SG_ 2566625022 InstantaneousEstEngPwrRateLmt 9375;
BA_ "SigType" SG_ 2566624766 IdleMnmgtActiveTotalTime 1;
BA_ "SPN" SG_ 2566624766 IdleMnmgtActiveTotalTime 9377;
BA_ "SigType" SG_ 2566624510 TotalNumOfCrankAttempts 1;
BA_ "SPN" SG_ 2566624510 TotalNumOfCrankAttempts 22623;
BA_ "SigType" SG_ 2566624510 EGR1CoolerInPress 1;
BA_ "SPN" SG_ 2566624510 EGR1CoolerInPress 9379;
BA_ "SigType" SG_ 2365297662 OneCtrlInputSLIV 1;
BA_ "SPN" SG_ 2365297662 OneCtrlInputSLIV 9559;
BA_ "SigType" SG_ 2365297662 OneCtrlInputIgntV 1;
BA_ "SPN" SG_ 2365297662 OneCtrlInputIgntV 9558;
BA_ "SigType" SG_ 2365297406 TwoCtrlInputSLIV 1;
BA_ "SPN" SG_ 2365297406 TwoCtrlInputSLIV 9561;
BA_ "SigType" SG_ 2365297406 TwoCtrlInputIgntV 1;
BA_ "SPN" SG_ 2365297406 TwoCtrlInputIgntV 9560;
BA_ "SigType" SG_ 2365297150 ThreeCtrlInputSLIV 1;
BA_ "SPN" SG_ 2365297150 ThreeCtrlInputSLIV 9563;
BA_ "SigType" SG_ 2365297150 ThreeCtrlInputIgntV 1;
BA_ "SPN" SG_ 2365297150 ThreeCtrlInputIgntV 9562;
BA_ "SigType" SG_ 2365296894 FourCtrlInputSLIV 1;
BA_ "SPN" SG_ 2365296894 FourCtrlInputSLIV 9565;
BA_ "SigType" SG_ 2365296894 FourCtrlInputIgntV 1;
BA_ "SPN" SG_ 2365296894 FourCtrlInputIgntV 9564;
BA_ "SigType" SG_ 2566623230 TripEstFuelSaved 1;
BA_ "SPN" SG_ 2566623230 TripEstFuelSaved 9571;
BA_ "SigType" SG_ 2566623230 TotalEstFuelSaved 1;
BA_ "SPN" SG_ 2566623230 TotalEstFuelSaved 9570;
BA_ "SigType" SG_ 2566622974 TripFuelUsed 1;
BA_ "SPN" SG_ 2566622974 TripFuelUsed 9573;
BA_ "SigType" SG_ 2566622974 TotalFuelUsed 1;
BA_ "SPN" SG_ 2566622974 TotalFuelUsed 9572;
BA_ "SigType" SG_ 2566622718 TripHoursActive 1;
BA_ "SPN" SG_ 2566622718 TripHoursActive 9575;
BA_ "SigType" SG_ 2566622718 TotalHoursActive 1;
BA_ "SPN" SG_ 2566622718 TotalHoursActive 9574;
BA_ "SigType" SG_ 2566622462 Percent 1;
BA_ "SPN" SG_ 2566622462 Percent 9577;
BA_ "SigType" SG_ 2566622462 RateAbsolute 1;
BA_ "SPN" SG_ 2566622462 RateAbsolute 9576;
BA_ "SigType" SG_ 2566622206 TripHoursInactive 1;
BA_ "SPN" SG_ 2566622206 TripHoursInactive 9579;
BA_ "SigType" SG_ 2566622206 TotalHoursInactive 1;
BA_ "SPN" SG_ 2566622206 TotalHoursInactive 9578;
BA_ "SigType" SG_ 2365295358 PwrModuleETemp 1;
BA_ "SPN" SG_ 2365295358 PwrModuleETemp 22822;
BA_ "SigType" SG_ 2365295358 TotalStoredESLvl 1;
BA_ "SPN" SG_ 2365295358 TotalStoredESLvl 22821;
BA_ "SigType" SG_ 2365295358 ActualChargeRate 1;
BA_ "SPN" SG_ 2365295358 ActualChargeRate 13071;
BA_ "SigType" SG_ 2365295358 LvlNegToChassisGroundV 1;
BA_ "SPN" SG_ 2365295358 LvlNegToChassisGroundV 9581;
BA_ "SigType" SG_ 2365295358 BusVNegToChassisGroundV 1;
BA_ "SPN" SG_ 2365295358 BusVNegToChassisGroundV 9580;
BA_ "SigType" SG_ 2566621694 OilLvl2St 4;
BA_ "SPN" SG_ 2566621694 OilLvl2St 22723;
BA_ "SigType" SG_ 2566621694 OilLvl1St 4;
BA_ "SPN" SG_ 2566621694 OilLvl1St 22722;
BA_ "SigType" SG_ 2566621694 CrankcaseBreatherOilSepOutPress 1;
BA_ "SPN" SG_ 2566621694 CrankcaseBreatherOilSepOutPress 21146;
BA_ "SigType" SG_ 2566621694 ChargeAC2DiffPress 1;
BA_ "SPN" SG_ 2566621694 ChargeAC2DiffPress 20170;
BA_ "SigType" SG_ 2566621694 ChargeAC1DiffPress 1;
BA_ "SPN" SG_ 2566621694 ChargeAC1DiffPress 5926;
BA_ "SigType" SG_ 2566621694 ChargeAC2OutPress 1;
BA_ "SPN" SG_ 2566621694 ChargeAC2OutPress 20169;
BA_ "SigType" SG_ 2566621694 OilPress2 1;
BA_ "SPN" SG_ 2566621694 OilPress2 9653;
BA_ "SigType" SG_ 2566621438 HeavySeaModeEnable 5;
BA_ "SPN" SG_ 2566621438 HeavySeaModeEnable 12303;
BA_ "SigType" SG_ 2566621438 SlowVesselModeLampStatus 5;
BA_ "SPN" SG_ 2566621438 SlowVesselModeLampStatus 9690;
BA_ "SigType" SG_ 2566621438 GearLockoutLampStatus 5;
BA_ "SPN" SG_ 2566621438 GearLockoutLampStatus 9675;
BA_ "SigType" SG_ 2566621438 EngThrotLeverSynchLampStatus 5;
BA_ "SPN" SG_ 2566621438 EngThrotLeverSynchLampStatus 9674;
BA_ "SigType" SG_ 2566621438 TrollingModeLampStatus 5;
BA_ "SPN" SG_ 2566621438 TrollingModeLampStatus 9673;
BA_ "SigType" SG_ 2566621438 OpStationActiveLampStatus 5;
BA_ "SPN" SG_ 2566621438 OpStationActiveLampStatus 9672;
BA_ "SigType" SG_ 2566621438 SlowVesselModeButtonStatus 5;
BA_ "SPN" SG_ 2566621438 SlowVesselModeButtonStatus 9671;
BA_ "SigType" SG_ 2566621438 GearLockoutButtonStatus 5;
BA_ "SPN" SG_ 2566621438 GearLockoutButtonStatus 9670;
BA_ "SigType" SG_ 2566621438 EngThrotLeverSynchButtonStatus 5;
BA_ "SPN" SG_ 2566621438 EngThrotLeverSynchButtonStatus 9669;
BA_ "SigType" SG_ 2566621438 TrollingModeButtonStatus 5;
BA_ "SPN" SG_ 2566621438 TrollingModeButtonStatus 9668;
BA_ "SigType" SG_ 2566621438 OpStationActiveButtonStatus 5;
BA_ "SPN" SG_ 2566621438 OpStationActiveButtonStatus 9667;
BA_ "SigType" SG_ 2566621438 StationGearPosMatch 5;
BA_ "SPN" SG_ 2566621438 StationGearPosMatch 9666;
BA_ "SigType" SG_ 2566621438 StationThrotPosMatch 5;
BA_ "SPN" SG_ 2566621438 StationThrotPosMatch 9665;
BA_ "SigType" SG_ 2566620670 PendingEventTimeRemaining 1;
BA_ "SPN" SG_ 2566620670 PendingEventTimeRemaining 10149;
BA_ "SPN" SG_ 2566620670 ShutdownReason 9679;
BA_ "SPN" SG_ 2566620670 RestartReason 9678;
BA_ "SPN" SG_ 2566620670 Status 9677;
BA_ "SPN" SG_ 2364620286 HandsOffDetectionAvailability 12854;
BA_ "SPN" SG_ 2364620286 HandsOffDetectionStatus 12855;
BA_ "SPN" SG_ 2364620286 LaneCenteringSysStatus 9759;
BA_ "SigType" SG_ 2364620286 LaneCenteringIndEnableSt 5;
BA_ "SPN" SG_ 2364620286 LaneCenteringIndEnableSt 9758;
BA_ "SPN" SG_ 2364620286 DriverPref 9757;
BA_ "SPN" SG_ 2364620286 LaneKeepingAssistSysSt 9756;
BA_ "SigType" SG_ 2364620286 LaneKeepingAssistIndEnableStatus 5;
BA_ "SPN" SG_ 2364620286 LaneKeepingAssistIndEnableStatus 9755;
BA_ "SPN" SG_ 2364620286 LaneKeepingAssistStatusLeftSide 9754;
BA_ "SPN" SG_ 2364620286 LaneKeepingAssistStatusRightSide 9753;
BA_ "SigType" SG_ 2364620030 Two0StartAct 1;
BA_ "SPN" SG_ 2364620030 Two0StartAct 9630;
BA_ "SigType" SG_ 2364620030 One9StartAct 1;
BA_ "SPN" SG_ 2364620030 One9StartAct 9629;
BA_ "SigType" SG_ 2364620030 One8StartAct 1;
BA_ "SPN" SG_ 2364620030 One8StartAct 9628;
BA_ "SigType" SG_ 2364620030 One7StartAct 1;
BA_ "SPN" SG_ 2364620030 One7StartAct 9627;
BA_ "SigType" SG_ 2364619774 One6StartAct 1;
BA_ "SPN" SG_ 2364619774 One6StartAct 9626;
BA_ "SigType" SG_ 2364619774 One5StartAct 1;
BA_ "SPN" SG_ 2364619774 One5StartAct 9625;
BA_ "SigType" SG_ 2364619774 One4StartAct 1;
BA_ "SPN" SG_ 2364619774 One4StartAct 9624;
BA_ "SigType" SG_ 2364619774 One3StartAct 1;
BA_ "SPN" SG_ 2364619774 One3StartAct 9623;
BA_ "SigType" SG_ 2364619518 One2StartAct 1;
BA_ "SPN" SG_ 2364619518 One2StartAct 9622;
BA_ "SigType" SG_ 2364619518 One1StartAct 1;
BA_ "SPN" SG_ 2364619518 One1StartAct 9621;
BA_ "SigType" SG_ 2364619518 One0StartAct 1;
BA_ "SPN" SG_ 2364619518 One0StartAct 9620;
BA_ "SigType" SG_ 2364619518 NineStartAct 1;
BA_ "SPN" SG_ 2364619518 NineStartAct 9619;
BA_ "SigType" SG_ 2364619262 EightStartAct 1;
BA_ "SPN" SG_ 2364619262 EightStartAct 9618;
BA_ "SigType" SG_ 2364619262 SevenStartAct 1;
BA_ "SPN" SG_ 2364619262 SevenStartAct 9617;
BA_ "SigType" SG_ 2364619262 SixStartAct 1;
BA_ "SPN" SG_ 2364619262 SixStartAct 9616;
BA_ "SigType" SG_ 2364619262 FiveStartAct 1;
BA_ "SPN" SG_ 2364619262 FiveStartAct 9615;
BA_ "SigType" SG_ 2364619006 FourStartAct 1;
BA_ "SPN" SG_ 2364619006 FourStartAct 9614;
BA_ "SigType" SG_ 2364619006 ThreeStartAct 1;
BA_ "SPN" SG_ 2364619006 ThreeStartAct 9613;
BA_ "SigType" SG_ 2364619006 TwoStartAct 1;
BA_ "SPN" SG_ 2364619006 TwoStartAct 9612;
BA_ "SigType" SG_ 2364619006 OneStartAct 1;
BA_ "SPN" SG_ 2364619006 OneStartAct 9611;
BA_ "SigType" SG_ 2364618750 Two0Dur 1;
BA_ "SPN" SG_ 2364618750 Two0Dur 9610;
BA_ "SigType" SG_ 2364618750 One9Dur 1;
BA_ "SPN" SG_ 2364618750 One9Dur 9609;
BA_ "SigType" SG_ 2364618750 One8Dur 1;
BA_ "SPN" SG_ 2364618750 One8Dur 9608;
BA_ "SigType" SG_ 2364618750 One7Dur 1;
BA_ "SPN" SG_ 2364618750 One7Dur 9607;
BA_ "SigType" SG_ 2364618494 One6Dur 1;
BA_ "SPN" SG_ 2364618494 One6Dur 9606;
BA_ "SigType" SG_ 2364618494 One5Dur 1;
BA_ "SPN" SG_ 2364618494 One5Dur 9605;
BA_ "SigType" SG_ 2364618494 One4Dur 1;
BA_ "SPN" SG_ 2364618494 One4Dur 9604;
BA_ "SigType" SG_ 2364618494 One3Dur 1;
BA_ "SPN" SG_ 2364618494 One3Dur 9603;
BA_ "SigType" SG_ 2364618238 One2Dur 1;
BA_ "SPN" SG_ 2364618238 One2Dur 9602;
BA_ "SigType" SG_ 2364618238 One1Dur 1;
BA_ "SPN" SG_ 2364618238 One1Dur 9601;
BA_ "SigType" SG_ 2364618238 One0Dur 1;
BA_ "SPN" SG_ 2364618238 One0Dur 9600;
BA_ "SigType" SG_ 2364618238 NineDur 1;
BA_ "SPN" SG_ 2364618238 NineDur 9599;
BA_ "SigType" SG_ 2364617982 EightDur 1;
BA_ "SPN" SG_ 2364617982 EightDur 9598;
BA_ "SigType" SG_ 2364617982 SevenDur 1;
BA_ "SPN" SG_ 2364617982 SevenDur 9597;
BA_ "SigType" SG_ 2364617982 SixDur 1;
BA_ "SPN" SG_ 2364617982 SixDur 9596;
BA_ "SigType" SG_ 2364617982 FiveDur 1;
BA_ "SPN" SG_ 2364617982 FiveDur 9595;
BA_ "SigType" SG_ 2364617726 FourDur 1;
BA_ "SPN" SG_ 2364617726 FourDur 9594;
BA_ "SigType" SG_ 2364617726 ThreeDur 1;
BA_ "SPN" SG_ 2364617726 ThreeDur 9593;
BA_ "SigType" SG_ 2364617726 TwoDur 1;
BA_ "SPN" SG_ 2364617726 TwoDur 9592;
BA_ "SigType" SG_ 2364617726 OneDur 1;
BA_ "SPN" SG_ 2364617726 OneDur 9591;
BA_ "SigType" SG_ 2565944062 PLedDueToUndefinedReason 5;
BA_ "SPN" SG_ 2565944062 PLedDueToUndefinedReason 9356;
BA_ "SigType" SG_ 2565944062 PLedDueToRateOfChangeLmt 5;
BA_ "SPN" SG_ 2565944062 PLedDueToRateOfChangeLmt 9355;
BA_ "SigType" SG_ 2565944062 PLedDueToPwrETemp 5;
BA_ "SPN" SG_ 2565944062 PLedDueToPwrETemp 9354;
BA_ "SigType" SG_ 2565944062 PLedDueToEFilterTemp 5;
BA_ "SPN" SG_ 2565944062 PLedDueToEFilterTemp 9353;
BA_ "SigType" SG_ 2565944062 PLedDueToCtrlTemp 5;
BA_ "SPN" SG_ 2565944062 PLedDueToCtrlTemp 9352;
BA_ "SigType" SG_ 2565944062 FreqCmdExceedsMax 5;
BA_ "SPN" SG_ 2565944062 FreqCmdExceedsMax 9351;
BA_ "SigType" SG_ 2565944062 FreqCmdBelowMin 5;
BA_ "SPN" SG_ 2565944062 FreqCmdBelowMin 9350;
BA_ "SigType" SG_ 2565944062 PLedDueToDCSideVMin 5;
BA_ "SPN" SG_ 2565944062 PLedDueToDCSideVMin 9349;
BA_ "SigType" SG_ 2565944062 PLedDueToACSideRMSCur 5;
BA_ "SPN" SG_ 2565944062 PLedDueToACSideRMSCur 9348;
BA_ "SigType" SG_ 2565944062 PLedDueToDCSideCur 5;
BA_ "SPN" SG_ 2565944062 PLedDueToDCSideCur 9347;
BA_ "SigType" SG_ 2364617214 SLIV 1;
BA_ "SPN" SG_ 2364617214 SLIV 9346;
BA_ "SigType" SG_ 2364617214 IgntV 1;
BA_ "SPN" SG_ 2364617214 IgntV 9345;
BA_ "SigType" SG_ 2364616958 DCSideNegToChassisGroundV 1;
BA_ "SPN" SG_ 2364616958 DCSideNegToChassisGroundV 9586;
BA_ "SigType" SG_ 2364616958 DCSideCur 1;
BA_ "SPN" SG_ 2364616958 DCSideCur 9344;
BA_ "SigType" SG_ 2364616958 DCSideV 1;
BA_ "SPN" SG_ 2364616958 DCSideV 9343;
BA_ "SigType" SG_ 2364616958 DCSidePwr 1;
BA_ "SPN" SG_ 2364616958 DCSidePwr 9342;
BA_ "SigType" SG_ 2565943294 HVILStatus 5;
BA_ "SPN" SG_ 2565943294 HVILStatus 9336;
BA_ "SigType" SG_ 2565943294 LoadshedReq 5;
BA_ "SPN" SG_ 2565943294 LoadshedReq 9335;
BA_ "SPN" SG_ 2565943294 OperationalStatus 9334;
BA_ "SigType" SG_ 2565943294 ACSideRMSCur 1;
BA_ "SPN" SG_ 2565943294 ACSideRMSCur 9333;
BA_ "SigType" SG_ 2565943294 ACSidePwr 1;
BA_ "SPN" SG_ 2565943294 ACSidePwr 9332;
BA_ "SigType" SG_ 2565943294 ACSideRMSV 1;
BA_ "SPN" SG_ 2565943294 ACSideRMSV 9331;
BA_ "SigType" SG_ 2565943294 Freq 1;
BA_ "SPN" SG_ 2565943294 Freq 9330;
BA_ "SigType" SG_ 2565943038 ACSideMotorStartingRMSVReq 1;
BA_ "SPN" SG_ 2565943038 ACSideMotorStartingRMSVReq 9552;
BA_ "SigType" SG_ 2565943038 OperationalCmd 5;
BA_ "SPN" SG_ 2565943038 OperationalCmd 9329;
BA_ "SPN" SG_ 2565943038 Device2Status 9328;
BA_ "SPN" SG_ 2565943038 Device1Status 9327;
BA_ "SigType" SG_ 2565943038 FreqCmd 1;
BA_ "SPN" SG_ 2565943038 FreqCmd 9326;
BA_ "SigType" SG_ 2565943038 DeviceFreqRateOfChangeLmt 1;
BA_ "SPN" SG_ 2565943038 DeviceFreqRateOfChangeLmt 9325;
BA_ "SigType" SG_ 2565943038 DeviceRatedRMSV 1;
BA_ "SPN" SG_ 2565943038 DeviceRatedRMSV 9324;
BA_ "SigType" SG_ 2565943038 DeviceRatedFreq 1;
BA_ "SPN" SG_ 2565943038 DeviceRatedFreq 9323;
BA_ "SigType" SG_ 2565943038 DeviceMinFreq 1;
BA_ "SPN" SG_ 2565943038 DeviceMinFreq 9322;
BA_ "SigType" SG_ 2565943038 DeviceMaxFreq 1;
BA_ "SPN" SG_ 2565943038 DeviceMaxFreq 9321;
BA_ "SigType" SG_ 2565942782 PLedDueToUndefinedReason 5;
BA_ "SPN" SG_ 2565942782 PLedDueToUndefinedReason 9310;
BA_ "SigType" SG_ 2565942782 PLedDueToRateOfChangeLmt 5;
BA_ "SPN" SG_ 2565942782 PLedDueToRateOfChangeLmt 9309;
BA_ "SigType" SG_ 2565942782 PLedDueToPwrETemp 5;
BA_ "SPN" SG_ 2565942782 PLedDueToPwrETemp 9308;
BA_ "SigType" SG_ 2565942782 PLedDueToEFilterTemp 5;
BA_ "SPN" SG_ 2565942782 PLedDueToEFilterTemp 9307;
BA_ "SigType" SG_ 2565942782 PLedDueToCtrlTemp 5;
BA_ "SPN" SG_ 2565942782 PLedDueToCtrlTemp 9306;
BA_ "SigType" SG_ 2565942782 FreqCmdExceedsMax 5;
BA_ "SPN" SG_ 2565942782 FreqCmdExceedsMax 9305;
BA_ "SigType" SG_ 2565942782 FreqCmdBelowMin 5;
BA_ "SPN" SG_ 2565942782 FreqCmdBelowMin 9304;
BA_ "SigType" SG_ 2565942782 PLedDueToDCSideVMin 5;
BA_ "SPN" SG_ 2565942782 PLedDueToDCSideVMin 9303;
BA_ "SigType" SG_ 2565942782 PLedDueToACSideRMSCur 5;
BA_ "SPN" SG_ 2565942782 PLedDueToACSideRMSCur 9302;
BA_ "SigType" SG_ 2565942782 PLedDueToDCSideCur 5;
BA_ "SPN" SG_ 2565942782 PLedDueToDCSideCur 9301;
BA_ "SigType" SG_ 2364615934 SLIV 1;
BA_ "SPN" SG_ 2364615934 SLIV 9300;
BA_ "SigType" SG_ 2364615934 IgntV 1;
BA_ "SPN" SG_ 2364615934 IgntV 9299;
BA_ "SigType" SG_ 2364615678 DCSideNegToChassisGroundV 1;
BA_ "SPN" SG_ 2364615678 DCSideNegToChassisGroundV 9585;
BA_ "SigType" SG_ 2364615678 DCSideCur 1;
BA_ "SPN" SG_ 2364615678 DCSideCur 9298;
BA_ "SigType" SG_ 2364615678 DCSideV 1;
BA_ "SPN" SG_ 2364615678 DCSideV 9297;
BA_ "SigType" SG_ 2364615678 DCSidePwr 1;
BA_ "SPN" SG_ 2364615678 DCSidePwr 9296;
BA_ "SigType" SG_ 2565942014 PLedDueToUndefinedReason 5;
BA_ "SPN" SG_ 2565942014 PLedDueToUndefinedReason 9280;
BA_ "SigType" SG_ 2565942014 PLedDueToRateOfChangeLmt 5;
BA_ "SPN" SG_ 2565942014 PLedDueToRateOfChangeLmt 9279;
BA_ "SigType" SG_ 2565942014 PLedDueToPwrETemp 5;
BA_ "SPN" SG_ 2565942014 PLedDueToPwrETemp 9278;
BA_ "SigType" SG_ 2565942014 PLedDueToEFilterTemp 5;
BA_ "SPN" SG_ 2565942014 PLedDueToEFilterTemp 9277;
BA_ "SigType" SG_ 2565942014 PLedDueToCtrlTemp 5;
BA_ "SPN" SG_ 2565942014 PLedDueToCtrlTemp 9276;
BA_ "SigType" SG_ 2565942014 FreqCmdExceedsMax 5;
BA_ "SPN" SG_ 2565942014 FreqCmdExceedsMax 9275;
BA_ "SigType" SG_ 2565942014 FreqCmdBelowMin 5;
BA_ "SPN" SG_ 2565942014 FreqCmdBelowMin 9274;
BA_ "SigType" SG_ 2565942014 PLedDueToDCSideVMin 5;
BA_ "SPN" SG_ 2565942014 PLedDueToDCSideVMin 9273;
BA_ "SigType" SG_ 2565942014 PLedDueToACSideRMSCur 5;
BA_ "SPN" SG_ 2565942014 PLedDueToACSideRMSCur 9272;
BA_ "SigType" SG_ 2565942014 PLedDueToDCSideCur 5;
BA_ "SPN" SG_ 2565942014 PLedDueToDCSideCur 9271;
BA_ "SigType" SG_ 2364615166 SLIV 1;
BA_ "SPN" SG_ 2364615166 SLIV 9270;
BA_ "SigType" SG_ 2364615166 IgntV 1;
BA_ "SPN" SG_ 2364615166 IgntV 9269;
BA_ "SigType" SG_ 2364614910 DCSideNegToChassisGroundV 1;
BA_ "SPN" SG_ 2364614910 DCSideNegToChassisGroundV 9584;
BA_ "SigType" SG_ 2364614910 DCSideCur 1;
BA_ "SPN" SG_ 2364614910 DCSideCur 9268;
BA_ "SigType" SG_ 2364614910 DCSideV 1;
BA_ "SPN" SG_ 2364614910 DCSideV 9267;
BA_ "SigType" SG_ 2364614910 DCSidePwr 1;
BA_ "SPN" SG_ 2364614910 DCSidePwr 9266;
BA_ "SigType" SG_ 2364614654 GradeThresholdInd6 4;
BA_ "SPN" SG_ 2364614654 GradeThresholdInd6 9186;
BA_ "SigType" SG_ 2364614654 GradeThresholdInd5 4;
BA_ "SPN" SG_ 2364614654 GradeThresholdInd5 9185;
BA_ "SigType" SG_ 2364614654 GradeThresholdInd4 4;
BA_ "SPN" SG_ 2364614654 GradeThresholdInd4 9184;
BA_ "SigType" SG_ 2364614654 GradeThresholdInd3 4;
BA_ "SPN" SG_ 2364614654 GradeThresholdInd3 9183;
BA_ "SigType" SG_ 2364614654 GradeThresholdInd2 4;
BA_ "SPN" SG_ 2364614654 GradeThresholdInd2 9182;
BA_ "SigType" SG_ 2364614654 GradeThresholdInd1 4;
BA_ "SPN" SG_ 2364614654 GradeThresholdInd1 9181;
BA_ "SigType" SG_ 2364614398 FourHiSideNegToChassisGroundV 1;
BA_ "SPN" SG_ 2364614398 FourHiSideNegToChassisGroundV 9590;
BA_ "SigType" SG_ 2364614398 FourHiSidePwr 1;
BA_ "SPN" SG_ 2364614398 FourHiSidePwr 9029;
BA_ "SigType" SG_ 2364614398 FourLowSidePwr 1;
BA_ "SPN" SG_ 2364614398 FourLowSidePwr 9028;
BA_ "SigType" SG_ 2364614142 SLIBatTermTemp 1;
BA_ "SPN" SG_ 2364614142 SLIBatTermTemp 9027;
BA_ "SigType" SG_ 2364614142 SLIBatTermCur 1;
BA_ "SPN" SG_ 2364614142 SLIBatTermCur 9026;
BA_ "SigType" SG_ 2364614142 SLIBatTermV 1;
BA_ "SPN" SG_ 2364614142 SLIBatTermV 9025;
BA_ "SigType" SG_ 2364613886 FourHiSideCur 1;
BA_ "SPN" SG_ 2364613886 FourHiSideCur 9024;
BA_ "SigType" SG_ 2364613886 FourHiSideV 1;
BA_ "SPN" SG_ 2364613886 FourHiSideV 9023;
BA_ "SigType" SG_ 2364613886 FourLowSideCur 1;
BA_ "SPN" SG_ 2364613886 FourLowSideCur 9022;
BA_ "SigType" SG_ 2364613886 FourLowSideV 1;
BA_ "SPN" SG_ 2364613886 FourLowSideV 9021;
BA_ "SigType" SG_ 2364613630 DCDC4OperatingStatusCRC 12;
BA_ "SPN" SG_ 2364613630 DCDC4OperatingStatusCRC 8628;
BA_ "SigType" SG_ 2364613630 DCDC4OperatingStatusCounter 11;
BA_ "SPN" SG_ 2364613630 DCDC4OperatingStatusCounter 8627;
BA_ "SigType" SG_ 2364613630 FourPLDueToUndefinedReason 4;
BA_ "SPN" SG_ 2364613630 FourPLDueToUndefinedReason 9020;
BA_ "SigType" SG_ 2364613630 FourPLDueToSLIBatTermTemp 4;
BA_ "SPN" SG_ 2364613630 FourPLDueToSLIBatTermTemp 9019;
BA_ "SigType" SG_ 2364613630 FourPLDueToSLIBatTermCur 4;
BA_ "SPN" SG_ 2364613630 FourPLDueToSLIBatTermCur 9018;
BA_ "SigType" SG_ 2364613630 FourPLDueToSLIBatTermV 4;
BA_ "SPN" SG_ 2364613630 FourPLDueToSLIBatTermV 9017;
BA_ "SigType" SG_ 2364613630 FourPLDueToPwrETemp 4;
BA_ "SPN" SG_ 2364613630 FourPLDueToPwrETemp 9016;
BA_ "SigType" SG_ 2364613630 FourPLDueToEFilterTemp 4;
BA_ "SPN" SG_ 2364613630 FourPLDueToEFilterTemp 9015;
BA_ "SigType" SG_ 2364613630 FourPLDueToConvTemp 4;
BA_ "SPN" SG_ 2364613630 FourPLDueToConvTemp 9014;
BA_ "SigType" SG_ 2364613630 FourPLDueToLowSideVMax 4;
BA_ "SPN" SG_ 2364613630 FourPLDueToLowSideVMax 9013;
BA_ "SigType" SG_ 2364613630 FourPLDueToLowSideVMin 4;
BA_ "SPN" SG_ 2364613630 FourPLDueToLowSideVMin 9012;
BA_ "SigType" SG_ 2364613630 FourPLDueToHiSideVMax 4;
BA_ "SPN" SG_ 2364613630 FourPLDueToHiSideVMax 9011;
BA_ "SigType" SG_ 2364613630 FourPLDueToHiSideVMin 4;
BA_ "SPN" SG_ 2364613630 FourPLDueToHiSideVMin 9010;
BA_ "SigType" SG_ 2364613630 FourPLDueToLowSideCur 4;
BA_ "SPN" SG_ 2364613630 FourPLDueToLowSideCur 9009;
BA_ "SigType" SG_ 2364613630 FourPLDueToHiSideCur 4;
BA_ "SPN" SG_ 2364613630 FourPLDueToHiSideCur 9008;
BA_ "SigType" SG_ 2364613630 FourLoadshedReq 5;
BA_ "SPN" SG_ 2364613630 FourLoadshedReq 9007;
BA_ "SigType" SG_ 2364613630 FourHVILStatus 4;
BA_ "SPN" SG_ 2364613630 FourHVILStatus 9006;
BA_ "SPN" SG_ 2364613630 FourOperationalStatus 9005;
BA_ "SigType" SG_ 2364613374 DCDC4CtrlCRC 12;
BA_ "SPN" SG_ 2364613374 DCDC4CtrlCRC 8626;
BA_ "SigType" SG_ 2364613374 DCDC4CtrlCounter 11;
BA_ "SPN" SG_ 2364613374 DCDC4CtrlCounter 8625;
BA_ "SigType" SG_ 2364613374 FourLowSideVBuckDefaultSetpoint 1;
BA_ "SPN" SG_ 2364613374 FourLowSideVBuckDefaultSetpoint 9518;
BA_ "SigType" SG_ 2364613374 FourHiSideVBoostSetpoint 1;
BA_ "SPN" SG_ 2364613374 FourHiSideVBoostSetpoint 9004;
BA_ "SigType" SG_ 2364613374 FourLowSideVBuckSetpoint 1;
BA_ "SPN" SG_ 2364613374 FourLowSideVBuckSetpoint 9003;
BA_ "SPN" SG_ 2364613374 FourOperationalCmd 9002;
BA_ "SigType" SG_ 2364613118 ThreeHiSideNegToChassisGroundV 1;
BA_ "SPN" SG_ 2364613118 ThreeHiSideNegToChassisGroundV 9589;
BA_ "SigType" SG_ 2364613118 ThreeHiSidePwr 1;
BA_ "SPN" SG_ 2364613118 ThreeHiSidePwr 8974;
BA_ "SigType" SG_ 2364613118 ThreeLowSidePwr 1;
BA_ "SPN" SG_ 2364613118 ThreeLowSidePwr 8973;
BA_ "SigType" SG_ 2364612862 SLIBatTermTemp 1;
BA_ "SPN" SG_ 2364612862 SLIBatTermTemp 8972;
BA_ "SigType" SG_ 2364612862 SLIBatTermCur 1;
BA_ "SPN" SG_ 2364612862 SLIBatTermCur 8971;
BA_ "SigType" SG_ 2364612862 SLIBatTermV 1;
BA_ "SPN" SG_ 2364612862 SLIBatTermV 8970;
BA_ "SigType" SG_ 2364612606 ThreeHiSideCur 1;
BA_ "SPN" SG_ 2364612606 ThreeHiSideCur 8969;
BA_ "SigType" SG_ 2364612606 ThreeHiSideV 1;
BA_ "SPN" SG_ 2364612606 ThreeHiSideV 8968;
BA_ "SigType" SG_ 2364612606 ThreeLowSideCur 1;
BA_ "SPN" SG_ 2364612606 ThreeLowSideCur 8967;
BA_ "SigType" SG_ 2364612606 ThreeLowSideV 1;
BA_ "SPN" SG_ 2364612606 ThreeLowSideV 8966;
BA_ "SigType" SG_ 2364612350 DCDC3OperatingStatusCRC 12;
BA_ "SPN" SG_ 2364612350 DCDC3OperatingStatusCRC 7966;
BA_ "SigType" SG_ 2364612350 DCDC3OperatingStatusCounter 11;
BA_ "SPN" SG_ 2364612350 DCDC3OperatingStatusCounter 7965;
BA_ "SigType" SG_ 2364612350 ThreePLDueToUndefinedReason 4;
BA_ "SPN" SG_ 2364612350 ThreePLDueToUndefinedReason 8965;
BA_ "SigType" SG_ 2364612350 ThreePLDueToSLIBatTermTemp 4;
BA_ "SPN" SG_ 2364612350 ThreePLDueToSLIBatTermTemp 8964;
BA_ "SigType" SG_ 2364612350 ThreePLDueToSLIBatTermCur 4;
BA_ "SPN" SG_ 2364612350 ThreePLDueToSLIBatTermCur 8963;
BA_ "SigType" SG_ 2364612350 ThreePLDueToSLIBatTermV 4;
BA_ "SPN" SG_ 2364612350 ThreePLDueToSLIBatTermV 8962;
BA_ "SigType" SG_ 2364612350 ThreePLDueToPwrETemp 4;
BA_ "SPN" SG_ 2364612350 ThreePLDueToPwrETemp 8961;
BA_ "SigType" SG_ 2364612350 ThreePLDueToEFilterTemp 4;
BA_ "SPN" SG_ 2364612350 ThreePLDueToEFilterTemp 8960;
BA_ "SigType" SG_ 2364612350 ThreePLDueToConvTemp 4;
BA_ "SPN" SG_ 2364612350 ThreePLDueToConvTemp 8959;
BA_ "SigType" SG_ 2364612350 ThreePLDueToLowSideVMax 4;
BA_ "SPN" SG_ 2364612350 ThreePLDueToLowSideVMax 8958;
BA_ "SigType" SG_ 2364612350 ThreePLDueToLowSideVMin 4;
BA_ "SPN" SG_ 2364612350 ThreePLDueToLowSideVMin 8957;
BA_ "SigType" SG_ 2364612350 ThreePLDueToHiSideVMax 4;
BA_ "SPN" SG_ 2364612350 ThreePLDueToHiSideVMax 8956;
BA_ "SigType" SG_ 2364612350 ThreePLDueToHiSideVMin 4;
BA_ "SPN" SG_ 2364612350 ThreePLDueToHiSideVMin 8955;
BA_ "SigType" SG_ 2364612350 ThreePLDueToLowSideCur 4;
BA_ "SPN" SG_ 2364612350 ThreePLDueToLowSideCur 8954;
BA_ "SigType" SG_ 2364612350 ThreePLDueToHiSideCur 4;
BA_ "SPN" SG_ 2364612350 ThreePLDueToHiSideCur 8953;
BA_ "SigType" SG_ 2364612350 ThreeLoadshedReq 5;
BA_ "SPN" SG_ 2364612350 ThreeLoadshedReq 8952;
BA_ "SigType" SG_ 2364612350 ThreeHVILStatus 4;
BA_ "SPN" SG_ 2364612350 ThreeHVILStatus 8951;
BA_ "SPN" SG_ 2364612350 ThreeOperationalStatus 8950;
BA_ "SigType" SG_ 2364612094 DCDC3CtrlCRC 12;
BA_ "SPN" SG_ 2364612094 DCDC3CtrlCRC 7964;
BA_ "SigType" SG_ 2364612094 DCDC3CtrlCounter 11;
BA_ "SPN" SG_ 2364612094 DCDC3CtrlCounter 7963;
BA_ "SigType" SG_ 2364612094 ThreeLowSideVBuckDefaultSetpoint 1;
BA_ "SPN" SG_ 2364612094 ThreeLowSideVBuckDefaultSetpoint 9517;
BA_ "SigType" SG_ 2364612094 ThreeHiSideVBoostSetpoint 1;
BA_ "SPN" SG_ 2364612094 ThreeHiSideVBoostSetpoint 8949;
BA_ "SigType" SG_ 2364612094 ThreeLowSideVBuckSetpoint 1;
BA_ "SPN" SG_ 2364612094 ThreeLowSideVBuckSetpoint 8948;
BA_ "SPN" SG_ 2364612094 ThreeOperationalCmd 8947;
BA_ "SigType" SG_ 2364611838 TwoHiSideNegToChassisGroundV 1;
BA_ "SPN" SG_ 2364611838 TwoHiSideNegToChassisGroundV 9588;
BA_ "SigType" SG_ 2364611838 TwoHiSidePwr 1;
BA_ "SPN" SG_ 2364611838 TwoHiSidePwr 8919;
BA_ "SigType" SG_ 2364611838 TwoLowSidePwr 1;
BA_ "SPN" SG_ 2364611838 TwoLowSidePwr 8918;
BA_ "SigType" SG_ 2364611582 SLIBatTermTemp 1;
BA_ "SPN" SG_ 2364611582 SLIBatTermTemp 8917;
BA_ "SigType" SG_ 2364611582 SLIBatTermCur 1;
BA_ "SPN" SG_ 2364611582 SLIBatTermCur 8916;
BA_ "SigType" SG_ 2364611582 SLIBatTermV 1;
BA_ "SPN" SG_ 2364611582 SLIBatTermV 8915;
BA_ "SigType" SG_ 2364611326 TwoHiSideCur 1;
BA_ "SPN" SG_ 2364611326 TwoHiSideCur 8914;
BA_ "SigType" SG_ 2364611326 TwoHiSideV 1;
BA_ "SPN" SG_ 2364611326 TwoHiSideV 8913;
BA_ "SigType" SG_ 2364611326 TwoLowSideCur 1;
BA_ "SPN" SG_ 2364611326 TwoLowSideCur 8912;
BA_ "SigType" SG_ 2364611326 TwoLowSideV 1;
BA_ "SPN" SG_ 2364611326 TwoLowSideV 8911;
BA_ "SigType" SG_ 2364611070 DCDC2OperatingStatusCRC 12;
BA_ "SPN" SG_ 2364611070 DCDC2OperatingStatusCRC 7962;
BA_ "SigType" SG_ 2364611070 DCDC2OperatingStatusCounter 11;
BA_ "SPN" SG_ 2364611070 DCDC2OperatingStatusCounter 7961;
BA_ "SigType" SG_ 2364611070 TwoPLDueToUndefinedReason 4;
BA_ "SPN" SG_ 2364611070 TwoPLDueToUndefinedReason 8910;
BA_ "SigType" SG_ 2364611070 TwoPLDueToSLIBatTermTemp 4;
BA_ "SPN" SG_ 2364611070 TwoPLDueToSLIBatTermTemp 8909;
BA_ "SigType" SG_ 2364611070 TwoPLDueToSLIBatTermCur 4;
BA_ "SPN" SG_ 2364611070 TwoPLDueToSLIBatTermCur 8908;
BA_ "SigType" SG_ 2364611070 TwoPLDueToSLIBatTermV 4;
BA_ "SPN" SG_ 2364611070 TwoPLDueToSLIBatTermV 8907;
BA_ "SigType" SG_ 2364611070 TwoPLDueToPwrETemp 4;
BA_ "SPN" SG_ 2364611070 TwoPLDueToPwrETemp 8906;
BA_ "SigType" SG_ 2364611070 TwoPLDueToEFilterTemp 4;
BA_ "SPN" SG_ 2364611070 TwoPLDueToEFilterTemp 8905;
BA_ "SigType" SG_ 2364611070 TwoPLDueToConvTemp 4;
BA_ "SPN" SG_ 2364611070 TwoPLDueToConvTemp 8904;
BA_ "SigType" SG_ 2364611070 TwoPLDueToLowSideVMax 4;
BA_ "SPN" SG_ 2364611070 TwoPLDueToLowSideVMax 8903;
BA_ "SigType" SG_ 2364611070 TwoPLDueToLowSideVMin 4;
BA_ "SPN" SG_ 2364611070 TwoPLDueToLowSideVMin 8902;
BA_ "SigType" SG_ 2364611070 TwoPLDueToHiSideVMax 4;
BA_ "SPN" SG_ 2364611070 TwoPLDueToHiSideVMax 8901;
BA_ "SigType" SG_ 2364611070 TwoPLDueToHiSideVMin 4;
BA_ "SPN" SG_ 2364611070 TwoPLDueToHiSideVMin 8900;
BA_ "SigType" SG_ 2364611070 TwoPLDueToLowSideCur 4;
BA_ "SPN" SG_ 2364611070 TwoPLDueToLowSideCur 8899;
BA_ "SigType" SG_ 2364611070 TwoPLDueToHiSideCur 4;
BA_ "SPN" SG_ 2364611070 TwoPLDueToHiSideCur 8898;
BA_ "SigType" SG_ 2364611070 TwoLoadshedReq 5;
BA_ "SPN" SG_ 2364611070 TwoLoadshedReq 8897;
BA_ "SigType" SG_ 2364611070 TwoHVILStatus 4;
BA_ "SPN" SG_ 2364611070 TwoHVILStatus 8896;
BA_ "SPN" SG_ 2364611070 TwoOperationalStatus 8895;
BA_ "SigType" SG_ 2364610814 DCDC2CtrlCRC 12;
BA_ "SPN" SG_ 2364610814 DCDC2CtrlCRC 7960;
BA_ "SigType" SG_ 2364610814 DCDC2CtrlCounter 11;
BA_ "SPN" SG_ 2364610814 DCDC2CtrlCounter 7959;
BA_ "SigType" SG_ 2364610814 TwoLowSideVBuckDefaultSetpoint 1;
BA_ "SPN" SG_ 2364610814 TwoLowSideVBuckDefaultSetpoint 9516;
BA_ "SigType" SG_ 2364610814 TwoHiSideVBoostSetpoint 1;
BA_ "SPN" SG_ 2364610814 TwoHiSideVBoostSetpoint 8894;
BA_ "SigType" SG_ 2364610814 TwoLowSideVBuckSetpoint 1;
BA_ "SPN" SG_ 2364610814 TwoLowSideVBuckSetpoint 8893;
BA_ "SPN" SG_ 2364610814 TwoOperationalCmd 8892;
BA_ "SigType" SG_ 2364610558 OneHiSideNegToChassisGroundV 1;
BA_ "SPN" SG_ 2364610558 OneHiSideNegToChassisGroundV 9587;
BA_ "SigType" SG_ 2364610558 OneHiSidePwr 1;
BA_ "SPN" SG_ 2364610558 OneHiSidePwr 8821;
BA_ "SigType" SG_ 2364610558 OneLowSidePwr 1;
BA_ "SPN" SG_ 2364610558 OneLowSidePwr 8820;
BA_ "SigType" SG_ 2565918206 PLedDueToUndefinedReason 5;
BA_ "SPN" SG_ 2565918206 PLedDueToUndefinedReason 9250;
BA_ "SigType" SG_ 2565918206 PLedDueToRateOfChangeLmt 5;
BA_ "SPN" SG_ 2565918206 PLedDueToRateOfChangeLmt 9249;
BA_ "SigType" SG_ 2565918206 PLedDueToPwrETemp 5;
BA_ "SPN" SG_ 2565918206 PLedDueToPwrETemp 9248;
BA_ "SigType" SG_ 2565918206 PLedDueToEFilterTemp 5;
BA_ "SPN" SG_ 2565918206 PLedDueToEFilterTemp 9247;
BA_ "SigType" SG_ 2565918206 PLedDueToCtrlTemp 5;
BA_ "SPN" SG_ 2565918206 PLedDueToCtrlTemp 9246;
BA_ "SigType" SG_ 2565918206 FreqCmdExceedsMax 5;
BA_ "SPN" SG_ 2565918206 FreqCmdExceedsMax 9245;
BA_ "SigType" SG_ 2565918206 FreqCmdBelowMin 5;
BA_ "SPN" SG_ 2565918206 FreqCmdBelowMin 9244;
BA_ "SigType" SG_ 2565918206 PLedDueToDCSideVMin 5;
BA_ "SPN" SG_ 2565918206 PLedDueToDCSideVMin 9243;
BA_ "SigType" SG_ 2565918206 PLedDueToACSideRMSCur 5;
BA_ "SPN" SG_ 2565918206 PLedDueToACSideRMSCur 9242;
BA_ "SigType" SG_ 2565918206 PLedDueToDCSideCur 5;
BA_ "SPN" SG_ 2565918206 PLedDueToDCSideCur 9241;
BA_ "SigType" SG_ 2364591358 SLIV 1;
BA_ "SPN" SG_ 2364591358 SLIV 9240;
BA_ "SigType" SG_ 2364591358 IgntV 1;
BA_ "SPN" SG_ 2364591358 IgntV 9239;
BA_ "SigType" SG_ 2364591102 DCSideNegToChassisGroundV 1;
BA_ "SPN" SG_ 2364591102 DCSideNegToChassisGroundV 9583;
BA_ "SigType" SG_ 2364591102 DCSideCur 1;
BA_ "SPN" SG_ 2364591102 DCSideCur 9238;
BA_ "SigType" SG_ 2364591102 DCSideV 1;
BA_ "SPN" SG_ 2364591102 DCSideV 9237;
BA_ "SigType" SG_ 2364591102 DCSidePwr 1;
BA_ "SPN" SG_ 2364591102 DCSidePwr 9236;
VAL_ 2566621694 OilLvl2St 3 "Not available" 2 "Error" 1 "Normal" 0 "Low" ;
VAL_ 2566621694 OilLvl1St 3 "Not available" 2 "Error" 1 "Normal" 0 "Low" ;
VAL_ 2566621438 HeavySeaModeEnable 3 "Take no action" 2 "Reserved" 1 "Marine heavy sea mode is enabled" 0 "Marine heavy sea mode is disabled" ;
VAL_ 2566621438 SlowVesselModeLampStatus 3 "Not Available" 2 "Error" 1 "On" 0 "Off" ;
VAL_ 2566621438 GearLockoutLampStatus 3 "Not Available" 2 "Error" 1 "On" 0 "Off" ;
VAL_ 2566621438 EngThrotLeverSynchLampStatus 3 "Not Available" 2 "Error" 1 "On" 0 "Off" ;
VAL_ 2566621438 TrollingModeLampStatus 3 "Not Available" 2 "Error" 1 "On" 0 "Off" ;
VAL_ 2566621438 OpStationActiveLampStatus 3 "Not Available" 2 "Error" 1 "On" 0 "Off" ;
VAL_ 2566621438 SlowVesselModeButtonStatus 3 "Not Available" 2 "Error" 1 "Button pressed" 0 "Button not pressed" ;
VAL_ 2566621438 GearLockoutButtonStatus 3 "Not Available" 2 "Error" 1 "Button pressed" 0 "Button not pressed" ;
VAL_ 2566621438 EngThrotLeverSynchButtonStatus 3 "Not Available" 2 "Error" 1 "Button pressed" 0 "Button not pressed" ;
VAL_ 2566621438 TrollingModeButtonStatus 3 "Not Available" 2 "Error" 1 "Button pressed" 0 "Button not pressed" ;
VAL_ 2566621438 OpStationActiveButtonStatus 3 "Not Available" 2 "Error" 1 "Button pressed" 0 "Button not pressed" ;
VAL_ 2566621438 StationGearPosMatch 3 "Not Available or Not Installed" 2 "Error" 1 "Not in neutral" 0 "Neutral" ;
VAL_ 2566621438 StationThrotPosMatch 3 "Not Available or Not Installed" 2 "Error" 1 "Throttle positions match" 0 "Throttle positions do not match" ;
VAL_ 2566620670 ShutdownReason 15 "Not available" 14 "Error" 13 "Reserved" 12 "Reserved" 11 "Reserved" 10 "Reserved" 9 "Engine idle reduction system failure" 8 "Ambient temperature" 7 "Engine exhaust temperature" 6 "SLI Battery pack #2 state of charge" 5 "SLI Battery pack #1 state of charge" 4 "Power end lube oil temperature" 3 "Transmission oil temperature" 2 "SLI Battery voltage" 1 "Engine coolant temperature" 0 "Operator input request" ;
VAL_ 2566620670 RestartReason 15 "Not available" 14 "Error" 13 "Reserved" 12 "Reserved" 11 "Reserved" 10 "Reserved" 9 "Reserved" 8 "Reserved" 7 "Failure of one or more components" 6 "Low SLI battery pack #2 state of charge" 5 "Low SLI battery pack #1 state of charge" 4 "Low power end lube oil temperature" 3 "Low transmission oil temperature" 2 "Low SLI battery voltage" 1 "Low engine coolant temperature" 0 "Operator input request" ;
VAL_ 2566620670 Status 15 "Not Available" 14 "Error" 13 "Reserved" 12 "Reserved" 11 "Reserved" 10 "Reserved" 9 "Auto start inhibited" 8 "Restart conditions pending" 7 "Restart conditions not met" 6 "Shutdown" 5 "Shutdown conditions pending" 4 "Shutdown conditions not met" 3 "Activation conditions not met" 2 "Disabled" 1 "Locked" 0 "Off" ;
VAL_ 2364620286 HandsOffDetectionAvailability 7 "Not Available" 6 "Error" 5 "Reserved" 4 "Reserved" 3 "Hands Off Detection Disabled" 2 "Hands Off Detection Available" 1 "Hands Off Detection Temporarily Not Available" 0 "Hands Off Detection Not Ready" ;
VAL_ 2364620286 HandsOffDetectionStatus 7 "Not Available" 6 "Error" 5 "Reserved" 4 "Reserved" 3 "Reserved" 2 "Hands Off Detection Disabled" 1 "Hands Off Detected" 0 "Hands Off Not Detected" ;
VAL_ 2364620286 LaneCenteringSysStatus 15 "Not Available" 14 "Error" 13 "Reserved" 12 "Reserved" 11 "Reserved" 10 "Reserved" 9 "Reserved" 8 "Reserved" 7 "Reserved" 6 "Reserved" 5 "Lane Centering System is actuating" 4 "Lane Centering suppressed by operator behavior" 3 "System is ready" 2 "System is deactivated by driver" 1 "System is temporarily not available" 0 "System is not ready" ;
VAL_ 2364620286 LaneCenteringIndEnableSt 3 "Not available" 2 "Error" 1 "Lane Centering Indication enabled" 0 "Lane Centering Indication disabled" ;
VAL_ 2364620286 DriverPref 7 "Not available/Not valid" 6 "Error" 5 "Active Steering Mode #6" 4 "Active Steering Mode #5" 3 "Active Steering Mode #4" 2 "Active Steering Mode #3" 1 "Active Steering Mode #2" 0 "Active Steering Mode #1" ;
VAL_ 2364620286 LaneKeepingAssistSysSt 15 "Not Available" 14 "Error" 13 "Reserved" 12 "Reserved" 11 "Reserved" 10 "Reserved" 9 "Reserved" 8 "Reserved" 7 "Reserved" 6 "Reserved" 5 "System is actuating" 4 "Active lane keeping suppressed by operator behavior" 3 "System is ready" 2 "System is deactivated by driver" 1 "System is temporarily not available" 0 "System is not ready" ;
VAL_ 2364620286 LaneKeepingAssistIndEnableStatus 3 "Not available" 2 "Error" 1 "Lane Keeping Assist enabled" 0 "Lane Keeping Assist disabled" ;
VAL_ 2364620286 LaneKeepingAssistStatusLeftSide 7 "Not available" 6 "Error" 5 "Reserved" 4 "BlindSpot Assist Active for Left Side" 3 "Lane Keeping Assist Active for Left Side" 2 "Lane Keeping Assist Suppressed for Left Side" 1 "Lane Keeping Assist Available for Left Side" 0 "Lane Keeping Assist Not Available for Left Side" ;
VAL_ 2364620286 LaneKeepingAssistStatusRightSide 7 "Not available" 6 "Error" 5 "Reserved" 4 "BlindSpot Assist Active for Right Side" 3 "Lane Keeping Assist Active for Right Side" 2 "Lane Keeping Assist Suppressed for Right Side" 1 "Lane Keeping Assist Available for Right Side" 0 "Lane Keeping Assist Not Available for Right Side" ;
VAL_ 2565944062 PLedDueToUndefinedReason 3 "Not Available" 2 "Error" 1 "Power limited for this reason" 0 "No power limit for this reason" ;
VAL_ 2565944062 PLedDueToRateOfChangeLmt 3 "Not Available" 2 "Error" 1 "Power limited for this reason" 0 "No power limit for this reason" ;
VAL_ 2565944062 PLedDueToPwrETemp 3 "Not Available" 2 "Error" 1 "Power limited for this reason" 0 "No power limit for this reason" ;
VAL_ 2565944062 PLedDueToEFilterTemp 3 "Not Available" 2 "Error" 1 "Power limited for this reason" 0 "No power limit for this reason" ;
VAL_ 2565944062 PLedDueToCtrlTemp 3 "Not Available" 2 "Error" 1 "Power limited for this reason" 0 "No power limit for this reason" ;
VAL_ 2565944062 FreqCmdExceedsMax 3 "Not Available" 2 "Error" 1 "Frequency limited for this reason" 0 "No frequency limit for this reason" ;
VAL_ 2565944062 FreqCmdBelowMin 3 "Not Available" 2 "Error" 1 "Frequency limited for this reason" 0 "No frequency limit for this reason" ;
VAL_ 2565944062 PLedDueToDCSideVMin 3 "Not Available" 2 "Error" 1 "Power limited for this reason" 0 "No power limit for this reason" ;
VAL_ 2565944062 PLedDueToACSideRMSCur 3 "Not Available" 2 "Error" 1 "Power limited for this reason" 0 "No power limit for this reason" ;
VAL_ 2565944062 PLedDueToDCSideCur 3 "Not Available" 2 "Error" 1 "Power limited for this reason" 0 "No power limit for this reason" ;
VAL_ 2565943294 HVILStatus 3 "Not Available" 2 "Error" 1 "HVIL Open" 0 "HVIL Closed" ;
VAL_ 2565943294 LoadshedReq 3 "Don't Care/Take No Action" 2 "Loadshed Requested,  Shutdown Imminent" 1 "Loadshed Requested" 0 "No Loadshed Requested" ;
VAL_ 2565943294 OperationalStatus 7 "Not Available" 6 "Error" 5 "Reserved" 4 "Normal Power Down in Process" 3 "Output Faulted Off" 2 "Output Faulted On" 1 "Output Enabled" 0 "Output Disabled" ;
VAL_ 2565943038 OperationalCmd 3 "Don't care/take no action" 2 "Power down DC/AC Accessory Inverter Controller" 1 "Enable DC/AC Accessory Inverter Output" 0 "Disable DC/AC Accessory Inverter Output" ;
VAL_ 2565943038 Device2Status 7 "Not Available" 6 "Error" 5 "Reserved for SAE Assignment" 4 "Reserved for SAE Assignment" 3 "Faulted Off" 2 "Faulted On" 1 "Off" 0 "On" ;
VAL_ 2565943038 Device1Status 7 "Not Available" 6 "Error" 5 "Reserved for SAE Assignment" 4 "Reserved for SAE Assignment" 3 "Faulted Off" 2 "Faulted On" 1 "Off" 0 "On" ;
VAL_ 2565942782 PLedDueToUndefinedReason 3 "Not Available" 2 "Error" 1 "Power limited for this reason" 0 "No power limit for this reason" ;
VAL_ 2565942782 PLedDueToRateOfChangeLmt 3 "Not Available" 2 "Error" 1 "Power limited for this reason" 0 "No power limit for this reason" ;
VAL_ 2565942782 PLedDueToPwrETemp 3 "Not Available" 2 "Error" 1 "Power limited for this reason" 0 "No power limit for this reason" ;
VAL_ 2565942782 PLedDueToEFilterTemp 3 "Not Available" 2 "Error" 1 "Power limited for this reason" 0 "No power limit for this reason" ;
VAL_ 2565942782 PLedDueToCtrlTemp 3 "Not Available" 2 "Error" 1 "Power limited for this reason" 0 "No power limit for this reason" ;
VAL_ 2565942782 FreqCmdExceedsMax 3 "Not Available" 2 "Error" 1 "Frequency limited for this reason" 0 "No frequency limit for this reason" ;
VAL_ 2565942782 FreqCmdBelowMin 3 "Not Available" 2 "Error" 1 "Frequency limited for this reason" 0 "No frequency limit for this reason" ;
VAL_ 2565942782 PLedDueToDCSideVMin 3 "Not Available" 2 "Error" 1 "Power limited for this reason" 0 "No power limit for this reason" ;
VAL_ 2565942782 PLedDueToACSideRMSCur 3 "Not Available" 2 "Error" 1 "Power limited for this reason" 0 "No power limit for this reason" ;
VAL_ 2565942782 PLedDueToDCSideCur 3 "Not Available" 2 "Error" 1 "Power limited for this reason" 0 "No power limit for this reason" ;
VAL_ 2565942014 PLedDueToUndefinedReason 3 "Not Available" 2 "Error" 1 "Power limited for this reason" 0 "No power limit for this reason" ;
VAL_ 2565942014 PLedDueToRateOfChangeLmt 3 "Not Available" 2 "Error" 1 "Power limited for this reason" 0 "No power limit for this reason" ;
VAL_ 2565942014 PLedDueToPwrETemp 3 "Not Available" 2 "Error" 1 "Power limited for this reason" 0 "No power limit for this reason" ;
VAL_ 2565942014 PLedDueToEFilterTemp 3 "Not Available" 2 "Error" 1 "Power limited for this reason" 0 "No power limit for this reason" ;
VAL_ 2565942014 PLedDueToCtrlTemp 3 "Not Available" 2 "Error" 1 "Power limited for this reason" 0 "No power limit for this reason" ;
VAL_ 2565942014 FreqCmdExceedsMax 3 "Not Available" 2 "Error" 1 "Frequency limited for this reason" 0 "No frequency limit for this reason" ;
VAL_ 2565942014 FreqCmdBelowMin 3 "Not Available" 2 "Error" 1 "Frequency limited for this reason" 0 "No frequency limit for this reason" ;
VAL_ 2565942014 PLedDueToDCSideVMin 3 "Not Available" 2 "Error" 1 "Power limited for this reason" 0 "No power limit for this reason" ;
VAL_ 2565942014 PLedDueToACSideRMSCur 3 "Not Available" 2 "Error" 1 "Power limited for this reason" 0 "No power limit for this reason" ;
VAL_ 2565942014 PLedDueToDCSideCur 3 "Not Available" 2 "Error" 1 "Power limited for this reason" 0 "No power limit for this reason" ;
VAL_ 2364614654 GradeThresholdInd6 3 "Not Available" 2 "Error" 1 "Current grade is equal to or exceeds the threshold" 0 "Current grade does not exceed the threshold" ;
VAL_ 2364614654 GradeThresholdInd5 3 "Not Available" 2 "Error" 1 "Current grade is equal to or exceeds the threshold" 0 "Current grade does not exceed the threshold" ;
VAL_ 2364614654 GradeThresholdInd4 3 "Not Available" 2 "Error" 1 "Current grade is equal to or exceeds the threshold" 0 "Current grade does not exceed the threshold" ;
VAL_ 2364614654 GradeThresholdInd3 3 "Not Available" 2 "Error" 1 "Current grade is equal to or exceeds the threshold" 0 "Current grade does not exceed the threshold" ;
VAL_ 2364614654 GradeThresholdInd2 3 "Not Available" 2 "Error" 1 "Current grade is equal to or exceeds the threshold" 0 "Current grade does not exceed the threshold" ;
VAL_ 2364614654 GradeThresholdInd1 3 "Not Available" 2 "Error" 1 "Current grade is equal to or exceeds the threshold" 0 "Current grade does not exceed the threshold" ;
VAL_ 2364613630 FourPLDueToUndefinedReason 3 "Not Available" 2 "Error" 1 "Power limited for this reason" 0 "No power limit for this reason" ;
VAL_ 2364613630 FourPLDueToSLIBatTermTemp 3 "Not Available" 2 "Error" 1 "Power limited for this reason" 0 "No power limit for this reason" ;
VAL_ 2364613630 FourPLDueToSLIBatTermCur 3 "Not Available" 2 "Error" 1 "Power limited for this reason" 0 "No power limit for this reason" ;
VAL_ 2364613630 FourPLDueToSLIBatTermV 3 "Not Available" 2 "Error" 1 "Power limited for this reason" 0 "No power limit for this reason" ;
VAL_ 2364613630 FourPLDueToPwrETemp 3 "Not Available" 2 "Error" 1 "Power limited for this reason" 0 "No power limit for this reason" ;
VAL_ 2364613630 FourPLDueToEFilterTemp 3 "Not available" 2 "Error" 1 "Power limited for this reason" 0 "No power limit for this reason" ;
VAL_ 2364613630 FourPLDueToConvTemp 3 "Not Available" 2 "Error" 1 "Power limited for this reason" 0 "No power limit for this reason" ;
VAL_ 2364613630 FourPLDueToLowSideVMax 3 "Not Available" 2 "Error" 1 "Power limited for this reason" 0 "No power limit for this reason" ;
VAL_ 2364613630 FourPLDueToLowSideVMin 3 "Not Available" 2 "Error" 1 "Power limited for this reason" 0 "No power limit for this reason" ;
VAL_ 2364613630 FourPLDueToHiSideVMax 3 "Not Available" 2 "Error" 1 "Power limited for this reason" 0 "No power limit for this reason" ;
VAL_ 2364613630 FourPLDueToHiSideVMin 3 "Not Available" 2 "Error" 1 "Power limited for this reason" 0 "No power limit for this reason" ;
VAL_ 2364613630 FourPLDueToLowSideCur 3 "Not Available" 2 "Error" 1 "Power limited for this reason" 0 "No power limit for this reason" ;
VAL_ 2364613630 FourPLDueToHiSideCur 3 "Not Available" 2 "Error" 1 "Power limited for this reason" 0 "No power limit for this reason" ;
VAL_ 2364613630 FourLoadshedReq 3 "Don't Care/Take No Action" 2 "Loadshed Requested,  Shutdown Imminent" 1 "Loadshed Requested" 0 "No Loadshed Requested" ;
VAL_ 2364613630 FourHVILStatus 3 "Not Available" 2 "Error" 1 "HVIL Open" 0 "HVIL Closed" ;
VAL_ 2364613630 FourOperationalStatus 15 "Not Available" 14 "Error" 13 "Manufacturer assignable state" 12 "Reserved" 11 "Reserved" 10 "Reserved" 9 "Reserved" 8 "Reserved" 7 "Reserved" 6 "Disabled due to malfunction or protection" 5 "Normal power down in process" 4 "Operational, Boost mode" 3 "Operational, Buck mode" 2 "Operational, Standby" 1 "Initialization in process" 0 "Disabled" ;
VAL_ 2364613374 FourOperationalCmd 15 "Don't care/ Take No Action" 13 "Reserved" 12 "Reserved" 11 "Reserved" 10 "Reserved" 9 "Reserved" 8 "Reserved" 7 "Reserved" 6 "Reserved" 5 "Reserved" 4 "Power down DC/DC Converter" 3 "Operate in boost mode" 2 "Operate in buck mode" 1 "Operate in standby mode" 0 "Disable" ;
VAL_ 2364612350 ThreePLDueToUndefinedReason 3 "Not Available" 2 "Error" 1 "Power limited for this reason" 0 "No power limit for this reason" ;
VAL_ 2364612350 ThreePLDueToSLIBatTermTemp 3 "Not Available" 2 "Error" 1 "Power limited for this reason" 0 "No power limit for this reason" ;
VAL_ 2364612350 ThreePLDueToSLIBatTermCur 3 "Not Available" 2 "Error" 1 "Power limited for this reason" 0 "No power limit for this reason" ;
VAL_ 2364612350 ThreePLDueToSLIBatTermV 3 "Not Available" 2 "Error" 1 "Power limited for this reason" 0 "No power limit for this reason" ;
VAL_ 2364612350 ThreePLDueToPwrETemp 3 "Not Available" 2 "Error" 1 "Power limited for this reason" 0 "No power limit for this reason" ;
VAL_ 2364612350 ThreePLDueToEFilterTemp 3 "Not available" 2 "Error" 1 "Power limited for this reason" 0 "No power limit for this reason" ;
VAL_ 2364612350 ThreePLDueToConvTemp 3 "Not Available" 2 "Error" 1 "Power limited for this reason" 0 "No power limit for this reason" ;
VAL_ 2364612350 ThreePLDueToLowSideVMax 3 "Not Available" 2 "Error" 1 "Power limited for this reason" 0 "No power limit for this reason" ;
VAL_ 2364612350 ThreePLDueToLowSideVMin 3 "Not Available" 2 "Error" 1 "Power limited for this reason" 0 "No power limit for this reason" ;
VAL_ 2364612350 ThreePLDueToHiSideVMax 3 "Not Available" 2 "Error" 1 "Power limited for this reason" 0 "No power limit for this reason" ;
VAL_ 2364612350 ThreePLDueToHiSideVMin 3 "Not Available" 2 "Error" 1 "Power limited for this reason" 0 "No power limit for this reason" ;
VAL_ 2364612350 ThreePLDueToLowSideCur 3 "Not Available" 2 "Error" 1 "Power limited for this reason" 0 "No power limit for this reason" ;
VAL_ 2364612350 ThreePLDueToHiSideCur 3 "Not Available" 2 "Error" 1 "Power limited for this reason" 0 "No power limit for this reason" ;
VAL_ 2364612350 ThreeLoadshedReq 3 "Don't Care/Take No Action" 2 "Loadshed Requested,  Shutdown Imminent" 1 "Loadshed Requested" 0 "No Loadshed Requested" ;
VAL_ 2364612350 ThreeHVILStatus 3 "Not Available" 2 "Error" 1 "HVIL Open" 0 "HVIL Closed" ;
VAL_ 2364612350 ThreeOperationalStatus 15 "Not Available" 14 "Error" 13 "Manufacturer assignable state" 12 "Reserved" 11 "Reserved" 10 "Reserved" 9 "Reserved" 8 "Reserved" 7 "Reserved" 6 "Disabled due to malfunction or protection" 5 "Normal power down in process" 4 "Operational, Boost mode" 3 "Operational, Buck mode" 2 "Operational, Standby" 1 "Initialization in process" 0 "Disabled" ;
VAL_ 2364612094 ThreeOperationalCmd 15 "Don't care/ Take No Action" 13 "Reserved" 12 "Reserved" 11 "Reserved" 10 "Reserved" 9 "Reserved" 8 "Reserved" 7 "Reserved" 6 "Reserved" 5 "Reserved" 4 "Power down DC/DC Converter" 3 "Operate in boost mode" 2 "Operate in buck mode" 1 "Operate in standby mode" 0 "Disable" ;
VAL_ 2364611070 TwoPLDueToUndefinedReason 3 "Not Available" 2 "Error" 1 "Power limited for this reason" 0 "No power limit for this reason" ;
VAL_ 2364611070 TwoPLDueToSLIBatTermTemp 3 "Not Available" 2 "Error" 1 "Power limited for this reason" 0 "No power limit for this reason" ;
VAL_ 2364611070 TwoPLDueToSLIBatTermCur 3 "Not Available" 2 "Error" 1 "Power limited for this reason" 0 "No power limit for this reason" ;
VAL_ 2364611070 TwoPLDueToSLIBatTermV 3 "Not Available" 2 "Error" 1 "Power limited for this reason" 0 "No power limit for this reason" ;
VAL_ 2364611070 TwoPLDueToPwrETemp 3 "Not Available" 2 "Error" 1 "Power limited for this reason" 0 "No power limit for this reason" ;
VAL_ 2364611070 TwoPLDueToEFilterTemp 3 "Not available" 2 "Error" 1 "Power limited for this reason" 0 "No power limit for this reason" ;
VAL_ 2364611070 TwoPLDueToConvTemp 3 "Not Available" 2 "Error" 1 "Power limited for this reason" 0 "No power limit for this reason" ;
VAL_ 2364611070 TwoPLDueToLowSideVMax 3 "Not Available" 2 "Error" 1 "Power limited for this reason" 0 "No power limit for this reason" ;
VAL_ 2364611070 TwoPLDueToLowSideVMin 3 "Not Available" 2 "Error" 1 "Power limited for this reason" 0 "No power limit for this reason" ;
VAL_ 2364611070 TwoPLDueToHiSideVMax 3 "Not Available" 2 "Error" 1 "Power limited for this reason" 0 "No power limit for this reason" ;
VAL_ 2364611070 TwoPLDueToHiSideVMin 3 "Not Available" 2 "Error" 1 "Power limited for this reason" 0 "No power limit for this reason" ;
VAL_ 2364611070 TwoPLDueToLowSideCur 3 "Not Available" 2 "Error" 1 "Power limited for this reason" 0 "No power limit for this reason" ;
VAL_ 2364611070 TwoPLDueToHiSideCur 3 "Not Available" 2 "Error" 1 "Power limited for this reason" 0 "No power limit for this reason" ;
VAL_ 2364611070 TwoLoadshedReq 3 "Don't Care/Take No Action" 2 "Loadshed Requested,  Shutdown Imminent" 1 "Loadshed Requested" 0 "No Loadshed Requested" ;
VAL_ 2364611070 TwoHVILStatus 3 "Not Available" 2 "Error" 1 "HVIL Open" 0 "HVIL Closed" ;
VAL_ 2364611070 TwoOperationalStatus 15 "Not Available" 14 "Error" 13 "Manufacturer assignable state" 12 "Reserved" 11 "Reserved" 10 "Reserved" 9 "Reserved" 8 "Reserved" 7 "Reserved" 6 "Disabled due to malfunction or protection" 5 "Normal power down in process" 4 "Operational, Boost mode" 3 "Operational, Buck mode" 2 "Operational, Standby" 1 "Initialization in process" 0 "Disabled" ;
VAL_ 2364610814 TwoOperationalCmd 11 "Reserved" 10 "Reserved" 9 "Reserved" 8 "Reserved" 7 "Reserved" 6 "Reserved" 5 "Reserved" 4 "Power down DC/DC Converter" 3 "Operate in boost mode" 2 "Operate in buck mode" 15 "Don't care/ Take No Action" 13 "Reserved" 12 "Reserved" 1 "Operate in standby mode" 0 "Disable" ;
VAL_ 2565918206 PLedDueToUndefinedReason 3 "Not Available" 2 "Error" 1 "Power limited for this reason" 0 "No power limit for this reason" ;
VAL_ 2565918206 PLedDueToRateOfChangeLmt 3 "Not Available" 2 "Error" 1 "Power limited for this reason" 0 "No power limit for this reason" ;
VAL_ 2565918206 PLedDueToPwrETemp 3 "Not Available" 2 "Error" 1 "Power limited for this reason" 0 "No power limit for this reason" ;
VAL_ 2565918206 PLedDueToEFilterTemp 3 "Not Available" 2 "Error" 1 "Power limited for this reason" 0 "No power limit for this reason" ;
VAL_ 2565918206 PLedDueToCtrlTemp 3 "Not Available" 2 "Error" 1 "Power limited for this reason" 0 "No power limit for this reason" ;
VAL_ 2565918206 FreqCmdExceedsMax 3 "Not Available" 2 "Error" 1 "Frequency limited for this reason" 0 "No frequency limit for this reason" ;
VAL_ 2565918206 FreqCmdBelowMin 3 "Not Available" 2 "Error" 1 "Frequency limited for this reason" 0 "No frequency limit for this reason" ;
VAL_ 2565918206 PLedDueToDCSideVMin 3 "Not Available" 2 "Error" 1 "Power limited for this reason" 0 "No power limit for this reason" ;
VAL_ 2565918206 PLedDueToACSideRMSCur 3 "Not Available" 2 "Error" 1 "Power limited for this reason" 0 "No power limit for this reason" ;
VAL_ 2565918206 PLedDueToDCSideCur 3 "Not Available" 2 "Error" 1 "Power limited for this reason" 0 "No power limit for this reason" ;
